[part 2 of 2: packages /SVC_DEF_Hierarchy/SVC_eBstActrSecDef/AppDataType to /Topologies/SDV/ImplementationTypes]
AUTOSAR XML (schema 00049)
package /SVC_DEF_Hierarchy/SVC_eBstActrSecDef/AppDataType
  application array data type VaBACR_y_UpIntegrationOutputS_VaBACR_y_UpIntegrationOutputS: category=ARRAY
    element hSVC_eBstActrSecVaBACR_y_UpIntegrationOutputS_D0S150: category=VALUE, type=BYTE, max-number-of-elements=150
  21 x app type, all with category=VALUE:
    hSVC_eBstActrSec_evt_VeBACR_e_PrimDiagStStsS_TeBACR_e_DiagStSts_SvcAppEnum
    hSVC_eBstActrSec_evt_VeBACR_e_SbmPrimDiagStStsS_TeBACR_e_SbmDiagStSts_SvcAppEnum
    hSVC_eBstActrSec_evt_VeBACR_e_eBstEPB_AchModeLtS_TeBACR_e_EPB_AchMode_SvcAppEnum
    hSVC_eBstActrSec_evt_VeBACR_e_eBstEPB_AchModeRtS_TeBACR_e_EPB_AchMode_SvcAppEnum
    hSVC_eBstActrSec_evt_VeBACR_e_eBstEPB_StateLtS_TeBACR_e_EPB_State_SvcAppEnum
    hSVC_eBstActrSec_evt_VeBACR_e_eBstEPB_StateRtS_TeBACR_e_EPB_State_SvcAppEnum
    hSVC_eBstActrSec_evt_VeBACR_e_eBstFluidLvlRawS_TeBACR_e_BrkFluidLvl_SvcAppEnum
    hSVC_eBstActrSec_evt_VeBACR_e_eBstHydFuncStS_TeBACR_e_eBstHydState_SvcAppEnum
    hSVC_eBstActrSec_evt_VeBACR_e_eBstIntrSelfTstStsS_TeBACR_e_IntrSelfTstSts_SvcAppEnum
    hSVC_eBstActrSec_evt_VeBACR_e_eBstMC_StsS_TeBACR_e_VldTrvlSnsrs_SvcAppEnum
    hSVC_eBstActrSec_evt_VeBACR_e_eBstPCanCommStsS_TeBACR_e_PCanCommSts_SvcAppEnum
    hSVC_eBstActrSec_evt_VeBACR_e_eBstPlngrPosnStsS_TeBPRR_e_ActPosnSts_SvcAppEnum
    hSVC_eBstActrSec_evt_VeBACR_e_eBstRplnshStsS_TeBACR_e_RplnshSts_SvcAppEnum
    hSVC_eBstActrSec_evt_VeBACR_e_eBstVDA_PbcHPO_ReqS_TeBACR_e_VDA_PbcHPO_Req_SvcAppEnum
    hSVC_eBstActrSec_evt_VeBACR_e_eBstWhlCntrlStsLfS_TeBACR_e_WhlCntrlSts_SvcAppEnum
    hSVC_eBstActrSec_evt_VeBACR_e_eBstWhlCntrlStsLrS_TeBACR_e_WhlCntrlSts_SvcAppEnum
    hSVC_eBstActrSec_evt_VeBACR_e_eBstWhlCntrlStsRfS_TeBACR_e_WhlCntrlSts_SvcAppEnum
    hSVC_eBstActrSec_evt_VeBACR_e_eBstWhlCntrlStsRrS_TeBACR_e_WhlCntrlSts_SvcAppEnum
    hSVC_eBstActrSec_evt_YeBACR_e_eBstEBOS_EBCMStateS_TeBACR_e_EBOS_EBCM_State_SvcAppEnum
    hSVC_eBstActrSec_evt_YeBACR_e_eBstEPB_StatusLtS_TeBACR_e_EPB_Status_SvcAppEnum
    hSVC_eBstActrSec_evt_YeBACR_e_eBstEPB_StatusRtS_TeBACR_e_EPB_Status_SvcAppEnum
  application record data type hSVC_eBstActrSec_evt_EventAppType: category=STRUCTURE
    116 x application record element:
      VeBACR_b_eBstWS_InvLrS: category=VALUE, type=TbBOOLEAN
      VeBACR_Cnt_eBstWS_TmD3_RrS: category=VALUE, type=T_COUNT_WORD
      VeBACR_b_eBstWS_InvLfS: category=VALUE, type=TbBOOLEAN
      VeBACR_Cnt_eBstWS_PulsRfS: category=VALUE, type=T_COUNT_WORD
      VeBACR_Cnt_eBstWS_VdaBitsLrS: category=VALUE, type=T_COUNT_BYTE
      VeBACR_Cnt_eBstWS_TmRfS: category=VALUE, type=T_COUNT_LONG
      VeBACR_Cnt_eBstWS_VdaBitsRfS: category=VALUE, type=T_COUNT_BYTE
      VeBACR_e_eBstEPB_StateLtS: category=VALUE, type=hSVC_eBstActrSec_evt_VeBACR_e_eBstEPB_StateLtS_TeBACR_e_EPB_State_SvcAppEnum
      VeBACR_b_eBstWS_InvRfS: category=VALUE, type=TbBOOLEAN
      VeBACR_e_eBstEPB_AchModeLtS: category=VALUE, type=hSVC_eBstActrSec_evt_VeBACR_e_eBstEPB_AchModeLtS_TeBACR_e_EPB_AchMode_SvcAppEnum
      VeBACR_Cnt_eBstWS_TmD1_LrS: category=VALUE, type=T_COUNT_WORD
      VeBACR_d_eBstWS_VdaBitsRfS: category=VALUE, type=WORD
      VeBACR_l_eBstPlngrPosnS: category=VALUE, type=T_l_Millimeters
      VeBACR_d_eBstWS_VdaBitsLrS: category=VALUE, type=WORD
      VeBACR_Cnt_eBstWS_TmRrS: category=VALUE, type=T_COUNT_LONG
      VeBACR_e_eBstEPB_StateRtS: category=VALUE, type=hSVC_eBstActrSec_evt_VeBACR_e_eBstEPB_StateRtS_TeBACR_e_EPB_State_SvcAppEnum
      VeBACR_p_eBstBkPrsEstRrS: category=VALUE, type=T_p_bar
      VeBACR_Cnt_eBstWS_PulsLrS: category=VALUE, type=T_COUNT_WORD
      VeBACR_e_eBstMC_StsS: category=VALUE, type=hSVC_eBstActrSec_evt_VeBACR_e_eBstMC_StsS_TeBACR_e_VldTrvlSnsrs_SvcAppEnum
      VeBACR_F_eBstEPB_AchvdRtS: category=VALUE, type=T_F_Newtons
      YeBACR_e_eBstEBOS_EBCMStateS: category=VALUE, type=hSVC_eBstActrSec_evt_YeBACR_e_eBstEBOS_EBCMStateS_TeBACR_e_EBOS_EBCM_State_SvcAppEnum
      VeBACR_b_eBstWS_StndStllLrS: category=VALUE, type=TbBOOLEAN
      VeBACR_Cnt_eBstWS_TmD2_RrS: category=VALUE, type=T_COUNT_WORD
      VeBACR_e_eBstIntrSelfTstStsS: category=VALUE, type=hSVC_eBstActrSec_evt_VeBACR_e_eBstIntrSelfTstStsS_TeBACR_e_IntrSelfTstSts_SvcAppEnum
      VeBACR_Cnt_eBstWS_TmLfS: category=VALUE, type=T_COUNT_LONG
      VeBACR_Cnt_eBstWS_PulsLfS: category=VALUE, type=T_COUNT_WORD
      VeBACR_e_eBstFluidLvlRawS: category=VALUE, type=hSVC_eBstActrSec_evt_VeBACR_e_eBstFluidLvlRawS_TeBACR_e_BrkFluidLvl_SvcAppEnum
      VeBACR_d_eBstWS_VdaBitsLfS: category=VALUE, type=WORD
      VeBACR_e_eBstPlngrPosnStsS: category=VALUE, type=hSVC_eBstActrSec_evt_VeBACR_e_eBstPlngrPosnStsS_TeBPRR_e_ActPosnSts_SvcAppEnum
      VeBACR_Cnt_eBstWS_TmD3_LrS: category=VALUE, type=T_COUNT_WORD
      VeBACR_l_eBstMCS: category=VALUE, type=T_l_Millimeters
      VeBACR_p_eBstMC_AchvdS: category=VALUE, type=T_p_bar
      VeBACR_b_eBst_BstWthWarningS: category=VALUE, type=TbBOOLEAN
      VeBACR_b_eBstPwrMgmtActS: category=VALUE, type=TbBOOLEAN
      VeBACR_Cnt_eBstWS_TmD2_LrS: category=VALUE, type=T_COUNT_WORD
      VeBACR_b_eBstWS_InvRrS: category=VALUE, type=TbBOOLEAN
      VeBACR_Cnt_eBstWS_PulsRrS: category=VALUE, type=T_COUNT_WORD
      VeBACR_p_eBstBkPrsEstLrS: category=VALUE, type=T_p_bar
      VeBACR_p_eBstBkPrsEstLfS: category=VALUE, type=T_p_bar
      VeBACR_Cnt_eBstWS_TmD1_RfS: category=VALUE, type=T_COUNT_WORD
      VeBACR_F_eBstEPB_AchvdLtS: category=VALUE, type=T_F_Newtons
      VeBACR_b_eBstWS_StndStllRfS: category=VALUE, type=TbBOOLEAN
      VeBACR_Cnt_eBstWS_TmD1_LfS: category=VALUE, type=T_COUNT_WORD
      VeBACR_b_eBstBC_AchvdInvS: category=VALUE, type=TbBOOLEAN
      VeBACR_b_eBstDgrdDBRReqstdS: category=VALUE, type=TbBOOLEAN
      VeBACR_Cnt_eBstWS_TmD2_LfS: category=VALUE, type=T_COUNT_WORD
      VeBACR_b_eBstWS_StndStllRrS: category=VALUE, type=TbBOOLEAN
      VeBACR_b_eBstWS_StndStllLfS: category=VALUE, type=TbBOOLEAN
      VeBACR_Cnt_eBstWS_TmD2_RfS: category=VALUE, type=T_COUNT_WORD
      VeBACR_p_eBstBkPrsEstRfS: category=VALUE, type=T_p_bar
      VeBACR_d_eBstWS_VdaBitsRrS: category=VALUE, type=WORD
      VeBACR_e_eBstEPB_AchModeRtS: category=VALUE, type=hSVC_eBstActrSec_evt_VeBACR_e_eBstEPB_AchModeRtS_TeBACR_e_EPB_AchMode_SvcAppEnum
      VeBACR_Cnt_eBstWS_TmD3_RfS: category=VALUE, type=T_COUNT_WORD
      VeBACR_Cnt_eBstWS_TmLrS: category=VALUE, type=T_COUNT_LONG
      VeBACR_d_eBstPwrMgmtRsnS: category=VALUE, type=WORD
      VeBACR_Cnt_eBstWS_TmD3_LfS: category=VALUE, type=T_COUNT_WORD
      VeBACR_b_eBstMC_AchvdInvS: category=VALUE, type=TbBOOLEAN
      YeBACR_Pct_eBstThermalCapS: category=VALUE, type=T_Pct_Percent
      VeBACR_Cnt_eBstWS_TmD1_RrS: category=VALUE, type=T_COUNT_WORD
      VeBACR_Cnt_eBstWS_VdaBitsRrS: category=VALUE, type=T_COUNT_BYTE
      VeBACR_Cnt_eBstWS_VdaBitsLfS: category=VALUE, type=T_COUNT_BYTE
      VeBACR_p_eBstBC_AchvdS: category=VALUE, type=T_p_bar
      VeBACR_Cnt_eBstWS_TmD8_RfS: category=VALUE, type=T_COUNT_WORD
      VeBACR_Cnt_eBstWS_TmD7_RrS: category=VALUE, type=T_COUNT_WORD
      VeBACR_b_eBstBrkActCurr2FA_S: category=VALUE, type=TbBOOLEAN
      VeBACR_U_eBstBrkActVolt2_S: category=VALUE, type=T_U_Volts
      VeBACR_Cnt_eBstWS_TmD8_LrS: category=VALUE, type=T_COUNT_WORD
      VeBACR_Cnt_eBstWS_TmD7_LfS: category=VALUE, type=T_COUNT_WORD
      VeBACR_Cnt_eBstWS_TmD4_LrS: category=VALUE, type=T_COUNT_WORD
      VeBACR_Cnt_eBstWS_TmD6_RfS: category=VALUE, type=T_COUNT_WORD
      VeBACR_Cnt_eBstWS_TmD5_RrS: category=VALUE, type=T_COUNT_WORD
      VeBACR_Cnt_eBstWS_TmD4_RfS: category=VALUE, type=T_COUNT_WORD
      VeBACR_Cnt_eBstWS_TmD6_LrS: category=VALUE, type=T_COUNT_WORD
      VeBACR_Cnt_eBstWS_TmD5_LfS: category=VALUE, type=T_COUNT_WORD
      VeBACR_b_eBstBrkActVolt2FA_S: category=VALUE, type=TbBOOLEAN
      VeBACR_U_eBstBrkActVolt1_S: category=VALUE, type=T_U_Volts
      VeBACR_Cnt_eBstWS_TmD7_LrS: category=VALUE, type=T_COUNT_WORD
      VeBACR_Cnt_eBstWS_TmD8_LfS: category=VALUE, type=T_COUNT_WORD
      VeBACR_Cnt_eBstWS_TmD7_RfS: category=VALUE, type=T_COUNT_WORD
      VeBACR_Cnt_eBstWS_TmD8_RrS: category=VALUE, type=T_COUNT_WORD
      VeBACR_b_eBstBrkActCurr1FA_S: category=VALUE, type=TbBOOLEAN
      VeBACR_I_eBstBrkActCurr2_S: category=VALUE, type=T_I_Amps
      VeBACR_Cnt_eBstWS_TmD4_RrS: category=VALUE, type=T_COUNT_WORD
      VeBACR_Cnt_eBstWS_TmD5_LrS: category=VALUE, type=T_COUNT_WORD
      VeBACR_Cnt_eBstWS_TmD6_LfS: category=VALUE, type=T_COUNT_WORD
      VeBACR_Cnt_eBstWS_TmD4_LfS: category=VALUE, type=T_COUNT_WORD
      VeBACR_Cnt_eBstWS_TmD6_RrS: category=VALUE, type=T_COUNT_WORD
      VeBACR_Cnt_eBstWS_TmD5_RfS: category=VALUE, type=T_COUNT_WORD
      VeBACR_b_eBstBrkActVolt1FA_S: category=VALUE, type=TbBOOLEAN
      VeBACR_b_eBstLeakModeActvS: category=VALUE, type=TbBOOLEAN
      VeBACR_b_eBstRecoveryActvS: category=VALUE, type=TbBOOLEAN
      VeBACR_I_eBstBrkActCurr1_S: category=VALUE, type=T_I_Amps
      VeBACR_V_eBstPotPlngrVolS: category=VALUE, type=T_V_Millimeters3
      VeBACR_e_eBstRplnshStsS: category=VALUE, type=hSVC_eBstActrSec_evt_VeBACR_e_eBstRplnshStsS_TeBACR_e_RplnshSts_SvcAppEnum
      VeBACR_V_eBstRemPlngrVolS: category=VALUE, type=T_V_Millimeters3
      VeBACR_p_eBstVDA_PbcHPO_S: category=VALUE, type=T_p_bar
      VeBACR_e_eBstVDA_PbcHPO_ReqS: category=VALUE, type=hSVC_eBstActrSec_evt_VeBACR_e_eBstVDA_PbcHPO_ReqS_TeBACR_e_VDA_PbcHPO_Req_SvcAppEnum
      VeBACR_e_eBstHydFuncStS: category=VALUE, type=hSVC_eBstActrSec_evt_VeBACR_e_eBstHydFuncStS_TeBACR_e_eBstHydState_SvcAppEnum
      YeBACR_b_eBst_BstUnavlblS: category=VALUE, type=TbBOOLEAN
      VeBACR_d_eBstEBCM_SwVerAlphS: category=VALUE, type=WORD
      VeBACR_g_eBstEBCM_SwVerPN_S: category=VALUE, type=LONGWORD
      VeBACR_b_eBstPCanCommStsS: category=VALUE, type=TbBOOLEAN
      VeBACR_V_eBstHydCmpOffstVolS: category=VALUE, type=T_V_Millimeters3
      VaBACR_y_UpIntegrationOutputS: category=ARRAY, type=VaBACR_y_UpIntegrationOutputS_VaBACR_y_UpIntegrationOutputS
      VeBACR_e_SbmPrimDiagStStsS: category=VALUE, type=hSVC_eBstActrSec_evt_VeBACR_e_SbmPrimDiagStStsS_TeBACR_e_SbmDiagStSts_SvcAppEnum
      VeBACR_e_eBstWhlCntrlStsLfS: category=VALUE, type=hSVC_eBstActrSec_evt_VeBACR_e_eBstWhlCntrlStsLfS_TeBACR_e_WhlCntrlSts_SvcAppEnum
      YeBACR_e_eBstEPB_StatusRtS: category=VALUE, type=hSVC_eBstActrSec_evt_YeBACR_e_eBstEPB_StatusRtS_TeBACR_e_EPB_Status_SvcAppEnum
      VeBACR_e_eBstWhlCntrlStsRrS: category=VALUE, type=hSVC_eBstActrSec_evt_VeBACR_e_eBstWhlCntrlStsRrS_TeBACR_e_WhlCntrlSts_SvcAppEnum
      VeBACR_e_eBstWhlCntrlStsLrS: category=VALUE, type=hSVC_eBstActrSec_evt_VeBACR_e_eBstWhlCntrlStsLrS_TeBACR_e_WhlCntrlSts_SvcAppEnum
      VeBACR_b_MIL_ReqFromEBCM_S: category=VALUE, type=TbBOOLEAN
      VeBACR_e_eBstWhlCntrlStsRfS: category=VALUE, type=hSVC_eBstActrSec_evt_VeBACR_e_eBstWhlCntrlStsRfS_TeBACR_e_WhlCntrlSts_SvcAppEnum
      YeBACR_e_eBstEPB_StatusLtS: category=VALUE, type=hSVC_eBstActrSec_evt_YeBACR_e_eBstEPB_StatusLtS_TeBACR_e_EPB_Status_SvcAppEnum
      VeBACR_e_PrimDiagStStsS: category=VALUE, type=hSVC_eBstActrSec_evt_VeBACR_e_PrimDiagStStsS_TeBACR_e_DiagStSts_SvcAppEnum
      VeBACR_e_eBstPCanCommStsS: category=VALUE, type=hSVC_eBstActrSec_evt_VeBACR_e_eBstPCanCommStsS_TeBACR_e_PCanCommSts_SvcAppEnum
      VeBACR_b_eBstPanicBrkAppActS: category=VALUE, type=TbBOOLEAN
      VeBACR_b_ThermalCapInvS: category=VALUE, type=TbBOOLEAN
package /SVC_DEF_Hierarchy/SVC_eBstActrSecDef/ImpDataType
  22 x impl type:
    hSVC_eBstActrSec_evt_EventImpType: category=STRUCTURE
      116 x element:
        VeBACR_b_eBstWS_InvLrS: implementation-data-type=TbBOOLEAN
        VeBACR_Cnt_eBstWS_TmD3_RrS: implementation-data-type=T_COUNT_WORD
        VeBACR_b_eBstWS_InvLfS: implementation-data-type=TbBOOLEAN
        VeBACR_Cnt_eBstWS_PulsRfS: implementation-data-type=T_COUNT_WORD
        VeBACR_Cnt_eBstWS_VdaBitsLrS: implementation-data-type=T_COUNT_BYTE
        VeBACR_Cnt_eBstWS_TmRfS: implementation-data-type=T_COUNT_LONG
        VeBACR_Cnt_eBstWS_VdaBitsRfS: implementation-data-type=T_COUNT_BYTE
        VeBACR_e_eBstEPB_StateLtS: implementation-data-type=hSVC_eBstActrSec_evt_VeBACR_e_eBstEPB_StateLtS_TeBACR_e_EPB_State_SvcEnum
        VeBACR_b_eBstWS_InvRfS: implementation-data-type=TbBOOLEAN
        VeBACR_e_eBstEPB_AchModeLtS: implementation-data-type=hSVC_eBstActrSec_evt_VeBACR_e_eBstEPB_AchModeLtS_TeBACR_e_EPB_AchMode_SvcEnum
        VeBACR_Cnt_eBstWS_TmD1_LrS: implementation-data-type=T_COUNT_WORD
        VeBACR_d_eBstWS_VdaBitsRfS: implementation-data-type=WORD
        VeBACR_l_eBstPlngrPosnS: implementation-data-type=T_l_Millimeters
        VeBACR_d_eBstWS_VdaBitsLrS: implementation-data-type=WORD
        VeBACR_Cnt_eBstWS_TmRrS: implementation-data-type=T_COUNT_LONG
        VeBACR_e_eBstEPB_StateRtS: implementation-data-type=hSVC_eBstActrSec_evt_VeBACR_e_eBstEPB_StateRtS_TeBACR_e_EPB_State_SvcEnum
        VeBACR_p_eBstBkPrsEstRrS: implementation-data-type=T_p_bar
        VeBACR_Cnt_eBstWS_PulsLrS: implementation-data-type=T_COUNT_WORD
        VeBACR_e_eBstMC_StsS: implementation-data-type=hSVC_eBstActrSec_evt_VeBACR_e_eBstMC_StsS_TeBACR_e_VldTrvlSnsrs_SvcEnum
        VeBACR_F_eBstEPB_AchvdRtS: implementation-data-type=T_F_Newtons
        YeBACR_e_eBstEBOS_EBCMStateS: implementation-data-type=hSVC_eBstActrSec_evt_YeBACR_e_eBstEBOS_EBCMStateS_TeBACR_e_EBOS_EBCM_State_SvcEnum
        VeBACR_b_eBstWS_StndStllLrS: implementation-data-type=TbBOOLEAN
        VeBACR_Cnt_eBstWS_TmD2_RrS: implementation-data-type=T_COUNT_WORD
        VeBACR_e_eBstIntrSelfTstStsS: implementation-data-type=hSVC_eBstActrSec_evt_VeBACR_e_eBstIntrSelfTstStsS_TeBACR_e_IntrSelfTstSts_SvcEnum
        VeBACR_Cnt_eBstWS_TmLfS: implementation-data-type=T_COUNT_LONG
        VeBACR_Cnt_eBstWS_PulsLfS: implementation-data-type=T_COUNT_WORD
        VeBACR_e_eBstFluidLvlRawS: implementation-data-type=hSVC_eBstActrSec_evt_VeBACR_e_eBstFluidLvlRawS_TeBACR_e_BrkFluidLvl_SvcEnum
        VeBACR_d_eBstWS_VdaBitsLfS: implementation-data-type=WORD
        VeBACR_e_eBstPlngrPosnStsS: implementation-data-type=hSVC_eBstActrSec_evt_VeBACR_e_eBstPlngrPosnStsS_TeBPRR_e_ActPosnSts_SvcEnum
        VeBACR_Cnt_eBstWS_TmD3_LrS: implementation-data-type=T_COUNT_WORD
        VeBACR_l_eBstMCS: implementation-data-type=T_l_Millimeters
        VeBACR_p_eBstMC_AchvdS: implementation-data-type=T_p_bar
        VeBACR_b_eBst_BstWthWarningS: implementation-data-type=TbBOOLEAN
        VeBACR_b_eBstPwrMgmtActS: implementation-data-type=TbBOOLEAN
        VeBACR_Cnt_eBstWS_TmD2_LrS: implementation-data-type=T_COUNT_WORD
        VeBACR_b_eBstWS_InvRrS: implementation-data-type=TbBOOLEAN
        VeBACR_Cnt_eBstWS_PulsRrS: implementation-data-type=T_COUNT_WORD
        VeBACR_p_eBstBkPrsEstLrS: implementation-data-type=T_p_bar
        VeBACR_p_eBstBkPrsEstLfS: implementation-data-type=T_p_bar
        VeBACR_Cnt_eBstWS_TmD1_RfS: implementation-data-type=T_COUNT_WORD
        VeBACR_F_eBstEPB_AchvdLtS: implementation-data-type=T_F_Newtons
        VeBACR_b_eBstWS_StndStllRfS: implementation-data-type=TbBOOLEAN
        VeBACR_Cnt_eBstWS_TmD1_LfS: implementation-data-type=T_COUNT_WORD
        VeBACR_b_eBstBC_AchvdInvS: implementation-data-type=TbBOOLEAN
        VeBACR_b_eBstDgrdDBRReqstdS: implementation-data-type=TbBOOLEAN
        VeBACR_Cnt_eBstWS_TmD2_LfS: implementation-data-type=T_COUNT_WORD
        VeBACR_b_eBstWS_StndStllRrS: implementation-data-type=TbBOOLEAN
        VeBACR_b_eBstWS_StndStllLfS: implementation-data-type=TbBOOLEAN
        VeBACR_Cnt_eBstWS_TmD2_RfS: implementation-data-type=T_COUNT_WORD
        VeBACR_p_eBstBkPrsEstRfS: implementation-data-type=T_p_bar
        VeBACR_d_eBstWS_VdaBitsRrS: implementation-data-type=WORD
        VeBACR_e_eBstEPB_AchModeRtS: implementation-data-type=hSVC_eBstActrSec_evt_VeBACR_e_eBstEPB_AchModeRtS_TeBACR_e_EPB_AchMode_SvcEnum
        VeBACR_Cnt_eBstWS_TmD3_RfS: implementation-data-type=T_COUNT_WORD
        VeBACR_Cnt_eBstWS_TmLrS: implementation-data-type=T_COUNT_LONG
        VeBACR_d_eBstPwrMgmtRsnS: implementation-data-type=WORD
        VeBACR_Cnt_eBstWS_TmD3_LfS: implementation-data-type=T_COUNT_WORD
        VeBACR_b_eBstMC_AchvdInvS: implementation-data-type=TbBOOLEAN
        YeBACR_Pct_eBstThermalCapS: implementation-data-type=T_Pct_Percent
        VeBACR_Cnt_eBstWS_TmD1_RrS: implementation-data-type=T_COUNT_WORD
        VeBACR_Cnt_eBstWS_VdaBitsRrS: implementation-data-type=T_COUNT_BYTE
        VeBACR_Cnt_eBstWS_VdaBitsLfS: implementation-data-type=T_COUNT_BYTE
        VeBACR_p_eBstBC_AchvdS: implementation-data-type=T_p_bar
        VeBACR_Cnt_eBstWS_TmD8_RfS: implementation-data-type=T_COUNT_WORD
        VeBACR_Cnt_eBstWS_TmD7_RrS: implementation-data-type=T_COUNT_WORD
        VeBACR_b_eBstBrkActCurr2FA_S: implementation-data-type=TbBOOLEAN
        VeBACR_U_eBstBrkActVolt2_S: implementation-data-type=T_U_Volts
        VeBACR_Cnt_eBstWS_TmD8_LrS: implementation-data-type=T_COUNT_WORD
        VeBACR_Cnt_eBstWS_TmD7_LfS: implementation-data-type=T_COUNT_WORD
        VeBACR_Cnt_eBstWS_TmD4_LrS: implementation-data-type=T_COUNT_WORD
        VeBACR_Cnt_eBstWS_TmD6_RfS: implementation-data-type=T_COUNT_WORD
        VeBACR_Cnt_eBstWS_TmD5_RrS: implementation-data-type=T_COUNT_WORD
        VeBACR_Cnt_eBstWS_TmD4_RfS: implementation-data-type=T_COUNT_WORD
        VeBACR_Cnt_eBstWS_TmD6_LrS: implementation-data-type=T_COUNT_WORD
        VeBACR_Cnt_eBstWS_TmD5_LfS: implementation-data-type=T_COUNT_WORD
        VeBACR_b_eBstBrkActVolt2FA_S: implementation-data-type=TbBOOLEAN
        VeBACR_U_eBstBrkActVolt1_S: implementation-data-type=T_U_Volts
        VeBACR_Cnt_eBstWS_TmD7_LrS: implementation-data-type=T_COUNT_WORD
        VeBACR_Cnt_eBstWS_TmD8_LfS: implementation-data-type=T_COUNT_WORD
        VeBACR_Cnt_eBstWS_TmD7_RfS: implementation-data-type=T_COUNT_WORD
        VeBACR_Cnt_eBstWS_TmD8_RrS: implementation-data-type=T_COUNT_WORD
        VeBACR_b_eBstBrkActCurr1FA_S: implementation-data-type=TbBOOLEAN
        VeBACR_I_eBstBrkActCurr2_S: implementation-data-type=T_I_Amps
        VeBACR_Cnt_eBstWS_TmD4_RrS: implementation-data-type=T_COUNT_WORD
        VeBACR_Cnt_eBstWS_TmD5_LrS: implementation-data-type=T_COUNT_WORD
        VeBACR_Cnt_eBstWS_TmD6_LfS: implementation-data-type=T_COUNT_WORD
        VeBACR_Cnt_eBstWS_TmD4_LfS: implementation-data-type=T_COUNT_WORD
        VeBACR_Cnt_eBstWS_TmD6_RrS: implementation-data-type=T_COUNT_WORD
        VeBACR_Cnt_eBstWS_TmD5_RfS: implementation-data-type=T_COUNT_WORD
        VeBACR_b_eBstBrkActVolt1FA_S: implementation-data-type=TbBOOLEAN
        VeBACR_b_eBstLeakModeActvS: implementation-data-type=TbBOOLEAN
        VeBACR_b_eBstRecoveryActvS: implementation-data-type=TbBOOLEAN
        VeBACR_I_eBstBrkActCurr1_S: implementation-data-type=T_I_Amps
        VeBACR_V_eBstPotPlngrVolS: implementation-data-type=T_V_Millimeters3
        VeBACR_e_eBstRplnshStsS: implementation-data-type=hSVC_eBstActrSec_evt_VeBACR_e_eBstRplnshStsS_TeBACR_e_RplnshSts_SvcEnum
        VeBACR_V_eBstRemPlngrVolS: implementation-data-type=T_V_Millimeters3
        VeBACR_p_eBstVDA_PbcHPO_S: implementation-data-type=T_p_bar
        VeBACR_e_eBstVDA_PbcHPO_ReqS: implementation-data-type=hSVC_eBstActrSec_evt_VeBACR_e_eBstVDA_PbcHPO_ReqS_TeBACR_e_VDA_PbcHPO_Req_SvcEnum
        VeBACR_e_eBstHydFuncStS: implementation-data-type=hSVC_eBstActrSec_evt_VeBACR_e_eBstHydFuncStS_TeBACR_e_eBstHydState_SvcEnum
        YeBACR_b_eBst_BstUnavlblS: implementation-data-type=TbBOOLEAN
        VeBACR_d_eBstEBCM_SwVerAlphS: implementation-data-type=WORD
        VeBACR_g_eBstEBCM_SwVerPN_S: implementation-data-type=LONGWORD
        VeBACR_b_eBstPCanCommStsS: implementation-data-type=TbBOOLEAN
        VeBACR_V_eBstHydCmpOffstVolS: implementation-data-type=T_V_Millimeters3
        VaBACR_y_UpIntegrationOutputS: category=ARRAY
          element hSVC_eBstActrSecVaBACR_y_UpIntegrationOutputS_D0S150: array-size=150, implementation-data-type=BYTE
        VeBACR_e_SbmPrimDiagStStsS: implementation-data-type=hSVC_eBstActrSec_evt_VeBACR_e_SbmPrimDiagStStsS_TeBACR_e_SbmDiagStSts_SvcEnum
        VeBACR_e_eBstWhlCntrlStsLfS: implementation-data-type=hSVC_eBstActrSec_evt_VeBACR_e_eBstWhlCntrlStsLfS_TeBACR_e_WhlCntrlSts_SvcEnum
        YeBACR_e_eBstEPB_StatusRtS: implementation-data-type=hSVC_eBstActrSec_evt_YeBACR_e_eBstEPB_StatusRtS_TeBACR_e_EPB_Status_SvcEnum
        VeBACR_e_eBstWhlCntrlStsRrS: implementation-data-type=hSVC_eBstActrSec_evt_VeBACR_e_eBstWhlCntrlStsRrS_TeBACR_e_WhlCntrlSts_SvcEnum
        VeBACR_e_eBstWhlCntrlStsLrS: implementation-data-type=hSVC_eBstActrSec_evt_VeBACR_e_eBstWhlCntrlStsLrS_TeBACR_e_WhlCntrlSts_SvcEnum
        VeBACR_b_MIL_ReqFromEBCM_S: implementation-data-type=TbBOOLEAN
        VeBACR_e_eBstWhlCntrlStsRfS: implementation-data-type=hSVC_eBstActrSec_evt_VeBACR_e_eBstWhlCntrlStsRfS_TeBACR_e_WhlCntrlSts_SvcEnum
        YeBACR_e_eBstEPB_StatusLtS: implementation-data-type=hSVC_eBstActrSec_evt_YeBACR_e_eBstEPB_StatusLtS_TeBACR_e_EPB_Status_SvcEnum
        VeBACR_e_PrimDiagStStsS: implementation-data-type=hSVC_eBstActrSec_evt_VeBACR_e_PrimDiagStStsS_TeBACR_e_DiagStSts_SvcEnum
        VeBACR_e_eBstPCanCommStsS: implementation-data-type=hSVC_eBstActrSec_evt_VeBACR_e_eBstPCanCommStsS_TeBACR_e_PCanCommSts_SvcEnum
        VeBACR_b_eBstPanicBrkAppActS: implementation-data-type=TbBOOLEAN
        VeBACR_b_ThermalCapInvS: implementation-data-type=TbBOOLEAN
    hSVC_eBstActrSec_evt_VeBACR_e_PrimDiagStStsS_TeBACR_e_DiagStSts_SvcEnum:
      category=VALUE
      base-type=sint16
      compu {1=Ce_hSVC_eBstActrSec_evt_VeBACR_e_PrimDiagStStsS_BACR_e_DiagSts_TestActv, 0=Ce_hSVC_eBstActrSec_evt_VeBACR_e_PrimDiagStStsS_BACR_e_DiagSts_NotActv, 2=Ce_hSVC_eBstActrSec_evt_VeBACR_e_PrimDiagStStsS_BACR_e_DiagSts_TestCmplt, 4=Ce_hSVC_eBstActrSec_evt_VeBACR_e_PrimDiagStStsS_BACR_e_DiagSts_TstCndNtMet, 3=Ce_hSVC_eBstActrSec_evt_VeBACR_e_PrimDiagStStsS_BACR_e_DiagSts_TestFail}
    hSVC_eBstActrSec_evt_VeBACR_e_SbmPrimDiagStStsS_TeBACR_e_SbmDiagStSts_SvcEnum: category=VALUE, base-type=sint16, compu {1=Ce_hSVC_eBstActrSec_evt_VeBACR_e_SbmPrimDiagStStsS_BACR_e_DiagState1, 2=Ce_hSVC_eBstActrSec_evt_VeBACR_e_SbmPrimDiagStStsS_BACR_e_DiagState2, 0=Ce_hSVC_eBstActrSec_evt_VeBACR_e_SbmPrimDiagStStsS_BACR_e_NoDiagReq, 3=Ce_hSVC_eBstActrSec_evt_VeBACR_e_SbmPrimDiagStStsS_BACR_e_DiagState3, 4=Ce_hSVC_eBstActrSec_evt_VeBACR_e_SbmPrimDiagStStsS_BACR_e_CondNotMet}
    hSVC_eBstActrSec_evt_VeBACR_e_eBstEPB_AchModeLtS_TeBACR_e_EPB_AchMode_SvcEnum:
      category=VALUE
      base-type=sint16
      compu {0=Ce_hSVC_eBstActrSec_evt_VeBACR_e_eBstEPB_AchModeLtS_BACR_e_EPB_InNone, 4=Ce_hSVC_eBstActrSec_evt_VeBACR_e_eBstEPB_AchModeLtS_BACR_e_EPB_InRollerBenchApply, 22=Ce_hSVC_eBstActrSec_evt_VeBACR_e_eBstEPB_AchModeLtS_BACR_e_EPB_InServiceRelease, 25=Ce_hSVC_eBstActrSec_evt_VeBACR_e_eBstEPB_AchModeLtS_BACR_e_EPB_InPadAdjustment, 23=Ce_hSVC_eBstActrSec_evt_VeBACR_e_eBstEPB_AchModeLtS_BACR_e_EPB_InNoBoostEPBAst, 24=Ce_hSVC_eBstActrSec_evt_VeBACR_e_eBstEPB_AchModeLtS_BACR_e_EPB_InDynamicApply, 21=Ce_hSVC_eBstActrSec_evt_VeBACR_e_eBstEPB_AchModeLtS_BACR_e_EPB_InAssemblyCheck}
    hSVC_eBstActrSec_evt_VeBACR_e_eBstEPB_AchModeRtS_TeBACR_e_EPB_AchMode_SvcEnum:
      category=VALUE
      base-type=sint16
      compu {0=Ce_hSVC_eBstActrSec_evt_VeBACR_e_eBstEPB_AchModeRtS_BACR_e_EPB_InNone, 25=Ce_hSVC_eBstActrSec_evt_VeBACR_e_eBstEPB_AchModeRtS_BACR_e_EPB_InPadAdjustment, 21=Ce_hSVC_eBstActrSec_evt_VeBACR_e_eBstEPB_AchModeRtS_BACR_e_EPB_InAssemblyCheck, 24=Ce_hSVC_eBstActrSec_evt_VeBACR_e_eBstEPB_AchModeRtS_BACR_e_EPB_InDynamicApply, 4=Ce_hSVC_eBstActrSec_evt_VeBACR_e_eBstEPB_AchModeRtS_BACR_e_EPB_InRollerBenchApply, 23=Ce_hSVC_eBstActrSec_evt_VeBACR_e_eBstEPB_AchModeRtS_BACR_e_EPB_InNoBoostEPBAst, 22=Ce_hSVC_eBstActrSec_evt_VeBACR_e_eBstEPB_AchModeRtS_BACR_e_EPB_InServiceRelease}
    hSVC_eBstActrSec_evt_VeBACR_e_eBstEPB_StateLtS_TeBACR_e_EPB_State_SvcEnum:
      category=VALUE
      base-type=sint16
      compu {17=Ce_hSVC_eBstActrSec_evt_VeBACR_e_eBstEPB_StateLtS_BACR_e_EPB_Releasing, 0=Ce_hSVC_eBstActrSec_evt_VeBACR_e_eBstEPB_StateLtS_BACR_e_EPB_Unknown, 1=Ce_hSVC_eBstActrSec_evt_VeBACR_e_eBstEPB_StateLtS_BACR_e_EPB_Applying, 2=Ce_hSVC_eBstActrSec_evt_VeBACR_e_eBstEPB_StateLtS_BACR_e_EPB_Applied, 18=Ce_hSVC_eBstActrSec_evt_VeBACR_e_eBstEPB_StateLtS_BACR_e_EPB_Released}
    hSVC_eBstActrSec_evt_VeBACR_e_eBstEPB_StateRtS_TeBACR_e_EPB_State_SvcEnum:
      category=VALUE
      base-type=sint16
      compu {2=Ce_hSVC_eBstActrSec_evt_VeBACR_e_eBstEPB_StateRtS_BACR_e_EPB_Applied, 1=Ce_hSVC_eBstActrSec_evt_VeBACR_e_eBstEPB_StateRtS_BACR_e_EPB_Applying, 0=Ce_hSVC_eBstActrSec_evt_VeBACR_e_eBstEPB_StateRtS_BACR_e_EPB_Unknown, 18=Ce_hSVC_eBstActrSec_evt_VeBACR_e_eBstEPB_StateRtS_BACR_e_EPB_Released, 17=Ce_hSVC_eBstActrSec_evt_VeBACR_e_eBstEPB_StateRtS_BACR_e_EPB_Releasing}
    hSVC_eBstActrSec_evt_VeBACR_e_eBstFluidLvlRawS_TeBACR_e_BrkFluidLvl_SvcEnum: category=VALUE, base-type=sint16, compu {3=Ce_hSVC_eBstActrSec_evt_VeBACR_e_eBstFluidLvlRawS_BACR_e_BrkFluidLvlFailed, 0=Ce_hSVC_eBstActrSec_evt_VeBACR_e_eBstFluidLvlRawS_BACR_e_BrkFluidLvlNormal, 1=Ce_hSVC_eBstActrSec_evt_VeBACR_e_eBstFluidLvlRawS_BACR_e_BrkFluidLvlLow, 2=Ce_hSVC_eBstActrSec_evt_VeBACR_e_eBstFluidLvlRawS_BACR_e_BrkFluidLvlCritLow}
    hSVC_eBstActrSec_evt_VeBACR_e_eBstHydFuncStS_TeBACR_e_eBstHydState_SvcEnum:
      category=VALUE
      base-type=sint16
      compu {3=Ce_hSVC_eBstActrSec_evt_VeBACR_e_eBstHydFuncStS_BACR_e_eBstNoBoost, 0=Ce_hSVC_eBstActrSec_evt_VeBACR_e_eBstHydFuncStS_BACR_e_eBstHydNormal, 4=Ce_hSVC_eBstActrSec_evt_VeBACR_e_eBstHydFuncStS_BACR_e_eBstNoBoostWithIso, 6=Ce_hSVC_eBstActrSec_evt_VeBACR_e_eBstHydFuncStS_BACR_e_eBstBoostReqWthDfrrd, 1=Ce_hSVC_eBstActrSec_evt_VeBACR_e_eBstHydFuncStS_BACR_e_eBstHydHalfSystem1, 5=Ce_hSVC_eBstActrSec_evt_VeBACR_e_eBstHydFuncStS_BACR_e_eBstHydLeakDetection, 2=Ce_hSVC_eBstActrSec_evt_VeBACR_e_eBstHydFuncStS_BACR_e_eBstHydHalfSystem2}
    hSVC_eBstActrSec_evt_VeBACR_e_eBstIntrSelfTstStsS_TeBACR_e_IntrSelfTstSts_SvcEnum:
      category=VALUE
      base-type=sint16
      compu {1=Ce_hSVC_eBstActrSec_evt_VeBACR_e_eBstIntrSelfTstStsS_BACR_e_SelfTstActive, 3=Ce_hSVC_eBstActrSec_evt_VeBACR_e_eBstIntrSelfTstStsS_BACR_e_SelfTstRetry, 4=Ce_hSVC_eBstActrSec_evt_VeBACR_e_eBstIntrSelfTstStsS_BACR_e_SelfTstComplete, 2=Ce_hSVC_eBstActrSec_evt_VeBACR_e_eBstIntrSelfTstStsS_BACR_e_SelfTstAborted, 0=Ce_hSVC_eBstActrSec_evt_VeBACR_e_eBstIntrSelfTstStsS_BACR_e_SelfTstNotActive}
    hSVC_eBstActrSec_evt_VeBACR_e_eBstMC_StsS_TeBACR_e_VldTrvlSnsrs_SvcEnum: category=VALUE, base-type=sint16, compu {2=Ce_hSVC_eBstActrSec_evt_VeBACR_e_eBstMC_StsS_BACR_e_Two_VldSnrs, 1=Ce_hSVC_eBstActrSec_evt_VeBACR_e_eBstMC_StsS_BACR_e_One_VldSnr, 0=Ce_hSVC_eBstActrSec_evt_VeBACR_e_eBstMC_StsS_BACR_e_Zero_VldSnrs}
    hSVC_eBstActrSec_evt_VeBACR_e_eBstPCanCommStsS_TeBACR_e_PCanCommSts_SvcEnum: category=VALUE, base-type=sint16, compu {0=Ce_hSVC_eBstActrSec_evt_VeBACR_e_eBstPCanCommStsS_BACR_e_PCanStsUnknown, 2=Ce_hSVC_eBstActrSec_evt_VeBACR_e_eBstPCanCommStsS_BACR_e_PCanStsFailed, 1=Ce_hSVC_eBstActrSec_evt_VeBACR_e_eBstPCanCommStsS_BACR_e_PCanStsNormal}
    hSVC_eBstActrSec_evt_VeBACR_e_eBstPlngrPosnStsS_TeBPRR_e_ActPosnSts_SvcEnum: category=VALUE, base-type=sint16, compu {1=Ce_hSVC_eBstActrSec_evt_VeBACR_e_eBstPlngrPosnStsS_BPRR_e_PosnUnknown, 3=Ce_hSVC_eBstActrSec_evt_VeBACR_e_eBstPlngrPosnStsS_BPRR_e_PosnFailed, 0=Ce_hSVC_eBstActrSec_evt_VeBACR_e_eBstPlngrPosnStsS_BPRR_e_PosnInit, 2=Ce_hSVC_eBstActrSec_evt_VeBACR_e_eBstPlngrPosnStsS_BPRR_e_PosnLearned}
    hSVC_eBstActrSec_evt_VeBACR_e_eBstRplnshStsS_TeBACR_e_RplnshSts_SvcEnum:
      category=VALUE
      base-type=sint16
      compu {0=Ce_hSVC_eBstActrSec_evt_VeBACR_e_eBstRplnshStsS_BACR_e_RplnshUnavailable, 3=Ce_hSVC_eBstActrSec_evt_VeBACR_e_eBstRplnshStsS_BACR_e_AvailLastEvntAbortd, 7=Ce_hSVC_eBstActrSec_evt_VeBACR_e_eBstRplnshStsS_BACR_e_RplnshFailed, 4=Ce_hSVC_eBstActrSec_evt_VeBACR_e_eBstRplnshStsS_BACR_e_ActvPrep, 2=Ce_hSVC_eBstActrSec_evt_VeBACR_e_eBstRplnshStsS_BACR_e_AvailLastEvntIntrptd, 6=Ce_hSVC_eBstActrSec_evt_VeBACR_e_eBstRplnshStsS_BACR_e_ActvTransn, 5=Ce_hSVC_eBstActrSec_evt_VeBACR_e_eBstRplnshStsS_BACR_e_ActvRplnsh, 1=Ce_hSVC_eBstActrSec_evt_VeBACR_e_eBstRplnshStsS_BACR_e_AvailLastEvntSuccsess}
    hSVC_eBstActrSec_evt_VeBACR_e_eBstVDA_PbcHPO_ReqS_TeBACR_e_VDA_PbcHPO_Req_SvcEnum: category=VALUE, base-type=sint16, compu {2=Ce_hSVC_eBstActrSec_evt_VeBACR_e_eBstVDA_PbcHPO_ReqS_BACR_e_VdA_PbcHPO_ReqMax, 1=Ce_hSVC_eBstActrSec_evt_VeBACR_e_eBstVDA_PbcHPO_ReqS_BACR_e_VDA_PbcHPO_ReqNormal, 0=Ce_hSVC_eBstActrSec_evt_VeBACR_e_eBstVDA_PbcHPO_ReqS_BACR_e_VDA_PbcHPO_ReqNone}
    hSVC_eBstActrSec_evt_VeBACR_e_eBstWhlCntrlStsLfS_TeBACR_e_WhlCntrlSts_SvcEnum: category=VALUE, base-type=sint16, compu {0=Ce_hSVC_eBstActrSec_evt_VeBACR_e_eBstWhlCntrlStsLfS_BACR_e_Normal, 3=Ce_hSVC_eBstActrSec_evt_VeBACR_e_eBstWhlCntrlStsLfS_BACR_e_UnblMdfyPress, 2=Ce_hSVC_eBstActrSec_evt_VeBACR_e_eBstWhlCntrlStsLfS_BACR_e_UnblDecrPress, 1=Ce_hSVC_eBstActrSec_evt_VeBACR_e_eBstWhlCntrlStsLfS_BACR_e_UnblBuildPress}
    hSVC_eBstActrSec_evt_VeBACR_e_eBstWhlCntrlStsLrS_TeBACR_e_WhlCntrlSts_SvcEnum: category=VALUE, base-type=sint16, compu {1=Ce_hSVC_eBstActrSec_evt_VeBACR_e_eBstWhlCntrlStsLrS_BACR_e_UnblBuildPress, 0=Ce_hSVC_eBstActrSec_evt_VeBACR_e_eBstWhlCntrlStsLrS_BACR_e_Normal, 3=Ce_hSVC_eBstActrSec_evt_VeBACR_e_eBstWhlCntrlStsLrS_BACR_e_UnblMdfyPress, 2=Ce_hSVC_eBstActrSec_evt_VeBACR_e_eBstWhlCntrlStsLrS_BACR_e_UnblDecrPress}
    hSVC_eBstActrSec_evt_VeBACR_e_eBstWhlCntrlStsRfS_TeBACR_e_WhlCntrlSts_SvcEnum: category=VALUE, base-type=sint16, compu {3=Ce_hSVC_eBstActrSec_evt_VeBACR_e_eBstWhlCntrlStsRfS_BACR_e_UnblMdfyPress, 1=Ce_hSVC_eBstActrSec_evt_VeBACR_e_eBstWhlCntrlStsRfS_BACR_e_UnblBuildPress, 0=Ce_hSVC_eBstActrSec_evt_VeBACR_e_eBstWhlCntrlStsRfS_BACR_e_Normal, 2=Ce_hSVC_eBstActrSec_evt_VeBACR_e_eBstWhlCntrlStsRfS_BACR_e_UnblDecrPress}
    hSVC_eBstActrSec_evt_VeBACR_e_eBstWhlCntrlStsRrS_TeBACR_e_WhlCntrlSts_SvcEnum: category=VALUE, base-type=sint16, compu {3=Ce_hSVC_eBstActrSec_evt_VeBACR_e_eBstWhlCntrlStsRrS_BACR_e_UnblMdfyPress, 0=Ce_hSVC_eBstActrSec_evt_VeBACR_e_eBstWhlCntrlStsRrS_BACR_e_Normal, 1=Ce_hSVC_eBstActrSec_evt_VeBACR_e_eBstWhlCntrlStsRrS_BACR_e_UnblBuildPress, 2=Ce_hSVC_eBstActrSec_evt_VeBACR_e_eBstWhlCntrlStsRrS_BACR_e_UnblDecrPress}
    hSVC_eBstActrSec_evt_YeBACR_e_eBstEBOS_EBCMStateS_TeBACR_e_EBOS_EBCM_State_SvcEnum:
      category=VALUE
      base-type=sint16
      compu {1=Ce_hSVC_eBstActrSec_evt_YeBACR_e_eBstEBOS_EBCMStateS_BACR_e_EBOS_EBCM_Init, 2=Ce_hSVC_eBstActrSec_evt_YeBACR_e_eBstEBOS_EBCMStateS_BACR_e_EBOS_EBCM_PreOprtn, 5=Ce_hSVC_eBstActrSec_evt_YeBACR_e_eBstEBOS_EBCMStateS_BACR_e_EBOS_EBCM_HouseKeep, 0=Ce_hSVC_eBstActrSec_evt_YeBACR_e_eBstEBOS_EBCMStateS_BACR_e_EBOS_EBCM_Off, 4=Ce_hSVC_eBstActrSec_evt_YeBACR_e_eBstEBOS_EBCMStateS_BACR_e_EBOS_EBCM_FuncOprtn, 3=Ce_hSVC_eBstActrSec_evt_YeBACR_e_eBstEBOS_EBCMStateS_BACR_e_EBOS_EBCM_RdntOprtn}
    hSVC_eBstActrSec_evt_YeBACR_e_eBstEPB_StatusLtS_TeBACR_e_EPB_Status_SvcEnum: category=VALUE, base-type=sint16, compu {1=Ce_hSVC_eBstActrSec_evt_YeBACR_e_eBstEPB_StatusLtS_BACR_e_EPB_Normal, 0=Ce_hSVC_eBstActrSec_evt_YeBACR_e_eBstEPB_StatusLtS_BACR_e_EPB_Initializing, 2=Ce_hSVC_eBstActrSec_evt_YeBACR_e_eBstEPB_StatusLtS_BACR_e_EPB_Failed, 3=Ce_hSVC_eBstActrSec_evt_YeBACR_e_eBstEPB_StatusLtS_BACR_e_EPB_AsmblyChckIncmplt}
    hSVC_eBstActrSec_evt_YeBACR_e_eBstEPB_StatusRtS_TeBACR_e_EPB_Status_SvcEnum: category=VALUE, base-type=sint16, compu {1=Ce_hSVC_eBstActrSec_evt_YeBACR_e_eBstEPB_StatusRtS_BACR_e_EPB_Normal, 0=Ce_hSVC_eBstActrSec_evt_YeBACR_e_eBstEPB_StatusRtS_BACR_e_EPB_Initializing, 2=Ce_hSVC_eBstActrSec_evt_YeBACR_e_eBstEPB_StatusRtS_BACR_e_EPB_Failed, 3=Ce_hSVC_eBstActrSec_evt_YeBACR_e_eBstEPB_StatusRtS_BACR_e_EPB_AsmblyChckIncmplt}
package /Security
  secure communication props set Security_Configuration_Package
    secure communication authentication props AuthenticationConfiguration_GMSecOCProfile1: category=GMSecOCProfile1, auth-info-tx-length=128
    secure communication freshness props FreshnessConfiguration_GMSecOCProfile1: category=GMSecOCProfile1, freshness-counter-sync-attempts=2, freshness-value-length=64, freshness-value-tx-length=64
package /Security/SecocConfiguration
  crypto service key CryptoServiceKey_GMCustom_Profile1: algorithm-family=CRYPTO_ALGOFAM_AES, length=128
  crypto service primitive Authentication_GMCustom_Profile1: algorithm-family=CRYPTO_ALGOFAM_AES, algorithm-mode=CRYPTO_ALGOMODE_CMAC
package /System
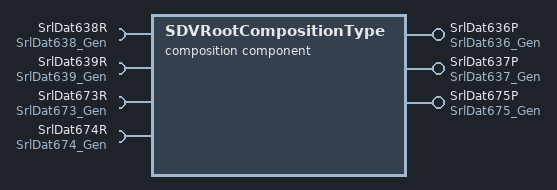
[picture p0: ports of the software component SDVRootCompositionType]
  composition sw component type SDVRootCompositionType
    provide port SrlDat636P: provided-interface=SrlDat636_Gen
    provide port SrlDat637P: provided-interface=SrlDat637_Gen
    provide port SrlDat675P: provided-interface=SrlDat675_Gen
    4 x require port:
      SrlDat638R: required-interface=SrlDat638_Gen
      SrlDat639R: required-interface=SrlDat639_Gen
      SrlDat673R: required-interface=SrlDat673_Gen
      SrlDat674R: required-interface=SrlDat674_Gen
    component EBCM_ETH_CompositionPrototype: type=EBCM_ETH_CompositionType
    delegate EBCM_ETH_CompositionPrototype.SrlDat636P <-> outer port SDVRootCompositionType/SrlDat636P
    delegate EBCM_ETH_CompositionPrototype.SrlDat637P <-> outer port SDVRootCompositionType/SrlDat637P
    delegate EBCM_ETH_CompositionPrototype.SrlDat638R <-> outer port SDVRootCompositionType/SrlDat638R
    delegate EBCM_ETH_CompositionPrototype.SrlDat639R <-> outer port SDVRootCompositionType/SrlDat639R
    delegate EBCM_ETH_CompositionPrototype.SrlDat673R <-> outer port SDVRootCompositionType/SrlDat673R
    delegate EBCM_ETH_CompositionPrototype.SrlDat674R <-> outer port SDVRootCompositionType/SrlDat674R
    delegate EBCM_ETH_CompositionPrototype.SrlDat675P <-> outer port SDVRootCompositionType/SrlDat675P
  system System: category=SYSTEM_EXTRACT, pnc-vector-length=6, pnc-vector-offset=2
    system mapping SystemMapping
      sec oc crypto service mapping GMCustom_Profile1: authentication=Authentication_GMCustom_Profile1, crypto-service-key=CryptoServiceKey_GMCustom_Profile1
      data-mappings:
        sender-receiver-to-signal-group-mapping={data-element=SDVRootSwCompositionPrototype.SrlDat636P.SrlDat636, signal-group=SrlDat636_SdvSystemSignalGroup, type-mapping=sender-rec-record-type-mapping=record-element-mappings=[{application-record-element=BrkSysPriBrkModToSecBrkModRtnRq, system-signal=BrkSysPriBrkModToSecBrkModRtnRq}, {application-record-element=HydrlcBrkFncStatAchvd, system-signal=HydrlcBrkFncStatAchvd}, {application-record-element=LtElecPrkBrkActrAppStat, system-signal=LtElecPrkBrkActrAppStat}, {application-record-element=MnAutoCtlrBrkOprtlModeReq, system-signal=MnAutoCtlrBrkOprtlModeReq}, {application-record-element=MstrCylPistnTrvlCalcd, system-signal=MstrCylPistnTrvlCalcd}, {application-record-element=MstrCylPistnTrvlCalcdSts, system-signal=MstrCylPistnTrvlCalcdSts}, {application-record-element=PriBrkModFncTstTypActv, system-signal=PriBrkModFncTstTypActv}, {application-record-element=RtElecPrkBrkActrAppStat, system-signal=RtElecPrkBrkActrAppStat}, {application-record-element=SrlDat636_ARC, system-signal=SrlDat636_ARC}, {application-record-element=SrlDat636_CRC, system-signal=SrlDat636_CRC}]}
        sender-receiver-to-signal-group-mapping={data-element=SDVRootSwCompositionPrototype.SrlDat637P.SrlDat637, signal-group=SrlDat637_SdvSystemSignalGroup, type-mapping=sender-rec-record-type-mapping=record-element-mappings=[{application-record-element=BrkSysPriBrkModRtnCrdntn, system-signal=BrkSysPriBrkModRtnCrdntn}, {application-record-element=SrlDat637_ARC, system-signal=SrlDat637_ARC}, {application-record-element=SrlDat637_CRC, system-signal=SrlDat637_CRC}]}
        sender-receiver-to-signal-group-mapping={data-element=SDVRootSwCompositionPrototype.SrlDat638R.SrlDat638, signal-group=SrlDat638_SdvSystemSignalGroup, type-mapping=sender-rec-record-type-mapping=record-element-mappings=[{application-record-element=BrkSysSecBrkModRtnAvalFlg1, system-signal=BrkSysSecBrkModRtnAvalFlg1}, {application-record-element=BrkSysSecBrkModRtnAvalFlg2, system-signal=BrkSysSecBrkModRtnAvalFlg2}, {application-record-element=BrkSysSecBrkModRtnAvalFlg3, system-signal=BrkSysSecBrkModRtnAvalFlg3}, {application-record-element=BrkSysSecBrkModRtnAvalFlg4, system-signal=BrkSysSecBrkModRtnAvalFlg4}, {application-record-element=BrkSysSecBrkModRtnAvalFlg5, system-signal=BrkSysSecBrkModRtnAvalFlg5}, {application-record-element=BrkSysSecBrkModRtnAvalFlg6, system-signal=BrkSysSecBrkModRtnAvalFlg6}, {application-record-element=BrkSysSecBrkModRtnAvalFlg7, system-signal=BrkSysSecBrkModRtnAvalFlg7}, {application-record-element=SecElecPrkBrkCmd, system-signal=SecElecPrkBrkCmd}, {application-record-element=SrlDat638_ARC, system-signal=SrlDat638_ARC}, {application-record-element=SrlDat638_CRC, system-signal=SrlDat638_CRC}]}
        sender-receiver-to-signal-group-mapping={data-element=SDVRootSwCompositionPrototype.SrlDat639R.SrlDat639, signal-group=SrlDat639_SdvSystemSignalGroup, type-mapping=sender-rec-record-type-mapping=record-element-mappings=[{application-record-element=BrkSysSecBrkModRtnCrdntn, system-signal=BrkSysSecBrkModRtnCrdntn}, {application-record-element=SrlDat639_ARC, system-signal=SrlDat639_ARC}, {application-record-element=SrlDat639_CRC, system-signal=SrlDat639_CRC}]}
        sender-receiver-to-signal-group-mapping={data-element=SDVRootSwCompositionPrototype.SrlDat673R.SrlDat673, signal-group=SrlDat673_SdvSystemSignalGroup, type-mapping=sender-rec-record-type-mapping=record-element-mappings=[{application-record-element=HSV1DiagActFltd, system-signal=HSV1DiagActFltd}, {application-record-element=HSV2DiagActFltd, system-signal=HSV2DiagActFltd}, {application-record-element=PmpMtrDiagActFltd, system-signal=PmpMtrDiagActFltd}, {application-record-element=RedntElecPrkBrkCmd, system-signal=RedntElecPrkBrkCmd}, {application-record-element=RedntWhlAnglrVelLF, system-signal=RedntWhlAnglrVelLF}, {application-record-element=RedntWhlAnglrVelRF, system-signal=RedntWhlAnglrVelRF}, {application-record-element=RedntWhlSpdSnsr_InvLF, system-signal=RedntWhlSpdSnsr_InvLF}, {application-record-element=RedntWhlSpdSnsr_InvRF, system-signal=RedntWhlSpdSnsr_InvRF}, {application-record-element=RmtActModeActv, system-signal=RmtActModeActv}, {application-record-element=SBMRmtActFltd, system-signal=SBMRmtActFltd}, {application-record-element=SBMSlfTstInfo, system-signal=SBMSlfTstInfo}, {application-record-element=SrlDat673_ARC, system-signal=SrlDat673_ARC}, {application-record-element=SrlDat673_CRC, system-signal=SrlDat673_CRC}, {application-record-element=USV1DiagActFltd, system-signal=USV1DiagActFltd}, {application-record-element=USV2DiagActFltd, system-signal=USV2DiagActFltd}]}
        sender-receiver-to-signal-group-mapping={data-element=SDVRootSwCompositionPrototype.SrlDat674R.SrlDat674, signal-group=SrlDat674_SdvSystemSignalGroup, type-mapping=sender-rec-record-type-mapping=record-element-mappings=[{application-record-element=RedntWhlAnglrVelLR, system-signal=RedntWhlAnglrVelLR}, {application-record-element=RedntWhlAnglrVelRR, system-signal=RedntWhlAnglrVelRR}, {application-record-element=RedntWhlSpdSnsr_InvLR, system-signal=RedntWhlSpdSnsr_InvLR}, {application-record-element=RedntWhlSpdSnsr_InvRR, system-signal=RedntWhlSpdSnsr_InvRR}, {application-record-element=SrlDat674_ARC, system-signal=SrlDat674_ARC}, {application-record-element=SrlDat674_CRC, system-signal=SrlDat674_CRC}]}
        sender-receiver-to-signal-group-mapping={data-element=SDVRootSwCompositionPrototype.SrlDat675P.SrlDat675, signal-group=SrlDat675_SdvSystemSignalGroup, type-mapping=sender-rec-record-type-mapping=record-element-mappings=[{application-record-element=EBCMSlfTstInfo, system-signal=EBCMSlfTstInfo}, {application-record-element=HSV1DiagActPctg, system-signal=HSV1DiagActPctg}, {application-record-element=HSV2DiagActPctg, system-signal=HSV2DiagActPctg}, {application-record-element=PmpMtrDiagActSpdCmd, system-signal=PmpMtrDiagActSpdCmd}, {application-record-element=SrlDat675_ARC, system-signal=SrlDat675_ARC}, {application-record-element=SrlDat675_CRC, system-signal=SrlDat675_CRC}, {application-record-element=USV1DiagActPctg, system-signal=USV1DiagActPctg}, {application-record-element=USV2DiagActPctg, system-signal=USV2DiagActPctg}]}
        sender-receiver-to-signal-mapping={data-element=SDVRootSwCompositionPrototype.hcSVC_CnsldtnEBST_evtR.hcSVC_CnsldtnEBST_evt, system-signal=hcSVC_CnsldtnEBST_evt_SystemSignal}
        sender-receiver-to-signal-mapping={data-element=SDVRootSwCompositionPrototype.hcSVC_CnsldtnSecEBST_evtR.hcSVC_CnsldtnSecEBST_evt, system-signal=hcSVC_CnsldtnSecEBST_evt_SystemSignal}
        sender-receiver-to-signal-mapping={data-element=SDVRootSwCompositionPrototype.ARPLearning_EvtR.ARPLearning_Evt, system-signal=ARPLearning_Evt_SystemSignal}
        sender-receiver-to-signal-mapping={data-element=SDVRootSwCompositionPrototype.MechatronicsT1S_Eth2_PwrMgrHeartbeatTx_EvtP.MechatronicsT1S_Eth2_PwrMgrHeartbeatTx_Evt, system-signal=MechatronicsT1S_Eth2_PwrMgrHeartbeatTx_Evt_SystemSignal}
        sender-receiver-to-signal-mapping={data-element=SDVRootSwCompositionPrototype.MechatronicsT1S_Eth2_PwrMgrWakeupTx_EvtP.MechatronicsT1S_Eth2_PwrMgrWakeupTx_Evt, system-signal=MechatronicsT1S_Eth2_PwrMgrWakeupTx_Evt_SystemSignal}
        sender-receiver-to-signal-mapping={data-element=SDVRootSwCompositionPrototype.MechatronicsT1S_Eth2_SwMgrInfoRx_EvtR.MechatronicsT1S_Eth2_SwMgrInfoRx_Evt, system-signal=MechatronicsT1S_Eth2_SwMgrInfoRx_Evt_SystemSignal}
        sender-receiver-to-signal-mapping={data-element=SDVRootSwCompositionPrototype.MechatronicsT1S_Eth2_SwMgrInfoTx_EvtP.MechatronicsT1S_Eth2_SwMgrInfoTx_Evt, system-signal=MechatronicsT1S_Eth2_SwMgrInfoTx_Evt_SystemSignal}
        sender-receiver-to-signal-mapping={data-element=SDVRootSwCompositionPrototype.MechatronicsT1S_PwrMgrHeartbeatTx_EvtP.MechatronicsT1S_PwrMgrHeartbeatTx_Evt, system-signal=MechatronicsT1S_PwrMgrHeartbeatTx_Evt_SystemSignal}
        sender-receiver-to-signal-mapping={data-element=SDVRootSwCompositionPrototype.MechatronicsT1S_PwrMgrWakeupTx_EvtP.MechatronicsT1S_PwrMgrWakeupTx_Evt, system-signal=MechatronicsT1S_PwrMgrWakeupTx_Evt_SystemSignal}
        sender-receiver-to-signal-mapping={data-element=SDVRootSwCompositionPrototype.MechatronicsT1S_SwMgrInfoTx_EvtP.MechatronicsT1S_SwMgrInfoTx_Evt, system-signal=MechatronicsT1S_SwMgrInfoTx_Evt_SystemSignal}
        sender-receiver-to-signal-mapping={data-element=SDVRootSwCompositionPrototype.MechatronicsT1S_SwMgrInfoRx_EvtR.MechatronicsT1S_SwMgrInfoRx_Evt, system-signal=MechatronicsT1S_SwMgrInfoRx_Evt_SystemSignal}
        sender-receiver-to-signal-mapping={data-element=SDVRootSwCompositionPrototype.Mechatronics_Eth2_SwMgrInfoRx_EvtR.Mechatronics_Eth2_SwMgrInfoRx_Evt, system-signal=Mechatronics_Eth2_SwMgrInfoRx_Evt_SystemSignal}
        sender-receiver-to-signal-mapping={data-element=SDVRootSwCompositionPrototype.Mechatronics_Eth2_SwMgrInfoTx_EvtP.Mechatronics_Eth2_SwMgrInfoTx_Evt, system-signal=Mechatronics_Eth2_SwMgrInfoTx_Evt_SystemSignal}
        sender-receiver-to-signal-mapping={data-element=SDVRootSwCompositionPrototype.PwrMgrMulti_PwrMgrHeartbeatRx_EvtR.PwrMgrMulti_PwrMgrHeartbeatRx_Evt, system-signal=PwrMgrMulti_PwrMgrHeartbeatRx_Evt_SystemSignal}
        sender-receiver-to-signal-mapping={data-element=SDVRootSwCompositionPrototype.PwrMgrMulti_PwrMgrWakeupRx_EvtR.PwrMgrMulti_PwrMgrWakeupRx_Evt, system-signal=PwrMgrMulti_PwrMgrWakeupRx_Evt_SystemSignal}
        sender-receiver-to-signal-mapping={data-element=SDVRootSwCompositionPrototype.hSVC_eBstActrPri_evtP.hSVC_eBstActrPri_evt, system-signal=hSVC_eBstActrPri_evt_SystemSignal}
        sender-receiver-to-signal-mapping={data-element=SDVRootSwCompositionPrototype.hSVC_eBstActrSec_evtP.hSVC_eBstActrSec_evt, system-signal=hSVC_eBstActrSec_evt_SystemSignal}
      sw-mappings:
        swc to ecu mapping EBCM_ETH_CompositionMapping: component=SDVRootSwCompositionPrototype.EBCM_ETH_CompositionPrototype, ecu-instance=EBCM_ETH
    root-software-compositions:
      root sw composition prototype SDVRootSwCompositionPrototype: software-composition=SDVRootCompositionType
package /System/DataTypes
  7 x application record data type, all with category=STRUCTURE:
    SrlDat636
      10 x application record element, all with category=VALUE:
        BrkSysPriBrkModToSecBrkModRtnRq: type=AppEnum
        HydrlcBrkFncStatAchvd: type=AppEnum
        LtElecPrkBrkActrAppStat: type=AppEnum
        MnAutoCtlrBrkOprtlModeReq: type=AppEnum
        MstrCylPistnTrvlCalcd: type=AppSint16
        MstrCylPistnTrvlCalcdSts: type=AppEnum
        PriBrkModFncTstTypActv: type=AppEnum
        RtElecPrkBrkActrAppStat: type=AppEnum
        SrlDat636_ARC: type=ApplicationTypes/AppUint8
        SrlDat636_CRC: type=ApplicationTypes/AppUint8
    SrlDat637
      application record element BrkSysPriBrkModRtnCrdntn: category=VALUE, type=AppUint64
      application record element SrlDat637_ARC: category=VALUE, type=ApplicationTypes/AppUint8
      application record element SrlDat637_CRC: category=VALUE, type=ApplicationTypes/AppUint8
    SrlDat638
      10 x application record element:
        BrkSysSecBrkModRtnAvalFlg{1..7}: category=BOOLEAN, type=AppBoolean
        SecElecPrkBrkCmd: category=VALUE, type=AppEnum
        SrlDat638_ARC: category=VALUE, type=ApplicationTypes/AppUint8
        SrlDat638_CRC: category=VALUE, type=ApplicationTypes/AppUint8
    SrlDat639
      application record element BrkSysSecBrkModRtnCrdntn: category=VALUE, type=AppUint64
      application record element SrlDat639_ARC: category=VALUE, type=ApplicationTypes/AppUint8
      application record element SrlDat639_CRC: category=VALUE, type=ApplicationTypes/AppUint8
    SrlDat673
      15 x application record element:
        HSV1DiagActFltd: category=BOOLEAN, type=AppBoolean
        HSV2DiagActFltd: category=BOOLEAN, type=AppBoolean
        PmpMtrDiagActFltd: category=BOOLEAN, type=AppBoolean
        RedntElecPrkBrkCmd: category=VALUE, type=AppEnum
        RedntWhlAnglrVelLF: category=VALUE, type=ApplicationTypes/AppUint16
        RedntWhlAnglrVelRF: category=VALUE, type=ApplicationTypes/AppUint16
        RedntWhlSpdSnsr_InvLF: category=BOOLEAN, type=AppBoolean
        RedntWhlSpdSnsr_InvRF: category=BOOLEAN, type=AppBoolean
        RmtActModeActv: category=BOOLEAN, type=AppBoolean
        SBMRmtActFltd: category=BOOLEAN, type=AppBoolean
        SBMSlfTstInfo: category=VALUE, type=AppEnum
        SrlDat673_ARC: category=VALUE, type=ApplicationTypes/AppUint8
        SrlDat673_CRC: category=VALUE, type=ApplicationTypes/AppUint8
        USV1DiagActFltd: category=BOOLEAN, type=AppBoolean
        USV2DiagActFltd: category=BOOLEAN, type=AppBoolean
    SrlDat674
      6 x application record element:
        RedntWhlAnglrVelLR: category=VALUE, type=ApplicationTypes/AppUint16
        RedntWhlAnglrVelRR: category=VALUE, type=ApplicationTypes/AppUint16
        RedntWhlSpdSnsr_InvLR: category=BOOLEAN, type=AppBoolean
        RedntWhlSpdSnsr_InvRR: category=BOOLEAN, type=AppBoolean
        SrlDat674_ARC: category=VALUE, type=ApplicationTypes/AppUint8
        SrlDat674_CRC: category=VALUE, type=ApplicationTypes/AppUint8
    SrlDat675
      8 x application record element, all with category=VALUE:
        EBCMSlfTstInfo: type=AppEnum
        HSV1DiagActPctg: type=ApplicationTypes/AppUint8
        HSV2DiagActPctg: type=ApplicationTypes/AppUint8
        PmpMtrDiagActSpdCmd: type=ApplicationTypes/AppUint16
        SrlDat675_ARC: type=ApplicationTypes/AppUint8
        SrlDat675_CRC: type=ApplicationTypes/AppUint8
        USV1DiagActPctg: type=ApplicationTypes/AppUint8
        USV2DiagActPctg: type=ApplicationTypes/AppUint8
package /System/DataTypes/ImpTypes
  4 x impl type, all with category=VALUE:
    ImpFloat32: base-type=float32
    ImpUint16: base-type=uint16
    ImpUint32: base-type=uint32
    ImpUint8: base-type=uint8
package /TYPES_Library
  26 x impl type:
    BYTE: implementation-data-type=ImpTypes/ImpUint8
    ImpUint16: category=VALUE, base-type=uint16
    ImpUint32: category=VALUE, base-type=uint32
    ImpUint8: category=VALUE, base-type=uint8
    LONGWORD: category=VALUE, base-type=uint32
    T_COUNT_BYTE: implementation-data-type=ImpTypes/ImpUint8
    T_COUNT_LONG: implementation-data-type=ImpTypes/ImpUint32
    T_COUNT_WORD: implementation-data-type=ImpTypes/ImpUint16
    T_F_Newtons: implementation-data-type=ImpFloat32
    T_I_Amps: implementation-data-type=ImpFloat32
    T_KPH_UW_07: implementation-data-type=ImpTypes/ImpUint16
    T_M_NewtonMeters: implementation-data-type=ImpFloat32
    T_Pct_Percent: implementation-data-type=ImpFloat32
    T_T_Celsius: implementation-data-type=ImpFloat32
    T_U_Volts: implementation-data-type=ImpFloat32
    T_V_Millimeters3: implementation-data-type=ImpFloat32
    T_a_MetersPerSec2: implementation-data-type=ImpFloat32
    T_l_Kilometers: implementation-data-type=ImpFloat32
    T_l_Meters: implementation-data-type=ImpFloat32
    T_l_Millimeters: implementation-data-type=ImpFloat32
    T_m_Kilograms: implementation-data-type=ImpFloat32
    T_p_bar: implementation-data-type=ImpFloat32
    T_phi_Rad: implementation-data-type=ImpFloat32
    T_v_MetersPerSec: implementation-data-type=ImpFloat32
    TbBOOLEAN: category=VALUE, base-type=uint8, compu {0=CbFALSE, 1=CbTRUE}, range raw 0..1
    WORD: category=VALUE, base-type=uint16
  19 x unit:
    T_COUNT_BYTE_Units: display-name=Counts  # Counts
    T_COUNT_LONG_Units: display-name=Counts  # Counts
    T_COUNT_WORD_Units: display-name=Counts  # Counts
    T_F_Newtons_Units: display-name=N (newtons)  # N (newtons)
    T_I_Amps_Units: display-name=A (Amperes)  # A (Amperes)
    T_KPH_UW_07_Units: display-name=kph (kilometers / hour)  # kph (kilometers / hour)
    T_M_NewtonMeters_Units: display-name=Nm (newton-meters)  # Nm (newton-meters)
    T_Pct_Percent_Units: display-name=% (percent)  # % (percent)
    T_T_Celsius_Units: display-name=\°C (degrees Celsius)  # \°C (degrees Celsius)
    T_U_Volts_Units: display-name=V (volts)  # V (volts)
    T_V_Millimeters3_Units: display-name=mm\³ (mm^3)  # mm\³ (mm^3)
    T_a_MetersPerSec2_Units: display-name=m/s\² (meters / square second)  # m/s\² (meters / square second)
    T_l_Kilometers_Units: display-name=km (kilometers)  # km (kilometers)
    T_l_Meters_Units: display-name=m (meters)  # m (meters)
    T_l_Millimeters_Units: display-name=mm (millimeters)  # mm (millimeters)
    T_m_Kilograms_Units: display-name=kg (kilograms)  # kg (kilograms)
    T_p_bar_Units: display-name=bar  # bar
    T_phi_Rad_Units: display-name=rad (radians)  # rad (radians)
    T_v_MetersPerSec_Units: display-name=m/s (meters / second)  # m/s (meters / second)
package /TYPES_Library/ApplicationDataTypes
  26 x app type, all with category=VALUE:
    AppUint16
    AppUint32
    AppUint8
    BYTE
    LONGWORD
    T_COUNT_BYTE: compu {phys=raw; unit Counts}
    T_COUNT_LONG: compu {phys=raw; unit Counts}
    T_COUNT_WORD: compu {phys=raw; unit Counts}
    T_F_Newtons: compu {phys=raw; unit N (newtons)}
    T_I_Amps: compu {phys=raw; unit A (Amperes)}
    T_KPH_UW_07: compu {phys=raw/128; unit kph (kilometers / hour)}
    T_M_NewtonMeters: compu {phys=raw; unit Nm (newton-meters)}
    T_Pct_Percent: compu {phys=raw; unit % (percent)}
    T_T_Celsius: compu {phys=raw; unit \°C (degrees Celsius)}
    T_U_Volts: compu {phys=raw; unit V (volts)}
    T_V_Millimeters3: compu {phys=raw; unit mm\³ (mm^3)}
    T_a_MetersPerSec2: compu {phys=raw; unit m/s\² (meters / square second)}
    T_l_Kilometers: compu {phys=raw; unit km (kilometers)}
    T_l_Meters: compu {phys=raw; unit m (meters)}
    T_l_Millimeters: compu {phys=raw; unit mm (millimeters)}
    T_m_Kilograms: compu {phys=raw; unit kg (kilograms)}
    T_p_bar: compu {phys=raw; unit bar}
    T_phi_Rad: compu {phys=raw; unit rad (radians)}
    T_v_MetersPerSec: compu {phys=raw; unit m/s (meters / second)}
    TbBOOLEAN
    WORD
package /Topologies/SDV
  can cluster BCAN_Cluster: baudrate=500000
    can physical channel BCAN_PhysicalChannel: comm-connectors=EBCM_ETH_BCAN_connector
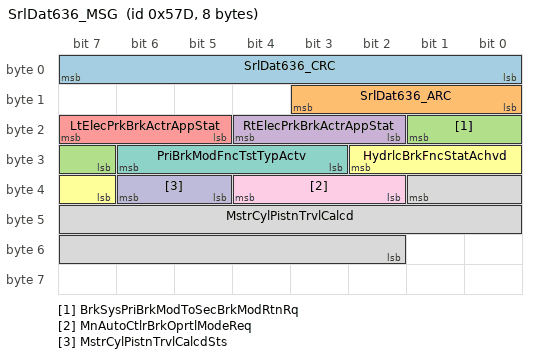
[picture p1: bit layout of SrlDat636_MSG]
      frame SrlDat636_MSG: id 0x57D, from EBCM_ETH, frame-length=8, can-addressing-mode=STANDARD, can-frame-rx-behavior=CAN-20, can-frame-tx-behavior=CAN-20
        carries pdu SrlDat636_PDU: packing-byte-order=big-endian, start-position=7
        pdu SrlDat636_PDU: length=8, transmission-mode-true-timing=cyclic-timing=time-period=0.1, unused-bit-pattern=0
          transmission-mode-conditions:
            data-filter=data-filter-type=ALWAYS, i-signal-in-i-pdu=BrkSysPriBrkModToSecBrkModRtnRq
            data-filter=data-filter-type=ALWAYS, i-signal-in-i-pdu=HydrlcBrkFncStatAchvd
            data-filter=data-filter-type=ALWAYS, i-signal-in-i-pdu=LtElecPrkBrkActrAppStat
            data-filter=data-filter-type=ALWAYS, i-signal-in-i-pdu=MnAutoCtlrBrkOprtlModeReq
            data-filter=data-filter-type=ALWAYS, i-signal-in-i-pdu=MstrCylPistnTrvlCalcd
            data-filter=data-filter-type=ALWAYS, i-signal-in-i-pdu=MstrCylPistnTrvlCalcdSts
            data-filter=data-filter-type=ALWAYS, i-signal-in-i-pdu=PriBrkModFncTstTypActv
            data-filter=data-filter-type=ALWAYS, i-signal-in-i-pdu=RtElecPrkBrkActrAppStat
            data-filter=data-filter-type=ALWAYS, i-signal-in-i-pdu=SrlDat636
            data-filter=data-filter-type=ALWAYS, i-signal-in-i-pdu=SrlDat636_ARC
            data-filter=data-filter-type=ALWAYS, i-signal-in-i-pdu=SrlDat636_CRC
          signal SrlDat636_CRC: start 0, 8 bit, little-endian, init-value=0, base-type=uint8, compu {phys=raw for raw 0..255}  # Cyclic Redundancy Check
          signal SrlDat636_ARC: start 8, 4 bit, little-endian, init-value=0, base-type=uint8, compu {phys=raw for raw 0..15}  # Alive Rolling Count
          signal BrkSysPriBrkModToSecBrkModRtnRq: start 17, 3 bit, big-endian, init-value=0, base-type=uint8, compu-method=BrkSysPriBrkModToSecBrkModRtnRq_CompuMethod  # Serial Data 636 : Brake System Primary Brake Module To Secondary Brake Module Routine Request
          signal RtElecPrkBrkActrAppStat: start 20, 3 bit, big-endian, init-value=0, base-type=uint8, compu {0=Unknown, 1=Applying, 2=Applied, 3=Releasing, 4=Released}  # Serial Data 636 : Right Electric Park Brake Actuator Applied State
          signal LtElecPrkBrkActrAppStat: start 23, 3 bit, big-endian, init-value=0, base-type=uint8, compu {0=Unknown, 1=Applying, 2=Applied, 3=Releasing, 4=Released}  # Serial Data 636 : Left Electric Park Brake Actuator Applied State
          signal HydrlcBrkFncStatAchvd: start 26, 4 bit, big-endian, init-value=0, base-type=uint8, compu-method=HydrlcBrkFncStatAchvd_CompuMethod  # Serial Data 636 : Hydraulic Brake Functional State Achieved
          signal PriBrkModFncTstTypActv: start 30, 4 bit, big-endian, init-value=0, base-type=uint8, compu-method=PriBrkModFncTstTypActv_CompuMethod  # Serial Data 636 : Primary Brake Module Functional Test Type Active
          signal MstrCylPistnTrvlCalcd: start 33, 16 bit, big-endian, init-value=0, base-type=sint16, compu {phys=raw*0.01 for raw -32768..32767; unit mm}  # Serial Data 636 : Master Cylinder Piston Travel Calculated
          signal MnAutoCtlrBrkOprtlModeReq: start 36, 3 bit, big-endian, init-value=0, base-type=uint8, compu-method=MnAutoCtlrBrkOprtlModeReq_CompuMethod  # Serial Data 636 : Main Autonomous Controller Brake Operational Mode Request
          signal MstrCylPistnTrvlCalcdSts: start 38, 2 bit, big-endian, init-value=0, base-type=uint8, compu {0=Zero_VldSnrs, 1=One_VldSnr, 2=Two_VldSnrs}  # Serial Data 636 : Master Cylinder Piston Travel Calculated Status
          mapping SrlDat636: i-signal-group=SrlDat636
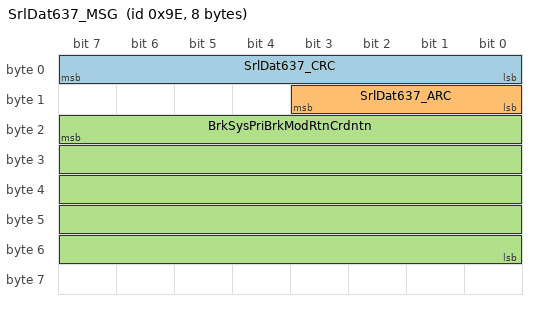
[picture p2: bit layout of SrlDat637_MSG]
      frame SrlDat637_MSG: id 0x9E, from EBCM_ETH, frame-length=8, can-addressing-mode=STANDARD, can-frame-rx-behavior=CAN-20, can-frame-tx-behavior=CAN-20
        carries pdu SrlDat637_PDU: packing-byte-order=big-endian, start-position=7
        pdu SrlDat637_PDU: length=8, transmission-mode-true-timing=cyclic-timing=time-period=0.01, unused-bit-pattern=0
          transmission-mode-conditions:
            data-filter=data-filter-type=ALWAYS, i-signal-in-i-pdu=BrkSysPriBrkModRtnCrdntn
            data-filter=data-filter-type=ALWAYS, i-signal-in-i-pdu=SrlDat637
            data-filter=data-filter-type=ALWAYS, i-signal-in-i-pdu=SrlDat637_ARC
            data-filter=data-filter-type=ALWAYS, i-signal-in-i-pdu=SrlDat637_CRC
          signal SrlDat637_CRC: start 0, 8 bit, little-endian, init-value=0, base-type=uint8, compu {phys=raw for raw 0..255}  # Cyclic Redundancy Check
          signal SrlDat637_ARC: start 8, 4 bit, little-endian, init-value=0, base-type=uint8, compu {phys=raw for raw 0..15}  # Alive Rolling Count
          signal BrkSysPriBrkModRtnCrdntn: start 23, 40 bit, big-endian, init-value=0, base-type=uint64, compu {phys=raw for raw 0..1099511627775}  # Serial Data 637 : Brake System Primary Brake Module Routine Coordination
          mapping SrlDat637: i-signal-group=SrlDat637
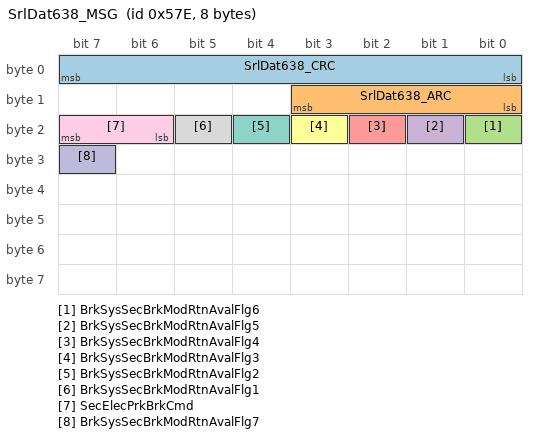
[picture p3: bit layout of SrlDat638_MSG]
      frame SrlDat638_MSG: id 0x57E, to EBCM_ETH, frame-length=8, can-addressing-mode=STANDARD, can-frame-rx-behavior=CAN-20, can-frame-tx-behavior=CAN-20
        carries pdu SrlDat638_PDU: packing-byte-order=big-endian, start-position=7
        pdu SrlDat638_PDU: length=8, transmission-mode-true-timing=cyclic-timing=time-period=0.1, unused-bit-pattern=0
          transmission-mode-conditions:
            data-filter=data-filter-type=ALWAYS, i-signal-in-i-pdu=BrkSysSecBrkModRtnAvalFlg{1..7}
            data-filter=data-filter-type=ALWAYS, i-signal-in-i-pdu=SecElecPrkBrkCmd
            data-filter=data-filter-type=ALWAYS, i-signal-in-i-pdu=SrlDat638
            data-filter=data-filter-type=ALWAYS, i-signal-in-i-pdu=SrlDat638_ARC
            data-filter=data-filter-type=ALWAYS, i-signal-in-i-pdu=SrlDat638_CRC
          signal SrlDat638_CRC: start 0, 8 bit, little-endian, init-value=0, base-type=uint8, compu {phys=raw for raw 0..255}, to EBCM_ETH(timeout 0.25 s)  # Cyclic Redundancy Check
          signal SrlDat638_ARC: start 8, 4 bit, little-endian, init-value=0, base-type=uint8, compu {phys=raw for raw 0..15}, to EBCM_ETH(timeout 0.25 s)  # Alive Rolling Count
          signal BrkSysSecBrkModRtnAvalFlg6: start 16, 1 bit, big-endian, init-value=0, base-type=uint8, compu {0=FALSE, 1=TRUE}, to EBCM_ETH(timeout 0.25 s)  # Serial Data 638 : Brake System Secondary Brake Module Routine Available Flag 6
          signal BrkSysSecBrkModRtnAvalFlg5: start 17, 1 bit, big-endian, init-value=0, base-type=uint8, compu {0=FALSE, 1=TRUE}, to EBCM_ETH(timeout 0.25 s)  # Serial Data 638 : Brake System Secondary Brake Module Routine Available Flag 5
          signal BrkSysSecBrkModRtnAvalFlg4: start 18, 1 bit, big-endian, init-value=0, base-type=uint8, compu {0=FALSE, 1=TRUE}, to EBCM_ETH(timeout 0.25 s)  # Serial Data 638 : Brake System Secondary Brake Module Routine Available Flag 4
          signal BrkSysSecBrkModRtnAvalFlg3: start 19, 1 bit, big-endian, init-value=0, base-type=uint8, compu {0=FALSE, 1=TRUE}, to EBCM_ETH(timeout 0.25 s)  # Serial Data 638 : Brake System Secondary Brake Module Routine Available Flag 3
          signal BrkSysSecBrkModRtnAvalFlg2: start 20, 1 bit, big-endian, init-value=0, base-type=uint8, compu {0=FALSE, 1=TRUE}, to EBCM_ETH(timeout 0.25 s)  # Serial Data 638 : Brake System Secondary Brake Module Routine Available Flag 2
          signal BrkSysSecBrkModRtnAvalFlg1: start 21, 1 bit, big-endian, init-value=0, base-type=uint8, compu {0=FALSE, 1=TRUE}, to EBCM_ETH(timeout 0.25 s)  # Serial Data 638 : Brake System Secondary Brake Module Routine Available Flag 1
          signal SecElecPrkBrkCmd: start 23, 2 bit, big-endian, init-value=0, base-type=uint8, compu {0=No Request (No_Request), 1=Apply, 2=Release}, to EBCM_ETH(timeout 0.25 s)  # Serial Data 638 : Secondary Electric Park Brake Command
          signal BrkSysSecBrkModRtnAvalFlg7: start 31, 1 bit, big-endian, init-value=0, base-type=uint8, compu {0=FALSE, 1=TRUE}, to EBCM_ETH(timeout 0.25 s)  # Serial Data 638 : Brake System Secondary Brake Module Routine Available Flag 7
          mapping SrlDat638: i-signal-group=SrlDat638
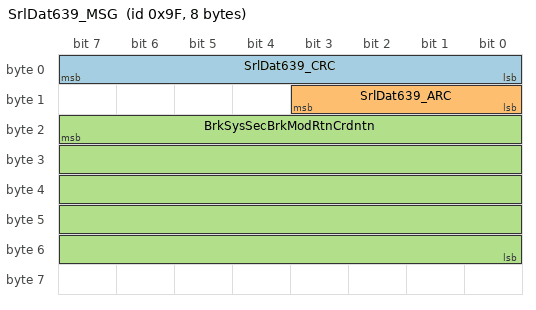
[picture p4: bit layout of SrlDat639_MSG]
      frame SrlDat639_MSG: id 0x9F, to EBCM_ETH, frame-length=8, can-addressing-mode=STANDARD, can-frame-rx-behavior=CAN-20, can-frame-tx-behavior=CAN-20
        carries pdu SrlDat639_PDU: packing-byte-order=big-endian, start-position=7
        pdu SrlDat639_PDU: length=8, transmission-mode-true-timing=cyclic-timing=time-period=0.01, unused-bit-pattern=0
          transmission-mode-conditions:
            data-filter=data-filter-type=ALWAYS, i-signal-in-i-pdu=BrkSysSecBrkModRtnCrdntn
            data-filter=data-filter-type=ALWAYS, i-signal-in-i-pdu=SrlDat639
            data-filter=data-filter-type=ALWAYS, i-signal-in-i-pdu=SrlDat639_ARC
            data-filter=data-filter-type=ALWAYS, i-signal-in-i-pdu=SrlDat639_CRC
          signal SrlDat639_CRC: start 0, 8 bit, little-endian, init-value=0, base-type=uint8, compu {phys=raw for raw 0..255}, to EBCM_ETH(timeout 0.03 s)  # Cyclic Redundancy Check
          signal SrlDat639_ARC: start 8, 4 bit, little-endian, init-value=0, base-type=uint8, compu {phys=raw for raw 0..15}, to EBCM_ETH(timeout 0.03 s)  # Alive Rolling Count
          signal BrkSysSecBrkModRtnCrdntn: start 23, 40 bit, big-endian, init-value=0, base-type=uint64, compu {phys=raw for raw 0..1099511627775}, to EBCM_ETH(timeout 0.03 s)  # Serial Data 639 : Brake System Secondary Brake Module Routine Coordination
          mapping SrlDat639: i-signal-group=SrlDat639
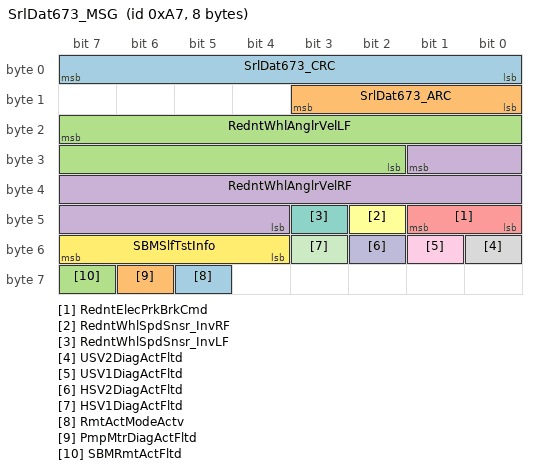
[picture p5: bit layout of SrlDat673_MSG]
      frame SrlDat673_MSG: id 0xA7, to EBCM_ETH, frame-length=8, can-addressing-mode=STANDARD, can-frame-rx-behavior=CAN-20, can-frame-tx-behavior=CAN-20
        carries pdu SrlDat673_PDU: packing-byte-order=big-endian, start-position=7
        pdu SrlDat673_PDU: length=8, transmission-mode-true-timing=cyclic-timing=time-period=0.005, unused-bit-pattern=0
          transmission-mode-conditions:
            data-filter=data-filter-type=ALWAYS, i-signal-in-i-pdu=HSV1DiagActFltd
            data-filter=data-filter-type=ALWAYS, i-signal-in-i-pdu=HSV2DiagActFltd
            data-filter=data-filter-type=ALWAYS, i-signal-in-i-pdu=PmpMtrDiagActFltd
            data-filter=data-filter-type=ALWAYS, i-signal-in-i-pdu=RedntElecPrkBrkCmd
            data-filter=data-filter-type=ALWAYS, i-signal-in-i-pdu=RedntWhlAnglrVelLF
            data-filter=data-filter-type=ALWAYS, i-signal-in-i-pdu=RedntWhlAnglrVelRF
            data-filter=data-filter-type=ALWAYS, i-signal-in-i-pdu=RedntWhlSpdSnsr_InvLF
            data-filter=data-filter-type=ALWAYS, i-signal-in-i-pdu=RedntWhlSpdSnsr_InvRF
            data-filter=data-filter-type=ALWAYS, i-signal-in-i-pdu=RmtActModeActv
            data-filter=data-filter-type=ALWAYS, i-signal-in-i-pdu=SBMRmtActFltd
            data-filter=data-filter-type=ALWAYS, i-signal-in-i-pdu=SBMSlfTstInfo
            data-filter=data-filter-type=ALWAYS, i-signal-in-i-pdu=SrlDat673
            data-filter=data-filter-type=ALWAYS, i-signal-in-i-pdu=SrlDat673_ARC
            data-filter=data-filter-type=ALWAYS, i-signal-in-i-pdu=SrlDat673_CRC
            data-filter=data-filter-type=ALWAYS, i-signal-in-i-pdu=USV1DiagActFltd
            data-filter=data-filter-type=ALWAYS, i-signal-in-i-pdu=USV2DiagActFltd
          signal SrlDat673_CRC: start 0, 8 bit, little-endian, init-value=0, base-type=uint8, compu {phys=raw for raw 0..255}, to EBCM_ETH(timeout 0.015 s)  # Cyclic Redundancy Check
          signal SrlDat673_ARC: start 8, 4 bit, little-endian, init-value=0, base-type=uint8, compu {phys=raw for raw 0..15}, to EBCM_ETH(timeout 0.015 s)  # Alive Rolling Count
          signal RedntWhlAnglrVelLF: start 23, 14 bit, big-endian, init-value=0, base-type=uint16, compu {phys=raw*0.004 for raw 0..16383; unit rps}, to EBCM_ETH(timeout 0.015 s)  # Serial Data 673 : Redundant Wheel Angular Velocity LF
          signal RedntWhlAnglrVelRF: start 25, 14 bit, big-endian, init-value=0, base-type=uint16, compu {phys=raw*0.004 for raw 0..16383; unit rps}, to EBCM_ETH(timeout 0.015 s)  # Serial Data 673 : Redundant Wheel Angular Velocity RF
          signal RedntElecPrkBrkCmd: start 41, 2 bit, big-endian, init-value=0, base-type=uint8, compu {0=No Request (No_Request), 1=Apply, 2=Release}, to EBCM_ETH(timeout 0.015 s)  # Serial Data 673 : Redundant Electric Park Brake Command
          signal RedntWhlSpdSnsr_InvRF: start 42, 1 bit, big-endian, init-value=0, base-type=uint8, compu {0=FALSE, 1=TRUE}, to EBCM_ETH(timeout 0.015 s)  # Serial Data 673 : Redundant Wheel Speed Sensor Invalid RF
          signal RedntWhlSpdSnsr_InvLF: start 43, 1 bit, big-endian, init-value=0, base-type=uint8, compu {0=FALSE, 1=TRUE}, to EBCM_ETH(timeout 0.015 s)  # Serial Data 673 : Redundant Wheel Speed Sensor Invalid LF
          signal USV2DiagActFltd: start 48, 1 bit, big-endian, init-value=0, base-type=uint8, compu {0=FALSE, 1=TRUE}, to EBCM_ETH(timeout 0.015 s)  # Serial Data 673 : USV2 Diagnostic Actuation Faulted
          signal USV1DiagActFltd: start 49, 1 bit, big-endian, init-value=0, base-type=uint8, compu {0=FALSE, 1=TRUE}, to EBCM_ETH(timeout 0.015 s)  # Serial Data 673 : USV1 Diagnostic Actuation Faulted
          signal HSV2DiagActFltd: start 50, 1 bit, big-endian, init-value=0, base-type=uint8, compu {0=FALSE, 1=TRUE}, to EBCM_ETH(timeout 0.015 s)  # Serial Data 673 : HSV2 Diagnostic Actuation Faulted
          signal HSV1DiagActFltd: start 51, 1 bit, big-endian, init-value=0, base-type=uint8, compu {0=FALSE, 1=TRUE}, to EBCM_ETH(timeout 0.015 s)  # Serial Data 673 : HSV1 Diagnostic Actuation Faulted
          signal SBMSlfTstInfo: start 55, 4 bit, big-endian, init-value=0, base-type=uint8, compu-method=SBMSlfTstInfo_CompuMethod, to EBCM_ETH(timeout 0.015 s)  # Serial Data 673 : SBM Self Test Information
          signal RmtActModeActv: start 61, 1 bit, big-endian, init-value=0, base-type=uint8, compu {0=FALSE, 1=TRUE}, to EBCM_ETH(timeout 0.015 s)  # Serial Data 673 : Remote Actuation Mode Active
          signal PmpMtrDiagActFltd: start 62, 1 bit, big-endian, init-value=0, base-type=uint8, compu {0=FALSE, 1=TRUE}, to EBCM_ETH(timeout 0.015 s)  # Serial Data 673 : Pump Motor Diagnostic Actuation Faulted
          signal SBMRmtActFltd: start 63, 1 bit, big-endian, init-value=0, base-type=uint8, compu {0=FALSE, 1=TRUE}, to EBCM_ETH(timeout 0.015 s)  # Serial Data 673 : SBM Remote Actuation Faulted
          mapping SrlDat673: i-signal-group=SrlDat673
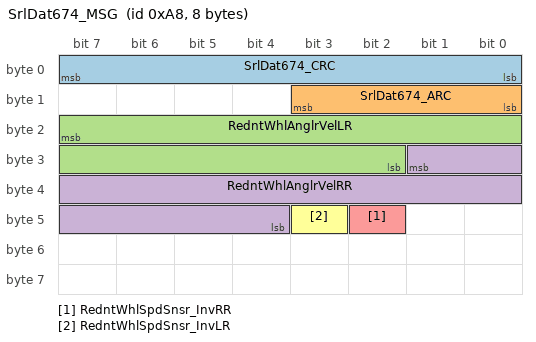
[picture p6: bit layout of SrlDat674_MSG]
      frame SrlDat674_MSG: id 0xA8, to EBCM_ETH, frame-length=8, can-addressing-mode=STANDARD, can-frame-rx-behavior=CAN-20, can-frame-tx-behavior=CAN-20
        carries pdu SrlDat674_PDU: packing-byte-order=big-endian, start-position=7
        pdu SrlDat674_PDU: length=8, transmission-mode-true-timing=cyclic-timing=time-period=0.005, unused-bit-pattern=0
          transmission-mode-conditions:
            data-filter=data-filter-type=ALWAYS, i-signal-in-i-pdu=RedntWhlAnglrVelLR
            data-filter=data-filter-type=ALWAYS, i-signal-in-i-pdu=RedntWhlAnglrVelRR
            data-filter=data-filter-type=ALWAYS, i-signal-in-i-pdu=RedntWhlSpdSnsr_InvLR
            data-filter=data-filter-type=ALWAYS, i-signal-in-i-pdu=RedntWhlSpdSnsr_InvRR
            data-filter=data-filter-type=ALWAYS, i-signal-in-i-pdu=SrlDat674
            data-filter=data-filter-type=ALWAYS, i-signal-in-i-pdu=SrlDat674_ARC
            data-filter=data-filter-type=ALWAYS, i-signal-in-i-pdu=SrlDat674_CRC
          signal SrlDat674_CRC: start 0, 8 bit, little-endian, init-value=0, base-type=uint8, compu {phys=raw for raw 0..255}, to EBCM_ETH(timeout 0.015 s)  # Cyclic Redundancy Check
          signal SrlDat674_ARC: start 8, 4 bit, little-endian, init-value=0, base-type=uint8, compu {phys=raw for raw 0..15}, to EBCM_ETH(timeout 0.015 s)  # Alive Rolling Count
          signal RedntWhlAnglrVelLR: start 23, 14 bit, big-endian, init-value=0, base-type=uint16, compu {phys=raw*0.004 for raw 0..16383; unit rps}, to EBCM_ETH(timeout 0.015 s)  # Serial Data 674 : Redundant Wheel Angular Velocity LR
          signal RedntWhlAnglrVelRR: start 25, 14 bit, big-endian, init-value=0, base-type=uint16, compu {phys=raw*0.004 for raw 0..16383; unit rps}, to EBCM_ETH(timeout 0.015 s)  # Serial Data 674 : Redundant Wheel Angular Velocity RR
          signal RedntWhlSpdSnsr_InvRR: start 42, 1 bit, big-endian, init-value=0, base-type=uint8, compu {0=FALSE, 1=TRUE}, to EBCM_ETH(timeout 0.015 s)  # Serial Data 674 : Redundant Wheel Speed Sensor Invalid RR
          signal RedntWhlSpdSnsr_InvLR: start 43, 1 bit, big-endian, init-value=0, base-type=uint8, compu {0=FALSE, 1=TRUE}, to EBCM_ETH(timeout 0.015 s)  # Serial Data 674 : Redundant Wheel Speed Sensor Invalid LR
          mapping SrlDat674: i-signal-group=SrlDat674
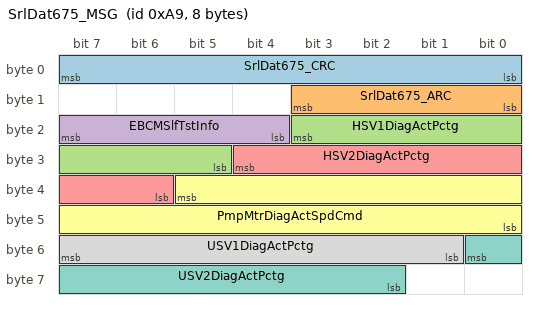
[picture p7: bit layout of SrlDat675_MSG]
      frame SrlDat675_MSG: id 0xA9, from EBCM_ETH, frame-length=8, can-addressing-mode=STANDARD, can-frame-rx-behavior=CAN-20, can-frame-tx-behavior=CAN-20
        carries pdu SrlDat675_PDU: packing-byte-order=big-endian, start-position=7
        pdu SrlDat675_PDU: length=8, transmission-mode-true-timing=cyclic-timing=time-period=0.005, unused-bit-pattern=0
          transmission-mode-conditions:
            data-filter=data-filter-type=ALWAYS, i-signal-in-i-pdu=EBCMSlfTstInfo
            data-filter=data-filter-type=ALWAYS, i-signal-in-i-pdu=HSV1DiagActPctg
            data-filter=data-filter-type=ALWAYS, i-signal-in-i-pdu=HSV2DiagActPctg
            data-filter=data-filter-type=ALWAYS, i-signal-in-i-pdu=PmpMtrDiagActSpdCmd
            data-filter=data-filter-type=ALWAYS, i-signal-in-i-pdu=SrlDat675
            data-filter=data-filter-type=ALWAYS, i-signal-in-i-pdu=SrlDat675_ARC
            data-filter=data-filter-type=ALWAYS, i-signal-in-i-pdu=SrlDat675_CRC
            data-filter=data-filter-type=ALWAYS, i-signal-in-i-pdu=USV1DiagActPctg
            data-filter=data-filter-type=ALWAYS, i-signal-in-i-pdu=USV2DiagActPctg
          signal SrlDat675_CRC: start 0, 8 bit, little-endian, init-value=0, base-type=uint8, compu {phys=raw for raw 0..255}  # Cyclic Redundancy Check
          signal SrlDat675_ARC: start 8, 4 bit, little-endian, init-value=0, base-type=uint8, compu {phys=raw for raw 0..15}  # Alive Rolling Count
          signal HSV1DiagActPctg: start 19, 7 bit, big-endian, init-value=0, base-type=uint8, compu {phys=raw for raw 0..127; unit %}  # Serial Data 675 : HSV1 Diagnostic Actuation Percentage
          signal EBCMSlfTstInfo: start 23, 4 bit, big-endian, init-value=0, base-type=uint8, compu-method=EBCMSlfTstInfo_CompuMethod  # Serial Data 675 : EBCM Self Test Information
          signal HSV2DiagActPctg: start 28, 7 bit, big-endian, init-value=0, base-type=uint8, compu {phys=raw for raw 0..127; unit %}  # Serial Data 675 : HSV2 Diagnostic Actuation Percentage
          signal PmpMtrDiagActSpdCmd: start 37, 14 bit, big-endian, init-value=0, base-type=uint16, compu {phys=raw for raw 0..16383; unit rpm}  # Serial Data 675 : Pump Motor Diagnostic Actuation Speed Command
          signal USV2DiagActPctg: start 48, 7 bit, big-endian, init-value=0, base-type=uint8, compu {phys=raw for raw 0..127; unit %}  # Serial Data 675 : USV2 Diagnostic Actuation Percentage
          signal USV1DiagActPctg: start 55, 7 bit, big-endian, init-value=0, base-type=uint8, compu {phys=raw for raw 0..127; unit %}  # Serial Data 675 : USV1 Diagnostic Actuation Percentage
          mapping SrlDat675: i-signal-group=SrlDat675
      frame USDT_Req_From_TT2_To_AllNodes_AllNetworks_On_BCAN_Cluster: id 0x10DBFEF2, to EBCM_ETH, frame-length=8, can-addressing-mode=EXTENDED, can-frame-rx-behavior=CAN-20, can-frame-tx-behavior=CAN-20
        carries pdu USDT_Req_From_TT2_To_AllNodes_AllNetworks_On_BCAN_Cluster_Tp: packing-byte-order=big-endian, start-position=7
        n pdu USDT_Req_From_TT2_To_AllNodes_AllNetworks_On_BCAN_Cluster_Tp: length=8
      frame USDT_Req_From_TT2_To_EBCM_ETH_BCAN_On_BCAN_Cluster: id 0x14DA2CF2, to EBCM_ETH, frame-length=8, can-addressing-mode=EXTENDED, can-frame-rx-behavior=CAN-20, can-frame-tx-behavior=CAN-20
        carries pdu USDT_Req_From_TT2_To_EBCM_ETH_BCAN_On_BCAN_Cluster_Tp: packing-byte-order=big-endian, start-position=7
        n pdu USDT_Req_From_TT2_To_EBCM_ETH_BCAN_On_BCAN_Cluster_Tp: length=8
      frame USDT_Rsp_From_EBCM_ETH_BCAN_To_TT2_On_BCAN_Cluster: id 0x14DAF22C, from EBCM_ETH, frame-length=8, can-addressing-mode=EXTENDED, can-frame-rx-behavior=CAN-20, can-frame-tx-behavior=CAN-20
        carries pdu USDT_Rsp_From_EBCM_ETH_BCAN_To_TT2_On_BCAN_Cluster_Tp: packing-byte-order=big-endian, start-position=7
        n pdu USDT_Rsp_From_EBCM_ETH_BCAN_To_TT2_On_BCAN_Cluster_Tp: length=8
      frame UUDT_Rsp_From_EBCM_ETH_BCAN_To_TT2_On_BCAN_Cluster: id 0x14DCF22C, from EBCM_ETH, frame-length=8, can-addressing-mode=EXTENDED, can-frame-rx-behavior=CAN-20, can-frame-tx-behavior=CAN-20
        carries pdu UUDT_Rsp_From_EBCM_ETH_BCAN_To_TT2_On_BCAN_Cluster: packing-byte-order=big-endian, start-position=7
        dcm i pdu UUDT_Rsp_From_EBCM_ETH_BCAN_To_TT2_On_BCAN_Cluster: length=8, diag-pdu-type=DIAG-RESPONSE
      pdu triggering USDT_Req_From_TT2_To_AllNodes_AllNetworks_On_BCAN_Cluster_PDU_Triggering: pdu=USDT_Req_From_TT2_To_AllNodes_AllNetworks_On_BCAN_Cluster, to EBCM_ETH
      pdu triggering USDT_Req_From_TT2_To_EBCM_ETH_BCAN_On_BCAN_Cluster_PDU_Triggering: pdu=USDT_Req_From_TT2_To_EBCM_ETH_BCAN_On_BCAN_Cluster, to EBCM_ETH
      pdu triggering USDT_Rsp_From_EBCM_ETH_BCAN_To_TT2_On_BCAN_Cluster_PDU_Triggering: pdu=USDT_Rsp_From_EBCM_ETH_BCAN_To_TT2_On_BCAN_Cluster, from EBCM_ETH
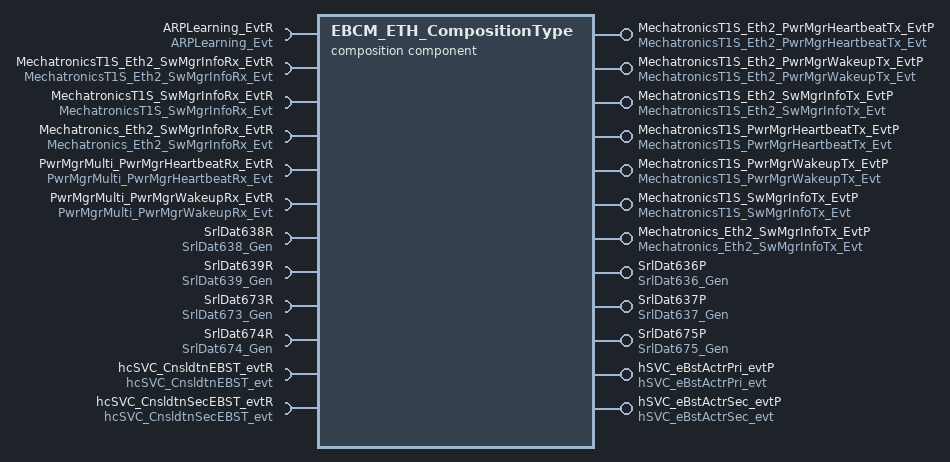
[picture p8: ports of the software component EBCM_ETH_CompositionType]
  composition sw component type EBCM_ETH_CompositionType: data-type-mapping=EBCM_ETH_DataTypeMappingSet
    12 x provide port:
      MechatronicsT1S_Eth2_PwrMgrHeartbeatTx_EvtP: provided-interface=MechatronicsT1S_Eth2_PwrMgrHeartbeatTx_Evt
      MechatronicsT1S_Eth2_PwrMgrWakeupTx_EvtP: provided-interface=MechatronicsT1S_Eth2_PwrMgrWakeupTx_Evt
      MechatronicsT1S_Eth2_SwMgrInfoTx_EvtP: provided-interface=MechatronicsT1S_Eth2_SwMgrInfoTx_Evt
      MechatronicsT1S_PwrMgrHeartbeatTx_EvtP: provided-interface=MechatronicsT1S_PwrMgrHeartbeatTx_Evt
      MechatronicsT1S_PwrMgrWakeupTx_EvtP: provided-interface=MechatronicsT1S_PwrMgrWakeupTx_Evt
      MechatronicsT1S_SwMgrInfoTx_EvtP: provided-interface=MechatronicsT1S_SwMgrInfoTx_Evt
      Mechatronics_Eth2_SwMgrInfoTx_EvtP: provided-interface=Mechatronics_Eth2_SwMgrInfoTx_Evt
      SrlDat636P: provided-interface=SrlDat636_Gen
      SrlDat637P: provided-interface=SrlDat637_Gen
      SrlDat675P: provided-interface=SrlDat675_Gen
      hSVC_eBstActrPri_evtP: provided-interface=hSVC_eBstActrPri_evt
      hSVC_eBstActrSec_evtP: provided-interface=hSVC_eBstActrSec_evt
    12 x require port:
      ARPLearning_EvtR: queued-receiver-com-spec{data-element=ARPLearning_Evt, queue-length=1}, required-interface=ARPLearning_Evt
      MechatronicsT1S_Eth2_SwMgrInfoRx_EvtR: queued-receiver-com-spec{data-element=MechatronicsT1S_Eth2_SwMgrInfoRx_Evt, queue-length=2}, required-interface=MechatronicsT1S_Eth2_SwMgrInfoRx_Evt
      MechatronicsT1S_SwMgrInfoRx_EvtR: queued-receiver-com-spec{data-element=MechatronicsT1S_SwMgrInfoRx_Evt, queue-length=2}, required-interface=MechatronicsT1S_SwMgrInfoRx_Evt
      Mechatronics_Eth2_SwMgrInfoRx_EvtR: queued-receiver-com-spec{data-element=Mechatronics_Eth2_SwMgrInfoRx_Evt, queue-length=2}, required-interface=Mechatronics_Eth2_SwMgrInfoRx_Evt
      PwrMgrMulti_PwrMgrHeartbeatRx_EvtR: queued-receiver-com-spec{data-element=PwrMgrMulti_PwrMgrHeartbeatRx_Evt, queue-length=2}, required-interface=PwrMgrMulti_PwrMgrHeartbeatRx_Evt
      PwrMgrMulti_PwrMgrWakeupRx_EvtR: queued-receiver-com-spec{data-element=PwrMgrMulti_PwrMgrWakeupRx_Evt, queue-length=2}, required-interface=PwrMgrMulti_PwrMgrWakeupRx_Evt
      SrlDat638R: required-interface=SrlDat638_Gen
      SrlDat639R: required-interface=SrlDat639_Gen
      SrlDat673R: required-interface=SrlDat673_Gen
      SrlDat674R: required-interface=SrlDat674_Gen
      hcSVC_CnsldtnEBST_evtR: required-interface=hcSVC_CnsldtnEBST_evt
      hcSVC_CnsldtnSecEBST_evtR: required-interface=hcSVC_CnsldtnSecEBST_evt
  ecu instance EBCM_ETH:
    associated-com-i-pdu-group=[BCAN_Package_EBCM_ETH_BCAN_IN, BCAN_Package_EBCM_ETH_BCAN_OUT, MechatronicsT1S_Eth2_SwMgrInfoRx_FFFD_EBCM_ETH_IN, hcSVC_CnsldtnSecEBST_0D8B_EBCM_ETH_IN, MechatronicsT1S_Eth2_PwrMgrHeartbeatTx_FFFE_EBCM_ETH_OUT, MechatronicsT1S_Eth2_PwrMgrWakeupTx_FFFE_EBCM_ETH_OUT, MechatronicsT1S_Eth2_SwMgrInfoTx_FFFD_EBCM_ETH_OUT, hSVC_eBstActrSec_0C5C_EBCM_ETH_OUT, PwrMgrMulti_PwrMgrHeartbeatRx_FFFE_EBCM_ETH_IN, PwrMgrMulti_PwrMgrWakeupRx_FFFE_EBCM_ETH_IN, MechatronicsT1S_SwMgrInfoRx_FFFD_EBCM_ETH_IN, hcSVC_CnsldtnEBST_0CD6_EBCM_ETH_IN, MechatronicsT1S_PwrMgrWakeupTx_FFFE_EBCM_ETH_OUT, MechatronicsT1S_SwMgrInfoTx_FFFD_EBCM_ETH_OUT, MechatronicsT1S_PwrMgrHeartbeatTx_FFFE_EBCM_ETH_OUT, hSVC_eBstActrPri_0C5B_EBCM_ETH_OUT, ARPLearning_FFFC_EBCM_ETH_IN, Mechatronics_Eth2_SwMgrInfoRx_FFFD_EBCM_ETH_IN, Mechatronics_Eth2_SwMgrInfoTx_FFFD_EBCM_ETH_OUT]
    associated-pdur-i-pdu-group=[Ethernet_1_itsEBCM_ETH_Ethernet_1_connector2_v23_PdurIPduGroup_SD, Ethernet_1_itsEBCM_ETH_Ethernet_1_connector1_v22_PdurIPduGroup_SD]
    diagnostic-address=44
    sleep-mode-supported=false
    tcp-ip-props=EthTcpIpProps_0
    wake-up-over-bus-supported=true
    can communication controller EBCM_ETH_BCAN_controller
    ethernet communication controller EBCM_ETH_Ethernet_1_1_controller: category=WIRED, mac-layer-type=X-MII, mac-unicast-address=02:00:00:06:21:00
      coupling port EBCM_ETH_Ethernet_1_1_CouplingPort: connection-negotiation-behavior=AUTO, mac-layer-type=X-MII, physical-layer-type=10BASE-T1S, plca-props={plca-local-node-id=1, plca-max-burst-count=0, plca-max-burst-timer=0}, vlan-memberships=[Eth_v52, Eth_v22, Eth_TimeSyncUntagged, Eth_v111, Eth_v21]
    ethernet communication controller EBCM_ETH_Ethernet_1_2_controller: category=WIRED, mac-layer-type=X-MII, mac-unicast-address=02:00:00:06:21:01
      coupling port EBCM_ETH_Ethernet_1_2_CouplingPort: connection-negotiation-behavior=AUTO, mac-layer-type=X-MII, physical-layer-type=10BASE-T1S, plca-props={plca-local-node-id=1, plca-max-burst-count=0, plca-max-burst-timer=0}, vlan-memberships=[Eth_v23, Eth_v111, Eth_v52]
    can communication connector EBCM_ETH_BCAN_connector: comm-controller=EBCM_ETH_BCAN_controller, pnc-wakeup-can-id=256, pnc-wakeup-can-id-extended=false, pnc-wakeup-can-id-mask=255, pnc-wakeup-dlc=8
    ethernet communication connector EBCM_ETH_Eth_v52_2: comm-controller=EBCM_ETH_Ethernet_1_2_controller, create-ecu-wakeup-source=true, maximum-transmission-unit=234, network-endpoint=EBCM_ETH_Eth2_Eth_v52_NEP
    ethernet communication connector EBCM_ETH_Eth_TimeSyncUntagged_1: comm-controller=EBCM_ETH_Ethernet_1_1_controller, create-ecu-wakeup-source=true, dynamic-pnc-to-channel-mapping-enabled=false
    ethernet communication connector EBCM_ETH_Eth_v111_1: comm-controller=EBCM_ETH_Ethernet_1_1_controller, create-ecu-wakeup-source=true, maximum-transmission-unit=1500, network-endpoint=EBCM_ETH_Eth1_Eth_v111_SPM_Multicast_NEP
    ethernet communication connector EBCM_ETH_Eth_v111_2: comm-controller=EBCM_ETH_Ethernet_1_2_controller, create-ecu-wakeup-source=true, maximum-transmission-unit=1500, network-endpoint=EBCM_ETH_Eth2_Eth_v111_SPM_Multicast_NEP
    ethernet communication connector EBCM_ETH_Eth_v21_1: comm-controller=EBCM_ETH_Ethernet_1_1_controller, create-ecu-wakeup-source=true, maximum-transmission-unit=1500, network-endpoint=EBCM_ETH_Eth1_Eth_v21_NEP
    ethernet communication connector EBCM_ETH_Eth_v22_1: comm-controller=EBCM_ETH_Ethernet_1_1_controller, create-ecu-wakeup-source=true, dynamic-pnc-to-channel-mapping-enabled=false, maximum-transmission-unit=1500, network-endpoint=[EBCM_ETH_Eth1_Eth_v22_NEP, EBCM_ETH_Eth1_Eth_v22_SPM_Multicast_NEP, EBCM_ETH_Eth1_Eth_v22_SDMulticast_NEP]
    ethernet communication connector EBCM_ETH_Eth_v23_2: comm-controller=EBCM_ETH_Ethernet_1_2_controller, create-ecu-wakeup-source=true, dynamic-pnc-to-channel-mapping-enabled=false, eth-ip-props=EthIpProps_0, maximum-transmission-unit=1500, network-endpoint=[EBCM_ETH_Eth2_Eth_v23_NEP, EBCM_ETH_Eth2_Eth_v23_SPM_Multicast_NEP, EBCM_ETH_Eth2_Eth_v23_SDMulticast_NEP]
    ethernet communication connector EBCM_ETH_Eth_v52_1: comm-controller=EBCM_ETH_Ethernet_1_1_controller, create-ecu-wakeup-source=true, maximum-transmission-unit=234, network-endpoint=[EBCM_ETH_Eth1_Eth_v52_NEP, EBCM_ETH_Eth1_Eth_v52_ARPMulticast_NEP]
  eth ip props EthIpProps_0: ipv-4-props=fragmentation-props={tcp-ip-ip-fragmentation-rx-enabled=false, tcp-ip-ip-num-fragments=255, tcp-ip-ip-num-reass-dgrams=1, tcp-ip-ip-reass-timeout=5.0}
  eth tcp ip props EthTcpIpProps_0: tcp-props={tcp-congestion-avoidance-enabled=false, tcp-delayed-ack-timeout=0.04, tcp-fast-recovery-enabled=false, tcp-fast-retransmit-enabled=true, tcp-fin-wait-2-timeout=0.5, tcp-keep-alive-enabled=true, tcp-keep-alive-interval=1.0, tcp-keep-alive-probes-max=3, tcp-keep-alive-time=5.0, tcp-max-rtx=3, tcp-msl=0.25, tcp-nagle-enabled=false, tcp-receive-window-max=65535, tcp-retransmission-timeout=0.05, tcp-slow-start-enabled=false, tcp-syn-max-rtx=4, tcp-syn-received-timeout=0.1, tcp-ttl=64}, udp-props=udp-ttl=64
  ethernet cluster Eth1Cluster
    11 x ethernet physical channel:
      Eth_TimeSyncUntagged: comm-connectors=EBCM_ETH_Eth_TimeSyncUntagged_1
        vlan TimeSyncUntagged
      Eth_v111: comm-connectors=[EBCM_ETH_Eth_v111_1, EBCM_ETH_Eth_v111_2]
        pdu triggering PDU_SYS_PMMulticastRxPwrMgrMulti_Heartbeat: pdu=PDU_SYS_PMMulticastRxPwrMgrMulti_Heartbeat, to EBCM_ETH
        pdu triggering PDU_SYS_PMMulticastRxPwrMgrMulti_Wakeup: pdu=PDU_SYS_PMMulticastRxPwrMgrMulti_Wakeup, to EBCM_ETH
        pdu triggering SPDU_SYS_PMMulticastRxPwrMgrMulti_Heartbeat: pdu=SPDU_SYS_PMMulticastRxPwrMgrMulti_Heartbeat, to EBCM_ETH
        4 x network endpoint:
          EBCM_ETH_Eth2_Eth_v111_SPM_Multicast_NEP
            network-endpoint-addresses:
              ipv-4-configuration={ip-address-keep-behavior=FORGET, ipv-4-address=239.195.255.254, ipv-4-address-source=FIXED, network-mask=255.255.255.0, ttl=12}
              mac-multicast-configuration=EBCM_ETH_Eth2_Eth_v111_SPM_MacMulticastGroup
          EBCM_ETH_Eth2_Eth_v111_ANY_NEP: network-endpoint-addresses=ipv-4-configuration={ip-address-keep-behavior=FORGET, ipv-4-address=ANY, ipv-4-address-source=FIXED, network-mask=0.0.0.0, ttl=12}
          EBCM_ETH_Eth1_Eth_v111_SPM_Multicast_NEP
            network-endpoint-addresses:
              ipv-4-configuration={ip-address-keep-behavior=FORGET, ipv-4-address=239.195.255.254, ipv-4-address-source=FIXED, network-mask=255.255.255.0, ttl=12}
              mac-multicast-configuration=EBCM_ETH_Eth1_Eth_v111_SPM_MacMulticastGroup
          EBCM_ETH_Eth1_Eth_v111_ANY_NEP: network-endpoint-addresses=ipv-4-configuration={ip-address-keep-behavior=FORGET, ipv-4-address=ANY, ipv-4-address-source=FIXED, network-mask=0.0.0.0, ttl=12}
        so-ad-config:
          4 x socket address, all with allowed-tcp-options=TcpOptionFilterList, udp-checksum-handling=UDP-CHECKSUM-ENABLED:
            EBCM_ETH_Eth2_Eth_v111_SPM_RxMulticast_SA: multicast-connector=EBCM_ETH_Eth_v111_2
              application endpoint EBCM_ETH_Eth2_Eth_v111_SPM_RxMulticast_AEP: max-number-of-connections=255, network-endpoint=EBCM_ETH_Eth2_Eth_v111_SPM_Multicast_NEP, priority=1, tp-configuration=udp-tp=udp-tp-port=port-number=30480
              static socket connection EBCM_ETH_Eth2_Eth_v111_SPM_RxMulticast_SocketConn: remote-addresss=EBCM_ETH_Eth2_Eth_v111_SPM_Dynamic_SA
                i-pdu-identifiers:
                  EBCM_ETH_Eth2_Eth_v111_PDU_SYS_PMMulticastRxPwrMgrMulti_Heartbeat_Identifier
                  EBCM_ETH_Eth2_Eth_v111_PDU_SYS_PMMulticastRxPwrMgrMulti_Wakeup_Identifier
            EBCM_ETH_Eth2_Eth_v111_SPM_Dynamic_SA
              application endpoint EBCM_ETH_Eth2_Eth_v111_SPM_Dynamic_AEP: max-number-of-connections=255, network-endpoint=EBCM_ETH_Eth2_Eth_v111_ANY_NEP, priority=1, tp-configuration=udp-tp=udp-tp-port={dynamically-assigned=false, port-number=30480}
            EBCM_ETH_Eth1_Eth_v111_SPM_RxMulticast_SA: multicast-connector=EBCM_ETH_Eth_v111_1
              application endpoint EBCM_ETH_Eth1_Eth_v111_SPM_RxMulticast_AEP: max-number-of-connections=255, network-endpoint=EBCM_ETH_Eth1_Eth_v111_SPM_Multicast_NEP, priority=1, tp-configuration=udp-tp=udp-tp-port=port-number=30480
              static socket connection EBCM_ETH_Eth1_Eth_v111_SPM_RxMulticast_SocketConn: remote-addresss=EBCM_ETH_Eth1_Eth_v111_SPM_Dynamic_SA
                i-pdu-identifiers:
                  EBCM_ETH_Eth1_Eth_v111_PDU_SYS_PMMulticastRxPwrMgrMulti_Heartbeat_Identifier
                  EBCM_ETH_Eth1_Eth_v111_PDU_SYS_PMMulticastRxPwrMgrMulti_Wakeup_Identifier
            EBCM_ETH_Eth1_Eth_v111_SPM_Dynamic_SA
              application endpoint EBCM_ETH_Eth1_Eth_v111_SPM_Dynamic_AEP: max-number-of-connections=255, network-endpoint=EBCM_ETH_Eth1_Eth_v111_ANY_NEP, priority=1, tp-configuration=udp-tp=udp-tp-port={dynamically-assigned=false, port-number=30480}
        vlan v111: vlan-identifier=111  # PwrMgrMulti
      Eth_v20
        vlan v20: vlan-identifier=20  # Mechatronics
      Eth_v21: comm-connectors=EBCM_ETH_Eth_v21_1
        pdu triggering PDU_SYS_SMUnicastRxMechatronics_Eth2_Info: pdu=PDU_SYS_SMUnicastRxMechatronics_Eth2_Info, to EBCM_ETH
        pdu triggering PDU_SYS_SMUnicastTxMechatronics_Eth2_Info: pdu=PDU_SYS_SMUnicastTxMechatronics_Eth2_Info, from EBCM_ETH
        pdu triggering SPDU_SYS_SMUnicastRxMechatronics_Eth2_Info: pdu=SPDU_SYS_SMUnicastRxMechatronics_Eth2_Info, to EBCM_ETH
        pdu triggering SPDU_SYS_SMUnicastTxMechatronics_Eth2_Info: pdu=SPDU_SYS_SMUnicastTxMechatronics_Eth2_Info, from EBCM_ETH
        network endpoint EBCM_ETH_Eth1_Eth_v21_NEP: network-endpoint-addresses=ipv-4-configuration={ip-address-keep-behavior=STORE-PERSISTENTLY, ipv-4-address=10.21.6.33, ipv-4-address-source=FIXED, network-mask=255.255.0.0, ttl=30}
        network endpoint EBCM_ETH_Eth1_Eth_v21_ANY_NEP: network-endpoint-addresses=ipv-4-configuration={ip-address-keep-behavior=FORGET, ipv-4-address=ANY, ipv-4-address-source=FIXED, network-mask=0.0.0.0, ttl=12}
        so-ad-config:
          socket address EBCM_ETH_Eth1_Eth_v21_PDU_SYS_SMUnicastMechatronics_Eth2_Info_SA: allowed-tcp-options=TcpOptionFilterList, connector=EBCM_ETH_Eth_v21_1, udp-checksum-handling=UDP-CHECKSUM-ENABLED
            application endpoint EBCM_ETH_Eth1_Eth_v21_PDU_SYS_SMUnicastMechatronics_Eth2_Info_AEP: max-number-of-connections=6, network-endpoint=EBCM_ETH_Eth1_Eth_v21_NEP, priority=0, tp-configuration=udp-tp=udp-tp-port=port-number=30480
            static socket connection PDU_SYS_SMUnicastMechatronics_Eth2_Info_Mechatronics_Eth2_EBCM_ETH_SocketConn: remote-addresss=EBCM_ETH_Eth1_Eth_v21_SPM_Dynamic_SA
              i-pdu-identifiers:
                EBCM_ETH_Eth1_Eth_v21_PDU_SYS_SMUnicastRxMechatronics_Eth2_Info_Identifier
                EBCM_ETH_Eth1_Eth_v21_PDU_SYS_SMUnicastTxMechatronics_Eth2_Info_Identifier
          socket address EBCM_ETH_Eth1_Eth_v21_SPM_Dynamic_SA: allowed-tcp-options=TcpOptionFilterList, udp-checksum-handling=UDP-CHECKSUM-ENABLED
            application endpoint EBCM_ETH_Eth1_Eth_v21_SPM_Dynamic_AEP: max-number-of-connections=6, network-endpoint=EBCM_ETH_Eth1_Eth_v21_ANY_NEP, priority=1, tp-configuration=udp-tp=udp-tp-port={dynamically-assigned=false, port-number=30480}
        vlan v21: vlan-identifier=21  # Mechatronics_Eth2
      Eth_v22: comm-connectors=EBCM_ETH_Eth_v22_1
        pdu triggering DummyTriggering_DO_NOT_ENABLE_Port_50000: pdu=DummyPDU_DO_NOT_ENABLE_Eth_v22_50000, to EBCM_ETH
        pdu triggering EBCM_ETH_Eth1_Eth_v22_SDMulticastRx: pdu=GPDU_EBCM_ETH_Eth1_Eth_v22_SDMulticastRx, to EBCM_ETH
        pdu triggering EBCM_ETH_Eth1_Eth_v22_SDUnicastRx: pdu=GPDU_EBCM_ETH_Eth1_Eth_v22_SDUnicastRx, to EBCM_ETH
        pdu triggering EBCM_ETH_Eth1_Eth_v22_SDUnicastTx: pdu=GPDU_EBCM_ETH_Eth1_Eth_v22_SDUnicastTx, from EBCM_ETH
        pdu triggering PDU_HC_0CD68001_Rx: pdu=PDU_HC_0CD68001, to EBCM_ETH
        pdu triggering PDU_H_0C5B8001_Tx: pdu=PDU_H_0C5B8001, from EBCM_ETH
        pdu triggering PDU_SYS_PMMulticastTxMechatronicsT1S_Heartbeat: pdu=PDU_SYS_PMMulticastTxMechatronicsT1S_Heartbeat, from EBCM_ETH
        pdu triggering PDU_SYS_PMUnicastTxMechatronicsT1S_Wakeup: pdu=PDU_SYS_PMUnicastTxMechatronicsT1S_Wakeup, from EBCM_ETH
        pdu triggering PDU_SYS_SMUnicastRxMechatronicsT1S_Info: pdu=PDU_SYS_SMUnicastRxMechatronicsT1S_Info, to EBCM_ETH
        pdu triggering PDU_SYS_SMUnicastTxMechatronicsT1S_Info: pdu=PDU_SYS_SMUnicastTxMechatronicsT1S_Info, from EBCM_ETH
        pdu triggering SPDU_HC_0CD68001_Rx: pdu=SPDU_HC_0CD68001, to EBCM_ETH
        pdu triggering SPDU_H_0C5B8001_Tx: pdu=SPDU_H_0C5B8001, from EBCM_ETH
        pdu triggering SPDU_SYS_PMMulticastTxMechatronicsT1S_Heartbeat: pdu=SPDU_SYS_PMMulticastTxMechatronicsT1S_Heartbeat, from EBCM_ETH
        pdu triggering SPDU_SYS_SMUnicastRxMechatronicsT1S_Info: pdu=SPDU_SYS_SMUnicastRxMechatronicsT1S_Info, to EBCM_ETH
        pdu triggering SPDU_SYS_SMUnicastTxMechatronicsT1S_Info: pdu=SPDU_SYS_SMUnicastTxMechatronicsT1S_Info, from EBCM_ETH
        pdu triggering Secured_EBCM_ETH_Eth1_Eth_v22_SDMulticastRx: pdu=SPDU_EBCM_ETH_Eth1_Eth_v22_SDMulticastRx, to EBCM_ETH
        pdu triggering Secured_EBCM_ETH_Eth1_Eth_v22_SDUnicastRx: pdu=SPDU_EBCM_ETH_Eth1_Eth_v22_SDUnicastRx, to EBCM_ETH
        pdu triggering Secured_EBCM_ETH_Eth1_Eth_v22_SDUnicastTx: pdu=SPDU_EBCM_ETH_Eth1_Eth_v22_SDUnicastTx, from EBCM_ETH
        5 x network endpoint:
          EBCM_ETH_Eth1_Eth_v22_ANY_NEP: network-endpoint-addresses=ipv-4-configuration={ip-address-keep-behavior=FORGET, ipv-4-address=ANY, ipv-4-address-source=FIXED, network-mask=0.0.0.0, ttl=12}
          EBCM_ETH_Eth1_Eth_v22_NEP: network-endpoint-addresses=ipv-4-configuration={ip-address-keep-behavior=STORE-PERSISTENTLY, ipv-4-address=10.22.6.33, ipv-4-address-source=FIXED, network-mask=255.255.0.0, ttl=30}
          VMCIC_Eth_v22_NEP: network-endpoint-addresses=ipv-4-configuration={ip-address-keep-behavior=STORE-PERSISTENTLY, ipv-4-address=10.22.1.129, ipv-4-address-source=FIXED, network-mask=255.255.0.0, ttl=30}
          EBCM_ETH_Eth1_Eth_v22_SPM_Multicast_NEP
            network-endpoint-addresses:
              ipv-4-configuration={ip-address-keep-behavior=FORGET, ipv-4-address=239.195.255.254, ipv-4-address-source=FIXED, network-mask=255.255.255.0, ttl=12}
              mac-multicast-configuration=EBCM_ETH_Eth1_Eth_v22_SPM_MacMulticastGroup
          EBCM_ETH_Eth1_Eth_v22_SDMulticast_NEP
            network-endpoint-addresses:
              ipv-4-configuration={ip-address-keep-behavior=FORGET, ipv-4-address=239.195.255.255, ipv-4-address-source=FIXED, ttl=12}
              mac-multicast-configuration=EBCM_ETH_Eth1_Eth_v22_SD_MacMulticastGroup
        so-ad-config:
          10 x socket address, all with allowed-tcp-options=TcpOptionFilterList, udp-checksum-handling=UDP-CHECKSUM-ENABLED:
            EBCM_ETH_Eth1_Eth_v22_Dynamic_SA
              application endpoint EBCM_ETH_Eth1_Eth_v22_Dynamic_AEP: max-number-of-connections=14, network-endpoint=EBCM_ETH_Eth1_Eth_v22_ANY_NEP, priority=1, tp-configuration=udp-tp=udp-tp-port={dynamically-assigned=true, port-number=0}
            EBCM_ETH_Eth1_Eth_v22_SDUnicast_SA: connector=EBCM_ETH_Eth_v22_1
              application endpoint EBCM_ETH_Eth1_Eth_v22_SDUnicast_AEP: max-number-of-connections=1, network-endpoint=EBCM_ETH_Eth1_Eth_v22_NEP, priority=1, tp-configuration=udp-tp=udp-tp-port=port-number=30490
              static socket connection EBCM_ETH_Eth1_Eth_v22_SDUnicast_SocketConn: i-pdu-identifiers=[EBCM_ETH_Eth1_Eth_v22_SDUnicastRx_Identifier, EBCM_ETH_Eth1_Eth_v22_SDUnicastTx_Identifier], remote-addresss=EBCM_ETH_Eth1_Eth_v22_Dynamic_SA
            EBCM_ETH_Eth1_Eth_v22_PDU_SYS_SMUnicastMechatronicsT1S_Info_SA: connector=EBCM_ETH_Eth_v22_1
              application endpoint EBCM_ETH_Eth1_Eth_v22_PDU_SYS_SMUnicastMechatronicsT1S_Info_AEP: max-number-of-connections=6, network-endpoint=EBCM_ETH_Eth1_Eth_v22_NEP, priority=0, tp-configuration=udp-tp=udp-tp-port=port-number=30480
              static socket connection PDU_SYS_SMUnicastMechatronicsT1S_Info_MechatronicsT1S_EBCM_ETH_SocketConn: remote-addresss=EBCM_ETH_Eth1_Eth_v22_SPM_Dynamic_SA
                i-pdu-identifiers:
                  EBCM_ETH_Eth1_Eth_v22_PDU_SYS_SMUnicastRxMechatronicsT1S_Info_Identifier
                  EBCM_ETH_Eth1_Eth_v22_PDU_SYS_SMUnicastTxMechatronicsT1S_Info_Identifier
            EBCM_ETH_Eth1_Eth_v22_SPM_Dynamic_SA
              application endpoint EBCM_ETH_Eth1_Eth_v22_SPM_Dynamic_AEP: max-number-of-connections=6, network-endpoint=EBCM_ETH_Eth1_Eth_v22_ANY_NEP, priority=1, tp-configuration=udp-tp=udp-tp-port={dynamically-assigned=false, port-number=30480}
            EBCM_ETH_Eth1_Eth_v22_50003_SA: connector=EBCM_ETH_Eth_v22_1
              application endpoint EBCM_ETH_Eth1_Eth_v22_50003_AEP: max-number-of-connections=14, network-endpoint=EBCM_ETH_Eth1_Eth_v22_NEP, priority=3, tp-configuration=udp-tp=udp-tp-port=port-number=50003
            EBCM_ETH_Eth1_Eth_v22_PDU_SYS_PMUnicastMechatronicsT1S_Wakeup_SA: connector=EBCM_ETH_Eth_v22_1
              application endpoint EBCM_ETH_Eth1_Eth_v22_PDU_SYS_PMUnicastMechatronicsT1S_Wakeup_AEP: max-number-of-connections=6, network-endpoint=EBCM_ETH_Eth1_Eth_v22_NEP, priority=0, tp-configuration=udp-tp=udp-tp-port=port-number=30480
              static socket connection PDU_SYS_PMUnicastMechatronicsT1S_Wakeup_MechatronicsT1S_EBCM_ETH_SocketConn: i-pdu-identifiers=EBCM_ETH_Eth1_Eth_v22_PDU_SYS_PMUnicastTxMechatronicsT1S_Wakeup_Identifier, remote-addresss=EBCM_ETH_Eth1_Eth_v22_SPM_Dynamic_SA
            EBCM_ETH_Eth1_Eth_v22_SPM_TxMulticast_SA: connector=EBCM_ETH_Eth_v22_1
              application endpoint EBCM_ETH_Eth1_Eth_v22_SPM_TxMulticast_AEP: max-number-of-connections=6, network-endpoint=EBCM_ETH_Eth1_Eth_v22_NEP, priority=0, tp-configuration=udp-tp=udp-tp-port=port-number=30480
              static socket connection EBCM_ETH_Eth1_Eth_v22_SPM_TxMulticast_SocketConn: i-pdu-identifiers=EBCM_ETH_Eth1_Eth_v22_PDU_SYS_PMMulticastTxMechatronicsT1S_Heartbeat_Identifier, remote-addresss=EBCM_ETH_Eth1_Eth_v22_SPM_Multicast_SA
            EBCM_ETH_Eth1_Eth_v22_SPM_Multicast_SA
              application endpoint EBCM_ETH_Eth1_Eth_v22_SPM_Multicast_AEP: max-number-of-connections=6, network-endpoint=EBCM_ETH_Eth1_Eth_v22_SPM_Multicast_NEP, priority=1, tp-configuration=udp-tp=udp-tp-port=port-number=30480
            EBCM_ETH_Eth1_Eth_v22_SDMulticast_SA: multicast-connector=EBCM_ETH_Eth_v22_1
              application endpoint EBCM_ETH_Eth1_Eth_v22_SDMulticast_AEP: max-number-of-connections=1, network-endpoint=EBCM_ETH_Eth1_Eth_v22_SDMulticast_NEP, priority=1, tp-configuration=udp-tp=udp-tp-port=port-number=30490
              static socket connection EBCM_ETH_Eth1_Eth_v22_SDMulticast_SocketConn: i-pdu-identifiers=EBCM_ETH_Eth1_Eth_v22_SDMulticastRx_Identifier, remote-addresss=EBCM_ETH_Eth1_Eth_v22_Dynamic_SA
            EBCM_ETH_Eth1_Eth_v22_50000_SA: connector=EBCM_ETH_Eth_v22_1
              application endpoint EBCM_ETH_Eth1_Eth_v22_50000_AEP: network-endpoint=EBCM_ETH_Eth1_Eth_v22_NEP, priority=0, tp-configuration=udp-tp=udp-tp-port=port-number=50000
        vlan v22: vlan-identifier=22  # MechatronicsT1S
      Eth_v23: comm-connectors=EBCM_ETH_Eth_v23_2
        pdu triggering DummyTriggering_DO_NOT_ENABLE_Port_50000: pdu=DummyPDU_DO_NOT_ENABLE_Eth_v23_50000, to EBCM_ETH
        pdu triggering EBCM_ETH_Eth2_Eth_v23_SDMulticastRx: pdu=GPDU_EBCM_ETH_Eth2_Eth_v23_SDMulticastRx, to EBCM_ETH
        pdu triggering EBCM_ETH_Eth2_Eth_v23_SDUnicastRx: pdu=GPDU_EBCM_ETH_Eth2_Eth_v23_SDUnicastRx, to EBCM_ETH
        pdu triggering EBCM_ETH_Eth2_Eth_v23_SDUnicastTx: pdu=GPDU_EBCM_ETH_Eth2_Eth_v23_SDUnicastTx, from EBCM_ETH
        pdu triggering PDU_HC_0D8B8001_Rx: pdu=PDU_HC_0D8B8001, to EBCM_ETH
        pdu triggering PDU_H_0C5C8001_Tx: pdu=PDU_H_0C5C8001, from EBCM_ETH
        pdu triggering PDU_SYS_PMMulticastTxMechatronicsT1S_Eth2_Heartbeat: pdu=PDU_SYS_PMMulticastTxMechatronicsT1S_Eth2_Heartbeat, from EBCM_ETH
        pdu triggering PDU_SYS_PMUnicastTxMechatronicsT1S_Eth2_Wakeup: pdu=PDU_SYS_PMUnicastTxMechatronicsT1S_Eth2_Wakeup, from EBCM_ETH
        pdu triggering PDU_SYS_SMUnicastRxMechatronicsT1S_Eth2_Info: pdu=PDU_SYS_SMUnicastRxMechatronicsT1S_Eth2_Info, to EBCM_ETH
        pdu triggering PDU_SYS_SMUnicastTxMechatronicsT1S_Eth2_Info: pdu=PDU_SYS_SMUnicastTxMechatronicsT1S_Eth2_Info, from EBCM_ETH
        pdu triggering SPDU_HC_0D8B8001_Rx: pdu=SPDU_HC_0D8B8001, to EBCM_ETH
        pdu triggering SPDU_H_0C5C8001_Tx: pdu=SPDU_H_0C5C8001, from EBCM_ETH
        pdu triggering SPDU_SYS_PMMulticastTxMechatronicsT1S_Eth2_Heartbeat: pdu=SPDU_SYS_PMMulticastTxMechatronicsT1S_Eth2_Heartbeat, from EBCM_ETH
        pdu triggering SPDU_SYS_SMUnicastRxMechatronicsT1S_Eth2_Info: pdu=SPDU_SYS_SMUnicastRxMechatronicsT1S_Eth2_Info, to EBCM_ETH
        pdu triggering SPDU_SYS_SMUnicastTxMechatronicsT1S_Eth2_Info: pdu=SPDU_SYS_SMUnicastTxMechatronicsT1S_Eth2_Info, from EBCM_ETH
        pdu triggering Secured_EBCM_ETH_Eth2_Eth_v23_SDMulticastRx: pdu=SPDU_EBCM_ETH_Eth2_Eth_v23_SDMulticastRx, to EBCM_ETH
        pdu triggering Secured_EBCM_ETH_Eth2_Eth_v23_SDUnicastRx: pdu=SPDU_EBCM_ETH_Eth2_Eth_v23_SDUnicastRx, to EBCM_ETH
        pdu triggering Secured_EBCM_ETH_Eth2_Eth_v23_SDUnicastTx: pdu=SPDU_EBCM_ETH_Eth2_Eth_v23_SDUnicastTx, from EBCM_ETH
        5 x network endpoint:
          EBCM_ETH_Eth2_Eth_v23_ANY_NEP: network-endpoint-addresses=ipv-4-configuration={ip-address-keep-behavior=FORGET, ipv-4-address=ANY, ipv-4-address-source=FIXED, network-mask=0.0.0.0, ttl=12}
          EBCM_ETH_Eth2_Eth_v23_NEP: network-endpoint-addresses=ipv-4-configuration={ip-address-keep-behavior=STORE-PERSISTENTLY, ipv-4-address=10.23.6.33, ipv-4-address-source=FIXED, network-mask=255.255.0.0, ttl=30}
          VMCIC_Eth_v23_NEP: network-endpoint-addresses=ipv-4-configuration={ip-address-keep-behavior=STORE-PERSISTENTLY, ipv-4-address=10.23.1.129, ipv-4-address-source=FIXED, network-mask=255.255.0.0, ttl=30}
          EBCM_ETH_Eth2_Eth_v23_SPM_Multicast_NEP
            network-endpoint-addresses:
              ipv-4-configuration={ip-address-keep-behavior=FORGET, ipv-4-address=239.195.255.254, ipv-4-address-source=FIXED, network-mask=255.255.255.0, ttl=12}
              mac-multicast-configuration=EBCM_ETH_Eth2_Eth_v23_SPM_MacMulticastGroup
          EBCM_ETH_Eth2_Eth_v23_SDMulticast_NEP
            network-endpoint-addresses:
              ipv-4-configuration={ip-address-keep-behavior=FORGET, ipv-4-address=239.195.255.255, ipv-4-address-source=FIXED, ttl=12}
              mac-multicast-configuration=EBCM_ETH_Eth2_Eth_v23_SD_MacMulticastGroup
        so-ad-config:
          10 x socket address, all with allowed-tcp-options=TcpOptionFilterList, udp-checksum-handling=UDP-CHECKSUM-ENABLED:
            EBCM_ETH_Eth2_Eth_v23_Dynamic_SA
              application endpoint EBCM_ETH_Eth2_Eth_v23_Dynamic_AEP: max-number-of-connections=14, network-endpoint=EBCM_ETH_Eth2_Eth_v23_ANY_NEP, priority=1, tp-configuration=udp-tp=udp-tp-port={dynamically-assigned=true, port-number=0}
            EBCM_ETH_Eth2_Eth_v23_SDUnicast_SA: connector=EBCM_ETH_Eth_v23_2
              application endpoint EBCM_ETH_Eth2_Eth_v23_SDUnicast_AEP: max-number-of-connections=1, network-endpoint=EBCM_ETH_Eth2_Eth_v23_NEP, priority=1, tp-configuration=udp-tp=udp-tp-port=port-number=30490
              static socket connection EBCM_ETH_Eth2_Eth_v23_SDUnicast_SocketConn: i-pdu-identifiers=[EBCM_ETH_Eth2_Eth_v23_SDUnicastRx_Identifier, EBCM_ETH_Eth2_Eth_v23_SDUnicastTx_Identifier], remote-addresss=EBCM_ETH_Eth2_Eth_v23_Dynamic_SA
            EBCM_ETH_Eth2_Eth_v23_PDU_SYS_SMUnicastMechatronicsT1S_Eth2_Info_SA: connector=EBCM_ETH_Eth_v23_2
              application endpoint EBCM_ETH_Eth2_Eth_v23_PDU_SYS_SMUnicastMechatronicsT1S_Eth2_Info_AEP: max-number-of-connections=6, network-endpoint=EBCM_ETH_Eth2_Eth_v23_NEP, priority=0, tp-configuration=udp-tp=udp-tp-port=port-number=30480
              static socket connection PDU_SYS_SMUnicastMechatronicsT1S_Eth2_Info_MechatronicsT1S_Eth2_EBCM_ETH_SocketConn: remote-addresss=EBCM_ETH_Eth2_Eth_v23_SPM_Dynamic_SA
                i-pdu-identifiers:
                  EBCM_ETH_Eth2_Eth_v23_PDU_SYS_SMUnicastRxMechatronicsT1S_Eth2_Info_Identifier
                  EBCM_ETH_Eth2_Eth_v23_PDU_SYS_SMUnicastTxMechatronicsT1S_Eth2_Info_Identifier
            EBCM_ETH_Eth2_Eth_v23_SPM_Dynamic_SA
              application endpoint EBCM_ETH_Eth2_Eth_v23_SPM_Dynamic_AEP: max-number-of-connections=6, network-endpoint=EBCM_ETH_Eth2_Eth_v23_ANY_NEP, priority=1, tp-configuration=udp-tp=udp-tp-port={dynamically-assigned=false, port-number=30480}
            EBCM_ETH_Eth2_Eth_v23_50003_SA: connector=EBCM_ETH_Eth_v23_2
              application endpoint EBCM_ETH_Eth2_Eth_v23_50003_AEP: max-number-of-connections=14, network-endpoint=EBCM_ETH_Eth2_Eth_v23_NEP, priority=3, tp-configuration=udp-tp=udp-tp-port=port-number=50003
            EBCM_ETH_Eth2_Eth_v23_SPM_TxMulticast_SA: connector=EBCM_ETH_Eth_v23_2
              application endpoint EBCM_ETH_Eth2_Eth_v23_SPM_TxMulticast_AEP: max-number-of-connections=6, network-endpoint=EBCM_ETH_Eth2_Eth_v23_NEP, priority=0, tp-configuration=udp-tp=udp-tp-port=port-number=30480
              static socket connection EBCM_ETH_Eth2_Eth_v23_SPM_TxMulticast_SocketConn: i-pdu-identifiers=EBCM_ETH_Eth2_Eth_v23_PDU_SYS_PMMulticastTxMechatronicsT1S_Eth2_Heartbeat_Identifier, remote-addresss=EBCM_ETH_Eth2_Eth_v23_SPM_Multicast_SA
            EBCM_ETH_Eth2_Eth_v23_SPM_Multicast_SA
              application endpoint EBCM_ETH_Eth2_Eth_v23_SPM_Multicast_AEP: max-number-of-connections=6, network-endpoint=EBCM_ETH_Eth2_Eth_v23_SPM_Multicast_NEP, priority=1, tp-configuration=udp-tp=udp-tp-port=port-number=30480
            EBCM_ETH_Eth2_Eth_v23_PDU_SYS_PMUnicastMechatronicsT1S_Eth2_Wakeup_SA: connector=EBCM_ETH_Eth_v23_2
              application endpoint EBCM_ETH_Eth2_Eth_v23_PDU_SYS_PMUnicastMechatronicsT1S_Eth2_Wakeup_AEP: max-number-of-connections=6, network-endpoint=EBCM_ETH_Eth2_Eth_v23_NEP, priority=0, tp-configuration=udp-tp=udp-tp-port=port-number=30480
              static socket connection PDU_SYS_PMUnicastMechatronicsT1S_Eth2_Wakeup_MechatronicsT1S_Eth2_EBCM_ETH_SocketConn: i-pdu-identifiers=EBCM_ETH_Eth2_Eth_v23_PDU_SYS_PMUnicastTxMechatronicsT1S_Eth2_Wakeup_Identifier, remote-addresss=EBCM_ETH_Eth2_Eth_v23_SPM_Dynamic_SA
            EBCM_ETH_Eth2_Eth_v23_SDMulticast_SA: multicast-connector=EBCM_ETH_Eth_v23_2
              application endpoint EBCM_ETH_Eth2_Eth_v23_SDMulticast_AEP: max-number-of-connections=1, network-endpoint=EBCM_ETH_Eth2_Eth_v23_SDMulticast_NEP, priority=1, tp-configuration=udp-tp=udp-tp-port=port-number=30490
              static socket connection EBCM_ETH_Eth2_Eth_v23_SDMulticast_SocketConn: i-pdu-identifiers=EBCM_ETH_Eth2_Eth_v23_SDMulticastRx_Identifier, remote-addresss=EBCM_ETH_Eth2_Eth_v23_Dynamic_SA
            EBCM_ETH_Eth2_Eth_v23_50000_SA: connector=EBCM_ETH_Eth_v23_2
              application endpoint EBCM_ETH_Eth2_Eth_v23_50000_AEP: network-endpoint=EBCM_ETH_Eth2_Eth_v23_NEP, priority=0, tp-configuration=udp-tp=udp-tp-port=port-number=50000
        vlan v23: vlan-identifier=23  # MechatronicsT1S_Eth2
      Eth_v40
        vlan v40: vlan-identifier=40  # Ultifi
      Eth_v49
        vlan v49: vlan-identifier=49  # Radar
      Eth_v50
        vlan v50: vlan-identifier=50  # InVehicle
      Eth_v51
        vlan v51: vlan-identifier=51  # OnBoardTT
      Eth_v52: comm-connectors=[EBCM_ETH_Eth_v52_1, EBCM_ETH_Eth_v52_2]
        pdu triggering EBCM_ETH_Eth1_Eth_v52_XCP_Request_From_TT3_To_EBCM_ETH_InVehicle: pdu=GPDU_EBCM_ETH_Eth1_Eth_v52_XCP_Request_From_TT3_To_EBCM_ETH_InVehicle, to EBCM_ETH
        pdu triggering EBCM_ETH_Eth1_Eth_v52_XCP_Request_From_TT8_To_EBCM_ETH_InVehicle: pdu=GPDU_EBCM_ETH_Eth1_Eth_v52_XCP_Request_From_TT8_To_EBCM_ETH_InVehicle, to EBCM_ETH
        pdu triggering EBCM_ETH_Eth1_Eth_v52_XCP_Response_From_EBCM_ETH_To_TT3_InVehicle: pdu=GPDU_EBCM_ETH_Eth1_Eth_v52_XCP_Response_From_EBCM_ETH_To_TT3_InVehicle, from EBCM_ETH
        pdu triggering EBCM_ETH_Eth1_Eth_v52_XCP_Response_From_EBCM_ETH_To_TT8_InVehicle: pdu=GPDU_EBCM_ETH_Eth1_Eth_v52_XCP_Response_From_EBCM_ETH_To_TT8_InVehicle, from EBCM_ETH
        pdu triggering OBD_Req_From_TT8_ZEV_To_AllOBDNodes_AllNetworks_On_InVehicleIP_connector_PDU_Triggering: pdu=OBD_Req_From_TT8_ZEV_To_AllOBDNodes_AllNetworks_On_InVehicleIP_connector, to EBCM_ETH
        pdu triggering OBD_Req_From_TT8_ZEV_To_EBCM_ETH_Eth2_On_InVehicleIP_connector_PDU_Triggering: pdu=OBD_Req_From_TT8_ZEV_To_EBCM_ETH_Eth2_On_InVehicleIP_connector, to EBCM_ETH
        pdu triggering OBD_Rsp_From_EBCM_ETH_Eth2_InVehicleIP_To_TT8_ZEV_On_InVehicleIP_connector_PDU_Triggering: pdu=OBD_Rsp_From_EBCM_ETH_Eth2_InVehicleIP_To_TT8_ZEV_On_InVehicleIP_connector, from EBCM_ETH
        pdu triggering PDU_SYS_ARPLearning: pdu=PDU_SYS_ARPLearning, to EBCM_ETH
        pdu triggering SPDU_SYS_ARPLearning: pdu=SPDU_SYS_ARPLearning, to EBCM_ETH
        pdu triggering USDT_Req_From_TT1_To_AllNodes_AllNetworks_On_InVehicleIP_connector_PDU_Triggering: pdu=USDT_Req_From_TT1_To_AllNodes_AllNetworks_On_InVehicleIP_connector, to EBCM_ETH
        pdu triggering USDT_Req_From_TT1_To_EBCM_ETH_Eth2_On_InVehicleIP_connector_PDU_Triggering: pdu=USDT_Req_From_TT1_To_EBCM_ETH_Eth2_On_InVehicleIP_connector, to EBCM_ETH
        pdu triggering USDT_Req_From_TT3_To_AllNodes_AllNetworks_On_InVehicleIP_connector_PDU_Triggering: pdu=USDT_Req_From_TT3_To_AllNodes_AllNetworks_On_InVehicleIP_connector, to EBCM_ETH
        pdu triggering USDT_Req_From_TT3_To_EBCM_ETH_Eth2_On_InVehicleIP_connector_PDU_Triggering: pdu=USDT_Req_From_TT3_To_EBCM_ETH_Eth2_On_InVehicleIP_connector, to EBCM_ETH
        pdu triggering USDT_Req_From_TT4_To_AllNodes_AllNetworks_On_InVehicleIP_connector_PDU_Triggering: pdu=USDT_Req_From_TT4_To_AllNodes_AllNetworks_On_InVehicleIP_connector, to EBCM_ETH
        pdu triggering USDT_Req_From_TT4_To_EBCM_ETH_Eth2_On_InVehicleIP_connector_PDU_Triggering: pdu=USDT_Req_From_TT4_To_EBCM_ETH_Eth2_On_InVehicleIP_connector, to EBCM_ETH
        pdu triggering USDT_Req_From_TT5_To_AllNodes_AllNetworks_On_InVehicleIP_connector_PDU_Triggering: pdu=USDT_Req_From_TT5_To_AllNodes_AllNetworks_On_InVehicleIP_connector, to EBCM_ETH
        pdu triggering USDT_Req_From_TT5_To_EBCM_ETH_Eth1_On_InVehicleIP_connector_PDU_Triggering: pdu=USDT_Req_From_TT5_To_EBCM_ETH_Eth1_On_InVehicleIP_connector, to EBCM_ETH
        pdu triggering USDT_Req_From_TT8_To_AllNodes_AllNetworks_On_InVehicleIP_connector_PDU_Triggering: pdu=USDT_Req_From_TT8_To_AllNodes_AllNetworks_On_InVehicleIP_connector, to EBCM_ETH
        pdu triggering USDT_Req_From_TT8_To_EBCM_ETH_Eth2_On_InVehicleIP_connector_PDU_Triggering: pdu=USDT_Req_From_TT8_To_EBCM_ETH_Eth2_On_InVehicleIP_connector, to EBCM_ETH
        pdu triggering USDT_Rsp_From_EBCM_ETH_Eth1_InVehicleIP_To_TT5_On_InVehicleIP_connector_PDU_Triggering: pdu=USDT_Rsp_From_EBCM_ETH_Eth1_InVehicleIP_To_TT5_On_InVehicleIP_connector, from EBCM_ETH
        pdu triggering USDT_Rsp_From_EBCM_ETH_Eth2_InVehicleIP_To_TT1_On_InVehicleIP_connector_PDU_Triggering: pdu=USDT_Rsp_From_EBCM_ETH_Eth2_InVehicleIP_To_TT1_On_InVehicleIP_connector, from EBCM_ETH
        pdu triggering USDT_Rsp_From_EBCM_ETH_Eth2_InVehicleIP_To_TT3_On_InVehicleIP_connector_PDU_Triggering: pdu=USDT_Rsp_From_EBCM_ETH_Eth2_InVehicleIP_To_TT3_On_InVehicleIP_connector, from EBCM_ETH
        pdu triggering USDT_Rsp_From_EBCM_ETH_Eth2_InVehicleIP_To_TT4_On_InVehicleIP_connector_PDU_Triggering: pdu=USDT_Rsp_From_EBCM_ETH_Eth2_InVehicleIP_To_TT4_On_InVehicleIP_connector, from EBCM_ETH
        pdu triggering USDT_Rsp_From_EBCM_ETH_Eth2_InVehicleIP_To_TT8_On_InVehicleIP_connector_PDU_Triggering: pdu=USDT_Rsp_From_EBCM_ETH_Eth2_InVehicleIP_To_TT8_On_InVehicleIP_connector, from EBCM_ETH
        pdu triggering UUDT_Rsp_From_EBCM_ETH_Eth1_InVehicleIP_To_TT5_On_InVehicleIP_connector_PDU_Triggering: pdu=UUDT_Rsp_From_EBCM_ETH_Eth1_InVehicleIP_To_TT5_On_InVehicleIP_connector, from EBCM_ETH
        pdu triggering UUDT_Rsp_From_EBCM_ETH_Eth2_InVehicleIP_To_TT1_On_InVehicleIP_connector_PDU_Triggering: pdu=UUDT_Rsp_From_EBCM_ETH_Eth2_InVehicleIP_To_TT1_On_InVehicleIP_connector, from EBCM_ETH
        pdu triggering UUDT_Rsp_From_EBCM_ETH_Eth2_InVehicleIP_To_TT3_On_InVehicleIP_connector_PDU_Triggering: pdu=UUDT_Rsp_From_EBCM_ETH_Eth2_InVehicleIP_To_TT3_On_InVehicleIP_connector, from EBCM_ETH
        pdu triggering UUDT_Rsp_From_EBCM_ETH_Eth2_InVehicleIP_To_TT4_On_InVehicleIP_connector_PDU_Triggering: pdu=UUDT_Rsp_From_EBCM_ETH_Eth2_InVehicleIP_To_TT4_On_InVehicleIP_connector, from EBCM_ETH
        pdu triggering UUDT_Rsp_From_EBCM_ETH_Eth2_InVehicleIP_To_TT8_On_InVehicleIP_connector_PDU_Triggering: pdu=UUDT_Rsp_From_EBCM_ETH_Eth2_InVehicleIP_To_TT8_On_InVehicleIP_connector, from EBCM_ETH
        6 x network endpoint:
          EBCM_ETH_Eth2_Eth_v52_NEP: network-endpoint-addresses=ipv-4-configuration={ipv-4-address=10.52.6.2, ipv-4-address-source=FIXED, network-mask=255.255.0.0, ttl=12}
          GTWY_Eth_v52_NEP: network-endpoint-addresses=ipv-4-configuration={ipv-4-address=10.52.1.119, ipv-4-address-source=FIXED, network-mask=255.255.0.0, ttl=12}
          GTWY_Eth1_Eth_v52_NEP: network-endpoint-addresses=ipv-4-configuration={ip-address-keep-behavior=STORE-PERSISTENTLY, ipv-4-address=10.52.1.119, ipv-4-address-source=FIXED, network-mask=255.255.0.0, ttl=30}
          EBCM_ETH_Eth1_Eth_v52_ANY_NEP: network-endpoint-addresses=ipv-4-configuration={ip-address-keep-behavior=FORGET, ipv-4-address=ANY, ipv-4-address-source=FIXED, network-mask=0.0.0.0, ttl=12}
          EBCM_ETH_Eth1_Eth_v52_ARPMulticast_NEP
            network-endpoint-addresses:
              ipv-4-configuration={ip-address-keep-behavior=FORGET, ipv-4-address=239.195.255.253, ipv-4-address-source=FIXED, network-mask=255.255.255.0, ttl=12}
              mac-multicast-configuration=EBCM_ETH_Eth1_Eth_v52_ARP_MacMulticastGroup
          EBCM_ETH_Eth1_Eth_v52_NEP: network-endpoint-addresses=ipv-4-configuration={ip-address-keep-behavior=STORE-PERSISTENTLY, ipv-4-address=10.52.6.33, ipv-4-address-source=FIXED, network-mask=255.255.0.0, ttl=30}
        so-ad-config:
          10 x socket address:
            EBCM_ETH_Eth1_Eth_v52_54000_SA: connector=EBCM_ETH_Eth_v52_1
              application endpoint EBCM_ETH_Eth1_Eth_v52_54000_AEP: network-endpoint=EBCM_ETH_Eth1_Eth_v52_NEP, tp-configuration=tcp-tp={keep-alive-interval=1.0, keep-alive-probes-max=3, keep-alive-time=5.0, keep-alives=true, nagles-algorithm=false, receive-window-min=65535, tcp-tp-port=port-number=54000}
              static socket connection GTWY_EBCM_ETH_Eth1_DoSoAD_Eth_v52_SockCon_Clnt: remote-addresss=GTWY_Eth_v52_49210_SA, tcp-role=LISTEN
                i-pdu-identifiers:
                  USDT_Req_From_TT5_To_AllNodes_AllNetworks_To_EBCM_ETH_Eth1_On_InVehicleIP_connector_SoAD_ID
                  USDT_Req_From_TT5_To_EBCM_ETH_Eth1_On_InVehicleIP_connector_SoAD_ID
                  USDT_Rsp_From_EBCM_ETH_Eth1_InVehicleIP_To_TT5_On_InVehicleIP_connector_SoAD_ID
                  UUDT_Rsp_From_EBCM_ETH_Eth1_InVehicleIP_To_TT5_On_InVehicleIP_connector_SoAD_ID
            EBCM_ETH_Eth2_Eth_v52_54000_SA: connector=EBCM_ETH_Eth_v52_2
              application endpoint EBCM_ETH_Eth2_Eth_v52_54000_AEP: network-endpoint=EBCM_ETH_Eth2_Eth_v52_NEP, tp-configuration=tcp-tp={keep-alive-interval=1.0, keep-alive-probes-max=3, keep-alive-time=5.0, keep-alives=true, nagles-algorithm=false, receive-window-min=65535, tcp-tp-port=port-number=54000}
              static socket connection GTWY_EBCM_ETH_Eth2_DoSoAD_Eth_v52_SockCon_Clnt: remote-addresss=GTWY_Eth_v52_49294_SA, tcp-role=LISTEN
                i-pdu-identifiers:
                  OBD_Req_From_TT8_ZEV_To_AllOBDNodes_AllNetworks_To_EBCM_ETH_Eth2_On_InVehicleIP_connector_SoAD_ID
                  OBD_Req_From_TT8_ZEV_To_EBCM_ETH_Eth2_On_InVehicleIP_connector_SoAD_ID
                  OBD_Rsp_From_EBCM_ETH_Eth2_InVehicleIP_To_TT8_ZEV_On_InVehicleIP_connector_SoAD_ID
                  USDT_Req_From_TT1_To_AllNodes_AllNetworks_To_EBCM_ETH_Eth2_On_InVehicleIP_connector_SoAD_ID
                  USDT_Req_From_TT1_To_EBCM_ETH_Eth2_On_InVehicleIP_connector_SoAD_ID
                  USDT_Req_From_TT3_To_AllNodes_AllNetworks_To_EBCM_ETH_Eth2_On_InVehicleIP_connector_SoAD_ID
                  USDT_Req_From_TT3_To_EBCM_ETH_Eth2_On_InVehicleIP_connector_SoAD_ID
                  USDT_Req_From_TT4_To_AllNodes_AllNetworks_To_EBCM_ETH_Eth2_On_InVehicleIP_connector_SoAD_ID
                  USDT_Req_From_TT4_To_EBCM_ETH_Eth2_On_InVehicleIP_connector_SoAD_ID
                  USDT_Req_From_TT8_To_AllNodes_AllNetworks_To_EBCM_ETH_Eth2_On_InVehicleIP_connector_SoAD_ID
                  USDT_Req_From_TT8_To_EBCM_ETH_Eth2_On_InVehicleIP_connector_SoAD_ID
                  USDT_Rsp_From_EBCM_ETH_Eth2_InVehicleIP_To_TT1_On_InVehicleIP_connector_SoAD_ID
                  USDT_Rsp_From_EBCM_ETH_Eth2_InVehicleIP_To_TT3_On_InVehicleIP_connector_SoAD_ID
                  USDT_Rsp_From_EBCM_ETH_Eth2_InVehicleIP_To_TT4_On_InVehicleIP_connector_SoAD_ID
                  USDT_Rsp_From_EBCM_ETH_Eth2_InVehicleIP_To_TT8_On_InVehicleIP_connector_SoAD_ID
                  UUDT_Rsp_From_EBCM_ETH_Eth2_InVehicleIP_To_TT1_On_InVehicleIP_connector_SoAD_ID
                  UUDT_Rsp_From_EBCM_ETH_Eth2_InVehicleIP_To_TT3_On_InVehicleIP_connector_SoAD_ID
                  UUDT_Rsp_From_EBCM_ETH_Eth2_InVehicleIP_To_TT4_On_InVehicleIP_connector_SoAD_ID
                  UUDT_Rsp_From_EBCM_ETH_Eth2_InVehicleIP_To_TT8_On_InVehicleIP_connector_SoAD_ID
            GTWY_Eth_v52_49210_SA
              application endpoint GTWY_Eth_v52_49210_AEP: network-endpoint=GTWY_Eth_v52_NEP, tp-configuration=tcp-tp={keep-alive-interval=1.0, keep-alive-probes-max=3, keep-alive-time=5.0, keep-alives=true, nagles-algorithm=false, receive-window-min=65535, tcp-tp-port=port-number=49210}
            GTWY_Eth_v52_49294_SA
              application endpoint GTWY_Eth_v52_49294_AEP: network-endpoint=GTWY_Eth_v52_NEP, tp-configuration=tcp-tp={keep-alive-interval=1.0, keep-alive-probes-max=3, keep-alive-time=5.0, keep-alives=true, nagles-algorithm=false, receive-window-min=65535, tcp-tp-port=port-number=49294}
            GTWY_Eth1_Eth_v52_TT3_SA: allowed-tcp-options=TcpOptionFilterList, udp-checksum-handling=UDP-CHECKSUM-ENABLED
              application endpoint GTWY_Eth1_Eth_v52_TT3_AEP: max-number-of-connections=1, network-endpoint=GTWY_Eth1_Eth_v52_NEP, priority=1, tp-configuration=udp-tp=udp-tp-port=port-number=49401
            EBCM_ETH_Eth1_Eth_v52_TT3_SA: allowed-tcp-options=TcpOptionFilterList, connector=EBCM_ETH_Eth_v52_1, udp-checksum-handling=UDP-CHECKSUM-ENABLED
              application endpoint EBCM_ETH_Eth1_Eth_v52_TT3_AEP: max-number-of-connections=1, network-endpoint=EBCM_ETH_Eth1_Eth_v52_NEP, priority=1, tp-configuration=udp-tp=udp-tp-port=port-number=49523
              static socket connection EBCM_ETH_Eth1_Eth_v52_TT3_SocketConn: remote-addresss=GTWY_Eth1_Eth_v52_TT3_SA
                i-pdu-identifiers:
                  EBCM_ETH_Eth1_Eth_v52_XCP_Request_From_TT3_To_EBCM_ETH_InVehicle_Identifier
                  EBCM_ETH_Eth1_Eth_v52_XCP_Response_From_EBCM_ETH_To_TT3_InVehicle_Identifier
            GTWY_Eth1_Eth_v52_TT8_SA: allowed-tcp-options=TcpOptionFilterList, udp-checksum-handling=UDP-CHECKSUM-ENABLED
              application endpoint GTWY_Eth1_Eth_v52_TT8_AEP: max-number-of-connections=1, network-endpoint=GTWY_Eth1_Eth_v52_NEP, priority=1, tp-configuration=udp-tp=udp-tp-port=port-number=49400
            EBCM_ETH_Eth1_Eth_v52_TT8_SA: allowed-tcp-options=TcpOptionFilterList, connector=EBCM_ETH_Eth_v52_1, udp-checksum-handling=UDP-CHECKSUM-ENABLED
              application endpoint EBCM_ETH_Eth1_Eth_v52_TT8_AEP: max-number-of-connections=1, network-endpoint=EBCM_ETH_Eth1_Eth_v52_NEP, priority=1, tp-configuration=udp-tp=udp-tp-port=port-number=49522
              static socket connection EBCM_ETH_Eth1_Eth_v52_TT8_SocketConn: remote-addresss=GTWY_Eth1_Eth_v52_TT8_SA
                i-pdu-identifiers:
                  EBCM_ETH_Eth1_Eth_v52_XCP_Request_From_TT8_To_EBCM_ETH_InVehicle_Identifier
                  EBCM_ETH_Eth1_Eth_v52_XCP_Response_From_EBCM_ETH_To_TT8_InVehicle_Identifier
            EBCM_ETH_Eth1_Eth_v52_ARP_Dynamic_SA: allowed-tcp-options=TcpOptionFilterList, udp-checksum-handling=UDP-CHECKSUM-ENABLED
              application endpoint EBCM_ETH_Eth1_Eth_v52_ARP_Dynamic_AEP: max-number-of-connections=1, network-endpoint=EBCM_ETH_Eth1_Eth_v52_ANY_NEP, priority=1, tp-configuration=udp-tp=udp-tp-port={dynamically-assigned=false, port-number=49600}
            EBCM_ETH_Eth1_Eth_v52_ARPMulticast_SA: allowed-tcp-options=TcpOptionFilterList, multicast-connector=EBCM_ETH_Eth_v52_1, udp-checksum-handling=UDP-CHECKSUM-ENABLED
              application endpoint EBCM_ETH_Eth1_Eth_v52_ARPMulticast_AEP: max-number-of-connections=1, network-endpoint=EBCM_ETH_Eth1_Eth_v52_ARPMulticast_NEP, priority=1, tp-configuration=udp-tp=udp-tp-port=port-number=49650
              static socket connection v52_PDU_SYS_ARPLearning_SocketConn: i-pdu-identifiers=EBCM_ETH_Eth1_Eth_v52_PDU_SYS_ARPLearning_Identifier, remote-addresss=EBCM_ETH_Eth1_Eth_v52_ARP_Dynamic_SA
        vlan v52: vlan-identifier=52  # InVehicleT1S
    7 x mac multicast group:
      EBCM_ETH_Eth2_Eth_v23_SPM_MacMulticastGroup: mac-multicast-address=01:00:5e:43:ff:fe
      EBCM_ETH_Eth2_Eth_v23_SD_MacMulticastGroup: mac-multicast-address=01:00:5e:43:ff:ff
      EBCM_ETH_Eth2_Eth_v111_SPM_MacMulticastGroup: mac-multicast-address=01:00:5e:43:ff:fe
      EBCM_ETH_Eth1_Eth_v22_SPM_MacMulticastGroup: mac-multicast-address=01:00:5e:43:ff:fe
      EBCM_ETH_Eth1_Eth_v22_SD_MacMulticastGroup: mac-multicast-address=01:00:5e:43:ff:ff
      EBCM_ETH_Eth1_Eth_v111_SPM_MacMulticastGroup: mac-multicast-address=01:00:5e:43:ff:fe
      EBCM_ETH_Eth1_Eth_v52_ARP_MacMulticastGroup: mac-multicast-address=01:00:5e:43:ff:fd
  tcp option filter set TcpOptionFilterSet
    tcp option filter list TcpOptionFilterList: allowed-tcp-options=[0, 1, 2, 3, 4, 5]
package /Topologies/SDV/BCAN
  7 x i signal group, all with com-based-signal-group-transformations=ComBasedSafetyDataTransformation_PROFILE_11A:
    SrlDat636:  # Serial Data 636
      i-signal=[BrkSysPriBrkModToSecBrkModRtnRq, HydrlcBrkFncStatAchvd, LtElecPrkBrkActrAppStat, MnAutoCtlrBrkOprtlModeReq, MstrCylPistnTrvlCalcd, MstrCylPistnTrvlCalcdSts, PriBrkModFncTstTypActv, RtElecPrkBrkActrAppStat, SrlDat636_ARC, SrlDat636_CRC]
      system-signal-group=SrlDat636_SdvSystemSignalGroup
      end-to-end-transformation-i-signal-props{transformer=E2E_Transformer_PROFILE_11A, data-ids=5251, data-length=56}
    SrlDat637: i-signal=[BrkSysPriBrkModRtnCrdntn, SrlDat637_ARC, SrlDat637_CRC], system-signal-group=SrlDat637_SdvSystemSignalGroup, end-to-end-transformation-i-signal-props{transformer=E2E_Transformer_PROFILE_11A, data-ids=5001, data-length=56}  # Serial Data 637
    SrlDat638:  # Serial Data 638
      i-signal=[BrkSysSecBrkModRtnAvalFlg1, BrkSysSecBrkModRtnAvalFlg2, BrkSysSecBrkModRtnAvalFlg3, BrkSysSecBrkModRtnAvalFlg4, BrkSysSecBrkModRtnAvalFlg5, BrkSysSecBrkModRtnAvalFlg6, BrkSysSecBrkModRtnAvalFlg7, SecElecPrkBrkCmd, SrlDat638_ARC, SrlDat638_CRC]
      system-signal-group=SrlDat638_SdvSystemSignalGroup
      end-to-end-transformation-i-signal-props{transformer=E2E_Transformer_PROFILE_11A, data-ids=1291, data-length=32}
    SrlDat639: i-signal=[BrkSysSecBrkModRtnCrdntn, SrlDat639_ARC, SrlDat639_CRC], system-signal-group=SrlDat639_SdvSystemSignalGroup, end-to-end-transformation-i-signal-props{transformer=E2E_Transformer_PROFILE_11A, data-ids=8006, data-length=56}  # Serial Data 639
    SrlDat673:  # Serial Data 673
      i-signal=[HSV1DiagActFltd, HSV2DiagActFltd, PmpMtrDiagActFltd, RedntElecPrkBrkCmd, RedntWhlAnglrVelLF, RedntWhlAnglrVelRF, RedntWhlSpdSnsr_InvLF, RedntWhlSpdSnsr_InvRF, RmtActModeActv, SBMRmtActFltd, SBMSlfTstInfo, SrlDat673_ARC, SrlDat673_CRC, USV1DiagActFltd, USV2DiagActFltd]
      system-signal-group=SrlDat673_SdvSystemSignalGroup
      end-to-end-transformation-i-signal-props{transformer=E2E_Transformer_PROFILE_11A, data-ids=7498, data-length=64}
    SrlDat674: i-signal=[RedntWhlAnglrVelLR, RedntWhlAnglrVelRR, RedntWhlSpdSnsr_InvLR, RedntWhlSpdSnsr_InvRR, SrlDat674_ARC, SrlDat674_CRC], system-signal-group=SrlDat674_SdvSystemSignalGroup, end-to-end-transformation-i-signal-props{transformer=E2E_Transformer_PROFILE_11A, data-ids=6131, data-length=48}  # Serial Data 674
    SrlDat675: i-signal=[EBCMSlfTstInfo, HSV1DiagActPctg, HSV2DiagActPctg, PmpMtrDiagActSpdCmd, SrlDat675_ARC, SrlDat675_CRC, USV1DiagActPctg, USV2DiagActPctg], system-signal-group=SrlDat675_SdvSystemSignalGroup, end-to-end-transformation-i-signal-props{transformer=E2E_Transformer_PROFILE_11A, data-ids=5953, data-length=64}  # Serial Data 675
package /Topologies/SDV/Ethernet_1
  pdu PDU_SYS_PMMulticastRxPwrMgrMulti_Heartbeat:
    length=18
    transmission-mode-condition{data-filter=data-filter-type=ALWAYS, i-signal-in-i-pdu=PDU_SYS_PMMulticastRxPwrMgrMulti_Heartbeat_EBCM_ETH_Eth_v111_ISigToIPduMap}
    transmission-mode-true-timing=event-controlled-timing=number-of-repetitions=0
    transmission-mode-condition{data-filter=data-filter-type=ALWAYS, i-signal-in-i-pdu=PDU_SYS_PMMulticastRxPwrMgrMulti_Heartbeat_EBCM_ETH_Eth_v111_ISigToIPduMap}
    transmission-mode-true-timing=event-controlled-timing=number-of-repetitions=0
    unused-bit-pattern=0
    signal PwrMgrMulti_PwrMgrHeartbeatRx_Evt_EBCM_ETH_2_v111_ISignal: start 0, 144 bit, opaque, system signal PwrMgrMulti_PwrMgrHeartbeatRx_Evt_SystemSignal, data-transformations=SPM_SOMEIP_Data_Transformation, data-type-policy=TRANSFORMING-I-SIGNAL, i-signal-type=ARRAY, someip-transformation-i-signal-props{cs-error-reaction=AUTONOMOUS, transformer=SPM_SOMEIP_Transformer, message-type=NOTIFICATION, session-handling-sr=SESSION-HANDLING-INACTIVE}, transfer-property=TRIGGERED-ON-CHANGE, to EBCM_ETH(timeout 2.5 s)
  pdu PDU_SYS_PMMulticastRxPwrMgrMulti_Wakeup:
    length=36
    transmission-mode-condition{data-filter=data-filter-type=ALWAYS, i-signal-in-i-pdu=PDU_SYS_PMMulticastRxPwrMgrMulti_Wakeup_EBCM_ETH_Eth_v111_ISigToIPduMap}
    transmission-mode-true-timing=event-controlled-timing=number-of-repetitions=0
    transmission-mode-condition{data-filter=data-filter-type=ALWAYS, i-signal-in-i-pdu=PDU_SYS_PMMulticastRxPwrMgrMulti_Wakeup_EBCM_ETH_Eth_v111_ISigToIPduMap}
    transmission-mode-true-timing=event-controlled-timing=number-of-repetitions=0
    unused-bit-pattern=0
    signal PwrMgrMulti_PwrMgrWakeupRx_Evt_EBCM_ETH_2_v111_ISignal: start 0, 288 bit, opaque, system signal PwrMgrMulti_PwrMgrWakeupRx_Evt_SystemSignal, data-transformations=SPM_SOMEIP_Data_Transformation, data-type-policy=TRANSFORMING-I-SIGNAL, i-signal-type=ARRAY, someip-transformation-i-signal-props{cs-error-reaction=AUTONOMOUS, transformer=SPM_SOMEIP_Transformer, message-type=NOTIFICATION, session-handling-sr=SESSION-HANDLING-INACTIVE}, transfer-property=TRIGGERED-ON-CHANGE, to EBCM_ETH(timeout 2.5 s)
  pdu PDU_SYS_PMMulticastTxMechatronicsT1S_Eth2_Heartbeat: length=18, transmission-mode-condition{data-filter=data-filter-type=ALWAYS, i-signal-in-i-pdu=PDU_SYS_PMMulticastTxMechatronicsT1S_Eth2_Heartbeat_EBCM_ETH_Eth_v23_ISigToIPduMap}, transmission-mode-true-timing=event-controlled-timing=number-of-repetitions=0, unused-bit-pattern=0
    signal MechatronicsT1S_Eth2_PwrMgrHeartbeatTx_Evt_EBCM_ETH_2_v23_ISignal: start 0, 144 bit, opaque, system signal MechatronicsT1S_Eth2_PwrMgrHeartbeatTx_Evt_SystemSignal, data-transformations=SPM_SOMEIP_Data_Transformation, data-type-policy=TRANSFORMING-I-SIGNAL, i-signal-type=ARRAY, someip-transformation-i-signal-props{cs-error-reaction=AUTONOMOUS, transformer=SPM_SOMEIP_Transformer, message-type=NOTIFICATION, session-handling-sr=SESSION-HANDLING-INACTIVE}, transfer-property=TRIGGERED-ON-CHANGE
  pdu PDU_SYS_PMMulticastTxMechatronicsT1S_Heartbeat: length=18, transmission-mode-condition{data-filter=data-filter-type=ALWAYS, i-signal-in-i-pdu=PDU_SYS_PMMulticastTxMechatronicsT1S_Heartbeat_EBCM_ETH_Eth_v22_ISigToIPduMap}, transmission-mode-true-timing=event-controlled-timing=number-of-repetitions=0, unused-bit-pattern=0
    signal MechatronicsT1S_PwrMgrHeartbeatTx_Evt_EBCM_ETH_1_v22_ISignal: start 0, 144 bit, opaque, system signal MechatronicsT1S_PwrMgrHeartbeatTx_Evt_SystemSignal, data-transformations=SPM_SOMEIP_Data_Transformation, data-type-policy=TRANSFORMING-I-SIGNAL, i-signal-type=ARRAY, someip-transformation-i-signal-props{cs-error-reaction=AUTONOMOUS, transformer=SPM_SOMEIP_Transformer, message-type=NOTIFICATION, session-handling-sr=SESSION-HANDLING-INACTIVE}, transfer-property=TRIGGERED-ON-CHANGE
  5 x socket connection ipdu identifier set:
    Eth_v111
      4 x so con i pdu identifier, all with pdu-collection-trigger=ALWAYS:
        EBCM_ETH_Eth2_Eth_v111_PDU_SYS_PMMulticastRxPwrMgrMulti_Heartbeat_Identifier: header-id=4294873086, pdu-triggering=SPDU_SYS_PMMulticastRxPwrMgrMulti_Heartbeat
        EBCM_ETH_Eth2_Eth_v111_PDU_SYS_PMMulticastRxPwrMgrMulti_Wakeup_Identifier: header-id=4294873085, pdu-triggering=PDU_SYS_PMMulticastRxPwrMgrMulti_Wakeup
        EBCM_ETH_Eth1_Eth_v111_PDU_SYS_PMMulticastRxPwrMgrMulti_Heartbeat_Identifier: header-id=4294873086, pdu-triggering=SPDU_SYS_PMMulticastRxPwrMgrMulti_Heartbeat
        EBCM_ETH_Eth1_Eth_v111_PDU_SYS_PMMulticastRxPwrMgrMulti_Wakeup_Identifier: header-id=4294873085, pdu-triggering=PDU_SYS_PMMulticastRxPwrMgrMulti_Wakeup
    Eth_v21
      so con i pdu identifier EBCM_ETH_Eth1_Eth_v21_PDU_SYS_SMUnicastRxMechatronics_Eth2_Info_Identifier: header-id=4294807551, pdu-collection-trigger=ALWAYS, pdu-triggering=SPDU_SYS_SMUnicastRxMechatronics_Eth2_Info
      so con i pdu identifier EBCM_ETH_Eth1_Eth_v21_PDU_SYS_SMUnicastTxMechatronics_Eth2_Info_Identifier: header-id=4294807551, pdu-collection-trigger=ALWAYS, pdu-triggering=SPDU_SYS_SMUnicastTxMechatronics_Eth2_Info
    Eth_v22
      10 x so con i pdu identifier:
        EBCM_ETH_Eth1_Eth_v22_SDUnicastRx_Identifier: header-id=4294934784, pdu-collection-trigger=ALWAYS, pdu-triggering=Secured_EBCM_ETH_Eth1_Eth_v22_SDUnicastRx
        EBCM_ETH_Eth1_Eth_v22_PDU_SYS_SMUnicastRxMechatronicsT1S_Info_Identifier: header-id=4294807551, pdu-collection-trigger=ALWAYS, pdu-triggering=SPDU_SYS_SMUnicastRxMechatronicsT1S_Info
        HC_0CD68001_MechatronicsT1S_EBCM_ETH_Identifier: header-id=215384065, pdu-collection-semantics=QUEUED, pdu-collection-trigger=ALWAYS, pdu-triggering=SPDU_HC_0CD68001_Rx
        EBCM_ETH_Eth1_Eth_v22_SDUnicastTx_Identifier: header-id=4294934784, pdu-collection-trigger=ALWAYS, pdu-triggering=Secured_EBCM_ETH_Eth1_Eth_v22_SDUnicastTx
        EBCM_ETH_Eth1_Eth_v22_PDU_SYS_PMUnicastTxMechatronicsT1S_Wakeup_Identifier: header-id=4294873085, pdu-collection-trigger=ALWAYS, pdu-triggering=PDU_SYS_PMUnicastTxMechatronicsT1S_Wakeup
        EBCM_ETH_Eth1_Eth_v22_PDU_SYS_SMUnicastTxMechatronicsT1S_Info_Identifier: header-id=4294807551, pdu-collection-trigger=ALWAYS, pdu-triggering=SPDU_SYS_SMUnicastTxMechatronicsT1S_Info
        EBCM_ETH_Eth1_Eth_v22_PDU_SYS_PMMulticastTxMechatronicsT1S_Heartbeat_Identifier: header-id=4294873086, pdu-collection-trigger=ALWAYS, pdu-triggering=SPDU_SYS_PMMulticastTxMechatronicsT1S_Heartbeat
        H_0C5B8001_MechatronicsT1S_EBCM_ETH_Identifier: header-id=207323137, pdu-collection-semantics=QUEUED, pdu-collection-trigger=ALWAYS, pdu-triggering=SPDU_H_0C5B8001_Tx
        EBCM_ETH_Eth1_Eth_v22_SDMulticastRx_Identifier: header-id=4294934784, pdu-collection-trigger=ALWAYS, pdu-triggering=Secured_EBCM_ETH_Eth1_Eth_v22_SDMulticastRx
        DummyService_DO_NOT_ENABLE_Eth_v22_50000_Identifier: header-id=4293951489, pdu-collection-semantics=QUEUED, pdu-collection-trigger=NEVER, pdu-triggering=Eth_v22/DummyTriggering_DO_NOT_ENABLE_Port_50000
    Eth_v23
      10 x so con i pdu identifier:
        EBCM_ETH_Eth2_Eth_v23_SDUnicastRx_Identifier: header-id=4294934784, pdu-collection-trigger=ALWAYS, pdu-triggering=Secured_EBCM_ETH_Eth2_Eth_v23_SDUnicastRx
        EBCM_ETH_Eth2_Eth_v23_PDU_SYS_SMUnicastRxMechatronicsT1S_Eth2_Info_Identifier: header-id=4294807551, pdu-collection-trigger=ALWAYS, pdu-triggering=SPDU_SYS_SMUnicastRxMechatronicsT1S_Eth2_Info
        HC_0D8B8001_MechatronicsT1S_Eth2_EBCM_ETH_Identifier: header-id=227246081, pdu-collection-semantics=QUEUED, pdu-collection-trigger=ALWAYS, pdu-triggering=SPDU_HC_0D8B8001_Rx
        EBCM_ETH_Eth2_Eth_v23_SDUnicastTx_Identifier: header-id=4294934784, pdu-collection-trigger=ALWAYS, pdu-triggering=Secured_EBCM_ETH_Eth2_Eth_v23_SDUnicastTx
        EBCM_ETH_Eth2_Eth_v23_PDU_SYS_PMMulticastTxMechatronicsT1S_Eth2_Heartbeat_Identifier: header-id=4294873086, pdu-collection-trigger=ALWAYS, pdu-triggering=SPDU_SYS_PMMulticastTxMechatronicsT1S_Eth2_Heartbeat
        EBCM_ETH_Eth2_Eth_v23_PDU_SYS_PMUnicastTxMechatronicsT1S_Eth2_Wakeup_Identifier: header-id=4294873085, pdu-collection-trigger=ALWAYS, pdu-triggering=PDU_SYS_PMUnicastTxMechatronicsT1S_Eth2_Wakeup
        EBCM_ETH_Eth2_Eth_v23_PDU_SYS_SMUnicastTxMechatronicsT1S_Eth2_Info_Identifier: header-id=4294807551, pdu-collection-trigger=ALWAYS, pdu-triggering=SPDU_SYS_SMUnicastTxMechatronicsT1S_Eth2_Info
        H_0C5C8001_MechatronicsT1S_Eth2_EBCM_ETH_Identifier: header-id=207388673, pdu-collection-semantics=QUEUED, pdu-collection-trigger=ALWAYS, pdu-triggering=SPDU_H_0C5C8001_Tx
        EBCM_ETH_Eth2_Eth_v23_SDMulticastRx_Identifier: header-id=4294934784, pdu-collection-trigger=ALWAYS, pdu-triggering=Secured_EBCM_ETH_Eth2_Eth_v23_SDMulticastRx
        DummyService_DO_NOT_ENABLE_Eth_v23_50000_Identifier: header-id=4293951489, pdu-collection-semantics=QUEUED, pdu-collection-trigger=NEVER, pdu-triggering=Eth_v23/DummyTriggering_DO_NOT_ENABLE_Port_50000
    Eth_v52
      5 x so con i pdu identifier, all with pdu-collection-trigger=ALWAYS:
        EBCM_ETH_Eth1_Eth_v52_XCP_Request_From_TT3_To_EBCM_ETH_InVehicle_Identifier: pdu-triggering=EBCM_ETH_Eth1_Eth_v52_XCP_Request_From_TT3_To_EBCM_ETH_InVehicle
        EBCM_ETH_Eth1_Eth_v52_XCP_Request_From_TT8_To_EBCM_ETH_InVehicle_Identifier: pdu-triggering=EBCM_ETH_Eth1_Eth_v52_XCP_Request_From_TT8_To_EBCM_ETH_InVehicle
        EBCM_ETH_Eth1_Eth_v52_XCP_Response_From_EBCM_ETH_To_TT3_InVehicle_Identifier: pdu-triggering=EBCM_ETH_Eth1_Eth_v52_XCP_Response_From_EBCM_ETH_To_TT3_InVehicle
        EBCM_ETH_Eth1_Eth_v52_XCP_Response_From_EBCM_ETH_To_TT8_InVehicle_Identifier: pdu-triggering=EBCM_ETH_Eth1_Eth_v52_XCP_Response_From_EBCM_ETH_To_TT8_InVehicle
        EBCM_ETH_Eth1_Eth_v52_PDU_SYS_ARPLearning_Identifier: header-id=4294737921, pdu-collection-semantics=QUEUED, pdu-triggering=SPDU_SYS_ARPLearning
  4 x someip sd client event group timing config, all with request-response-delay={max-value=0.0, min-value=0.0}, subscribe-eventgroup-retry-delay=0.05, time-to-live=3:
    SDClientEvtGrpTimCfg_DummyService_DO_NOT_ENABLE_Eth_v22_50000
    SDClientEvtGrpTimCfg_DummyService_DO_NOT_ENABLE_Eth_v23_50000
    SDClientEvtGrpTimCfg_hcSVC_CnsldtnEBST_evt_8001
    SDClientEvtGrpTimCfg_hcSVC_CnsldtnSecEBST_evt_8001
  7 x someip sd client service instance config, all with initial-find-behavior={initial-delay-max-value=0.01, initial-delay-min-value=0.01, initial-repetitions-base-delay=0.03, initial-repetitions-max=3}, service-find-time-to-live=3:
    SDClientSvcInstCfg_Act_amSVC_ActvnMngrBrakes_itsEBCM_ETH_Eth_v23_0E8F
    SDClientSvcInstCfg_Act_amSVC_ActvnMngrVehStBkup_itsEBCM_ETH_Eth_v23_0E9C
    SDClientSvcInstCfg_Act_amSVC_ActvnMngrVehSt_itsEBCM_ETH_Eth_v23_0E9B
    SDClientSvcInstCfg_DummyService_DO_NOT_ENABLE_Eth_v22_50000
    SDClientSvcInstCfg_DummyService_DO_NOT_ENABLE_Eth_v23_50000
    SDClientSvcInstCfg_hcSVC_CnsldtnEBST_0CD6_EBCM_ETH_Eth_v22
    SDClientSvcInstCfg_hcSVC_CnsldtnSecEBST_0D8B_EBCM_ETH_Eth_v23
  someip sd server event group timing config SDServerEvtGrpTimCfg_hSVC_eBstActrPri_evt_8001: request-response-delay={max-value=0.0, min-value=0.0}
  someip sd server event group timing config SDServerEvtGrpTimCfg_hSVC_eBstActrSec_evt_8001: request-response-delay={max-value=0.0, min-value=0.0}
  6 x someip sd server service instance config, all with initial-offer-behavior={initial-delay-max-value=0.03, initial-delay-min-value=0.02, initial-repetitions-base-delay=0.03, initial-repetitions-max=3}, offer-cyclic-delay=1.0, request-response-delay={max-value=0.0, min-value=0.0}, service-offer-time-to-live=3:
    SDServerSvcInstCfg_Act_hSVC_GEN_INF_EBCM_EBCM_ETH_Eth_v22_1058
    SDServerSvcInstCfg_Act_hSVC_GEN_INF_EBCM_EBCM_ETH_Eth_v23_1058
    SDServerSvcInstCfg_Act_hSVC_eBstActrPri_EBCM_ETH_Eth_v23_0C5B
    SDServerSvcInstCfg_Act_hSVC_eBstActrSec_EBCM_ETH_Eth_v22_0C5C
    SDServerSvcInstCfg_hSVC_eBstActrPri_0C5B_MechatronicsT1S_EBCM_ETH_Eth_v22
    SDServerSvcInstCfg_hSVC_eBstActrSec_0C5C_MechatronicsT1S_Eth2_EBCM_ETH_Eth_v23
package /Topologies/SDV/Ethernet_1/v1111
  i signal i pdu group PwrMgrMulti_PwrMgrHeartbeatRx_FFFE_EBCM_ETH_IN: communication-direction=IN, i-signal-i-pdus=PDU_SYS_PMMulticastRxPwrMgrMulti_Heartbeat
  i signal i pdu group PwrMgrMulti_PwrMgrWakeupRx_FFFE_EBCM_ETH_IN: communication-direction=IN, i-signal-i-pdus=PDU_SYS_PMMulticastRxPwrMgrMulti_Wakeup
package /Topologies/SDV/Ethernet_1/v121
  pdu PDU_SYS_SMUnicastRxMechatronics_Eth2_Info: length=1398, transmission-mode-condition{data-filter=data-filter-type=ALWAYS, i-signal-in-i-pdu=PDU_SYS_SMUnicastRxMechatronics_Eth2_Info_EBCM_ETH_Eth_v21_ISigToIPduMap}, transmission-mode-true-timing=event-controlled-timing=number-of-repetitions=0, unused-bit-pattern=0
    signal Mechatronics_Eth2_SwMgrInfoRx_Evt_EBCM_ETH_1_v21_ISignal: start 0, 11184 bit, opaque, system signal Mechatronics_Eth2_SwMgrInfoRx_Evt_SystemSignal, data-transformations=SPM_SOMEIP_Data_Transformation, data-type-policy=TRANSFORMING-I-SIGNAL, i-signal-type=ARRAY, someip-transformation-i-signal-props{cs-error-reaction=AUTONOMOUS, transformer=SPM_SOMEIP_Transformer, message-type=NOTIFICATION, session-handling-sr=SESSION-HANDLING-INACTIVE}, dynamic-length=true, transfer-property=TRIGGERED-ON-CHANGE, to EBCM_ETH(timeout 2.5 s)
  pdu PDU_SYS_SMUnicastTxMechatronics_Eth2_Info: length=1398, transmission-mode-condition{data-filter=data-filter-type=ALWAYS, i-signal-in-i-pdu=PDU_SYS_SMUnicastTxMechatronics_Eth2_Info_EBCM_ETH_Eth_v21_ISigToIPduMap}, transmission-mode-true-timing=event-controlled-timing=number-of-repetitions=0, unused-bit-pattern=0
    signal Mechatronics_Eth2_SwMgrInfoTx_Evt_EBCM_ETH_1_v21_ISignal: start 0, 11184 bit, opaque, system signal Mechatronics_Eth2_SwMgrInfoTx_Evt_SystemSignal, data-transformations=SPM_SOMEIP_Data_Transformation, data-type-policy=TRANSFORMING-I-SIGNAL, i-signal-type=ARRAY, someip-transformation-i-signal-props{cs-error-reaction=AUTONOMOUS, transformer=SPM_SOMEIP_Transformer, message-type=NOTIFICATION, session-handling-sr=SESSION-HANDLING-INACTIVE}, dynamic-length=true, transfer-property=TRIGGERED-ON-CHANGE
  i signal i pdu group Mechatronics_Eth2_SwMgrInfoRx_FFFD_EBCM_ETH_IN: communication-direction=IN, i-signal-i-pdus=PDU_SYS_SMUnicastRxMechatronics_Eth2_Info
  i signal i pdu group Mechatronics_Eth2_SwMgrInfoTx_FFFD_EBCM_ETH_OUT: communication-direction=OUT, i-signal-i-pdus=PDU_SYS_SMUnicastTxMechatronics_Eth2_Info
  secured i pdu SPDU_SYS_SMUnicastRxMechatronics_Eth2_Info: length=1424, authentication-props=AuthenticationConfiguration_GMSecOCProfile1, freshness-props=FreshnessConfiguration_GMSecOCProfile1, payload=PDU_SYS_SMUnicastRxMechatronics_Eth2_Info, secure-communication-props={authentication-build-attempts=2, authentication-retries=1, data-id=60874, freshness-value-id=0}, use-as-cryptographic-i-pdu=false, use-secured-pdu-header=NO-HEADER
  secured i pdu SPDU_SYS_SMUnicastTxMechatronics_Eth2_Info: length=1424, authentication-props=AuthenticationConfiguration_GMSecOCProfile1, freshness-props=FreshnessConfiguration_GMSecOCProfile1, payload=PDU_SYS_SMUnicastTxMechatronics_Eth2_Info, secure-communication-props={authentication-build-attempts=2, authentication-retries=1, data-id=78819, freshness-value-id=0}, use-as-cryptographic-i-pdu=false, use-secured-pdu-header=NO-HEADER
package /Topologies/SDV/Ethernet_1/v122
  pdu PDU_HC_0CD68001: length=505, transmission-mode-condition{data-filter=data-filter-type=ALWAYS, i-signal-in-i-pdu=PDU_HC_0CD68001_EBCM_ETH_Eth_v22_ISigToIPduMap}, transmission-mode-true-timing=cyclic-timing=time-period=0.005, unused-bit-pattern=0
    signal hcSVC_CnsldtnEBST_evt_EBCM_ETH_1_v22_ISignal: start 0, 4040 bit, opaque, system signal hcSVC_CnsldtnEBST_evt_SystemSignal, data-transformations=SOMEIP_Data_Transform_wE2E_PROFILE_GM_05, data-type-policy=TRANSFORMING-I-SIGNAL, i-signal-type=ARRAY, transfer-property=PENDING, to EBCM_ETH(timeout 0.015 s)
  pdu PDU_H_0C5B8001: length=409, transmission-mode-condition{data-filter=data-filter-type=ALWAYS, i-signal-in-i-pdu=PDU_H_0C5B8001_EBCM_ETH_Eth_v22_ISigToIPduMap}, transmission-mode-true-timing=cyclic-timing=time-period=0.0025, unused-bit-pattern=0
    signal hSVC_eBstActrPri_evt_EBCM_ETH_1_v22_ISignal: start 0, 3272 bit, opaque, system signal hSVC_eBstActrPri_evt_SystemSignal, data-transformations=SOMEIP_Data_Transform_wE2E_PROFILE_GM_05, data-type-policy=TRANSFORMING-I-SIGNAL, i-signal-type=ARRAY, transfer-property=PENDING
  pdu PDU_SYS_PMUnicastTxMechatronicsT1S_Wakeup: length=36, transmission-mode-condition{data-filter=data-filter-type=ALWAYS, i-signal-in-i-pdu=PDU_SYS_PMUnicastTxMechatronicsT1S_Wakeup_EBCM_ETH_Eth_v22_ISigToIPduMap}, transmission-mode-true-timing=event-controlled-timing=number-of-repetitions=0, unused-bit-pattern=0
    signal MechatronicsT1S_PwrMgrWakeupTx_Evt_EBCM_ETH_1_v22_ISignal: start 0, 288 bit, opaque, system signal MechatronicsT1S_PwrMgrWakeupTx_Evt_SystemSignal, data-transformations=SPM_SOMEIP_Data_Transformation, data-type-policy=TRANSFORMING-I-SIGNAL, i-signal-type=ARRAY, someip-transformation-i-signal-props{cs-error-reaction=AUTONOMOUS, transformer=SPM_SOMEIP_Transformer, message-type=NOTIFICATION, session-handling-sr=SESSION-HANDLING-INACTIVE}, transfer-property=TRIGGERED-ON-CHANGE
  pdu PDU_SYS_SMUnicastRxMechatronicsT1S_Info: length=1398, transmission-mode-condition{data-filter=data-filter-type=ALWAYS, i-signal-in-i-pdu=PDU_SYS_SMUnicastRxMechatronicsT1S_Info_EBCM_ETH_Eth_v22_ISigToIPduMap}, transmission-mode-true-timing=event-controlled-timing=number-of-repetitions=0, unused-bit-pattern=0
    signal MechatronicsT1S_SwMgrInfoRx_Evt_EBCM_ETH_1_v22_ISignal: start 0, 11184 bit, opaque, system signal MechatronicsT1S_SwMgrInfoRx_Evt_SystemSignal, data-transformations=SPM_SOMEIP_Data_Transformation, data-type-policy=TRANSFORMING-I-SIGNAL, i-signal-type=ARRAY, someip-transformation-i-signal-props{cs-error-reaction=AUTONOMOUS, transformer=SPM_SOMEIP_Transformer, message-type=NOTIFICATION, session-handling-sr=SESSION-HANDLING-INACTIVE}, dynamic-length=true, transfer-property=TRIGGERED-ON-CHANGE, to EBCM_ETH(timeout 2.5 s)
  pdu PDU_SYS_SMUnicastTxMechatronicsT1S_Info: length=1398, transmission-mode-condition{data-filter=data-filter-type=ALWAYS, i-signal-in-i-pdu=PDU_SYS_SMUnicastTxMechatronicsT1S_Info_EBCM_ETH_Eth_v22_ISigToIPduMap}, transmission-mode-true-timing=event-controlled-timing=number-of-repetitions=0, unused-bit-pattern=0
    signal MechatronicsT1S_SwMgrInfoTx_Evt_EBCM_ETH_1_v22_ISignal: start 0, 11184 bit, opaque, system signal MechatronicsT1S_SwMgrInfoTx_Evt_SystemSignal, data-transformations=SPM_SOMEIP_Data_Transformation, data-type-policy=TRANSFORMING-I-SIGNAL, i-signal-type=ARRAY, someip-transformation-i-signal-props{cs-error-reaction=AUTONOMOUS, transformer=SPM_SOMEIP_Transformer, message-type=NOTIFICATION, session-handling-sr=SESSION-HANDLING-INACTIVE}, dynamic-length=true, transfer-property=TRIGGERED-ON-CHANGE
  6 x i signal i pdu group:
    MechatronicsT1S_PwrMgrHeartbeatTx_FFFE_EBCM_ETH_OUT: communication-direction=OUT, i-signal-i-pdus=PDU_SYS_PMMulticastTxMechatronicsT1S_Heartbeat
    MechatronicsT1S_PwrMgrWakeupTx_FFFE_EBCM_ETH_OUT: communication-direction=OUT, i-signal-i-pdus=PDU_SYS_PMUnicastTxMechatronicsT1S_Wakeup
    MechatronicsT1S_SwMgrInfoRx_FFFD_EBCM_ETH_IN: communication-direction=IN, i-signal-i-pdus=PDU_SYS_SMUnicastRxMechatronicsT1S_Info
    MechatronicsT1S_SwMgrInfoTx_FFFD_EBCM_ETH_OUT: communication-direction=OUT, i-signal-i-pdus=PDU_SYS_SMUnicastTxMechatronicsT1S_Info
    hSVC_eBstActrPri_0C5B_EBCM_ETH_OUT: communication-direction=OUT, i-signal-i-pdus=PDU_H_0C5B8001
    hcSVC_CnsldtnEBST_0CD6_EBCM_ETH_IN: communication-direction=IN, i-signal-i-pdus=PDU_HC_0CD68001
  secured i pdu SPDU_HC_0CD68001: length=531, authentication-props=AuthenticationConfiguration_GMSecOCProfile1, freshness-props=FreshnessConfiguration_GMSecOCProfile1, payload=PDU_HC_0CD68001_Rx, secure-communication-props={authentication-build-attempts=2, authentication-retries=1, data-id=25257, freshness-value-id=0}, use-as-cryptographic-i-pdu=false, use-secured-pdu-header=NO-HEADER
  secured i pdu SPDU_H_0C5B8001: length=435, authentication-props=AuthenticationConfiguration_GMSecOCProfile1, freshness-props=FreshnessConfiguration_GMSecOCProfile1, payload=PDU_H_0C5B8001_Tx, secure-communication-props={authentication-build-attempts=2, authentication-retries=1, data-id=29269, freshness-value-id=0}, use-as-cryptographic-i-pdu=false, use-secured-pdu-header=NO-HEADER
  secured i pdu SPDU_SYS_PMMulticastTxMechatronicsT1S_Heartbeat: length=44, authentication-props=AuthenticationConfiguration_GMSecOCProfile1, freshness-props=FreshnessConfiguration_GMSecOCProfile1, payload=PDU_SYS_PMMulticastTxMechatronicsT1S_Heartbeat, secure-communication-props={authentication-build-attempts=2, authentication-retries=1, data-id=56977, freshness-value-id=0}, use-as-cryptographic-i-pdu=false, use-secured-pdu-header=NO-HEADER
  secured i pdu SPDU_SYS_SMUnicastRxMechatronicsT1S_Info: length=1424, authentication-props=AuthenticationConfiguration_GMSecOCProfile1, freshness-props=FreshnessConfiguration_GMSecOCProfile1, payload=PDU_SYS_SMUnicastRxMechatronicsT1S_Info, secure-communication-props={authentication-build-attempts=2, authentication-retries=1, data-id=35925, freshness-value-id=0}, use-as-cryptographic-i-pdu=false, use-secured-pdu-header=NO-HEADER
  secured i pdu SPDU_SYS_SMUnicastTxMechatronicsT1S_Info: length=1424, authentication-props=AuthenticationConfiguration_GMSecOCProfile1, freshness-props=FreshnessConfiguration_GMSecOCProfile1, payload=PDU_SYS_SMUnicastTxMechatronicsT1S_Info, secure-communication-props={authentication-build-attempts=2, authentication-retries=1, data-id=17990, freshness-value-id=0}, use-as-cryptographic-i-pdu=false, use-secured-pdu-header=NO-HEADER
package /Topologies/SDV/Ethernet_1/v152
  pdu PDU_SYS_ARPLearning: length=10, transmission-mode-condition{data-filter=data-filter-type=ALWAYS, i-signal-in-i-pdu=PDU_SYS_ARPLearning_EBCM_ETH_Eth_v52_ISigToIPduMap}, transmission-mode-true-timing=cyclic-timing=time-period=0.5, unused-bit-pattern=0
    signal ARPLearning_Evt_EBCM_ETH_1_v52_ISignal: start 0, 80 bit, opaque, system signal ARPLearning_Evt_SystemSignal, data-transformations=SOMEIP_Data_Transform_wE2E_PROFILE_GM_01, data-type-policy=TRANSFORMING-I-SIGNAL, i-signal-type=ARRAY, transfer-property=PENDING, to EBCM_ETH(timeout 1.25 s)
  i signal i pdu group ARPLearning_FFFC_EBCM_ETH_IN: communication-direction=IN, i-signal-i-pdus=PDU_SYS_ARPLearning
  secured i pdu SPDU_SYS_ARPLearning: length=34, authentication-props=AuthenticationConfiguration_GMSecOCProfile1, freshness-props=FreshnessConfiguration_GMSecOCProfile1, payload=PDU_SYS_ARPLearning, secure-communication-props={authentication-build-attempts=2, authentication-retries=1, data-id=66864, freshness-value-id=0}, use-as-cryptographic-i-pdu=false, use-secured-pdu-header=NO-HEADER
package /Topologies/SDV/Ethernet_1/v2111
  secured i pdu SPDU_SYS_PMMulticastRxPwrMgrMulti_Heartbeat: length=44, authentication-props=AuthenticationConfiguration_GMSecOCProfile1, freshness-props=FreshnessConfiguration_GMSecOCProfile1, payload=PDU_SYS_PMMulticastRxPwrMgrMulti_Heartbeat, secure-communication-props={authentication-build-attempts=2, authentication-retries=1, data-id=44785, freshness-value-id=0}, use-as-cryptographic-i-pdu=false, use-secured-pdu-header=NO-HEADER
package /Topologies/SDV/Ethernet_1/v22
  general purpose pdu GPDU_EBCM_ETH_Eth1_Eth_v22_SDMulticastRx: category=SD, has-dynamic-length=true, length=1414
  general purpose pdu GPDU_EBCM_ETH_Eth1_Eth_v22_SDUnicastRx: category=SD, has-dynamic-length=true, length=1414
  general purpose pdu GPDU_EBCM_ETH_Eth1_Eth_v22_SDUnicastTx: category=SD, has-dynamic-length=true, length=1414
  pdu DummyPDU_DO_NOT_ENABLE_Eth_v22_50000: length=12, transmission-mode-condition{data-filter=data-filter-type=ALWAYS, i-signal-in-i-pdu=DummyPDU_DO_NOT_ENABLE_Eth_v22_ISigToIPduMap}, transmission-mode-true-timing=event-controlled-timing={number-of-repetitions=0, repetition-period=0.0}, unused-bit-pattern=0
    signal DummyService_DO_NOT_ENABLE_EBCM_ETH_1_Eth_v22_ISignal_50000: start 0, 8 bit, opaque, system signal DummyEvent_DO_NOT_ENABLE_Eth_v22_50000_SystemSignal, data-transformations=SOMEIP_Data_Transform_wE2E_PROFILE_GM_01, data-type-policy=TRANSFORMING-I-SIGNAL, i-signal-type=PRIMITIVE, transfer-property=PENDING, to EBCM_ETH
  pdur i pdu group Ethernet_1_itsEBCM_ETH_Ethernet_1_connector1_v22_PdurIPduGroup_SD: communication-mode=SDControl
    i-pdus:
      EBCM_ETH_Eth1_Eth_v22_SDUnicastRx
      EBCM_ETH_Eth1_Eth_v22_SDUnicastTx
      EBCM_ETH_Eth1_Eth_v22_SDMulticastRx
  secured i pdu SPDU_EBCM_ETH_Eth1_Eth_v22_SDMulticastRx: category=SD, has-dynamic-length=true, length=1440, authentication-props=AuthenticationConfiguration_GMSecOCProfile1, freshness-props=FreshnessConfiguration_GMSecOCProfile1, payload=EBCM_ETH_Eth1_Eth_v22_SDMulticastRx, secure-communication-props={authentication-build-attempts=2, authentication-retries=1, data-id=4294967169, freshness-value-id=0}, use-as-cryptographic-i-pdu=false, use-secured-pdu-header=NO-HEADER
  secured i pdu SPDU_EBCM_ETH_Eth1_Eth_v22_SDUnicastRx: category=SD, has-dynamic-length=true, length=1440, authentication-props=AuthenticationConfiguration_GMSecOCProfile1, freshness-props=FreshnessConfiguration_GMSecOCProfile1, payload=EBCM_ETH_Eth1_Eth_v22_SDUnicastRx, secure-communication-props={authentication-build-attempts=2, authentication-retries=1, data-id=4294967169, freshness-value-id=0}, use-as-cryptographic-i-pdu=false, use-secured-pdu-header=NO-HEADER
  secured i pdu SPDU_EBCM_ETH_Eth1_Eth_v22_SDUnicastTx: category=SD, has-dynamic-length=true, length=1440, authentication-props=AuthenticationConfiguration_GMSecOCProfile1, freshness-props=FreshnessConfiguration_GMSecOCProfile1, payload=EBCM_ETH_Eth1_Eth_v22_SDUnicastTx, secure-communication-props={authentication-build-attempts=2, authentication-retries=1, data-id=4294967169, freshness-value-id=0}, use-as-cryptographic-i-pdu=false, use-secured-pdu-header=NO-HEADER
  service instance collection set EBCM_ETH_Ethernet_1_connector1_Eth_v22_SvcInstanceCollectionSet
    consumed service instance hcSVC_CnsldtnEBST_0CD6_EBCM_ETH_Eth_v22_CSI: major-version=1, instance-identifier=1, local-unicast-addresss=EBCM_ETH_Eth1_Eth_v22_50003_AEP, minor-version=4294967295, sd-client-timer-configs=SDClientSvcInstCfg_hcSVC_CnsldtnEBST_0CD6_EBCM_ETH_Eth_v22, service-identifier=3286, version-driven-find-behavior=EXACT-OR-ANY-MINOR-VERSION
      consumed event group CEG_EvntGrp_hcSVC_CnsldtnEBST_evt_8001: auto-require=true, event-group-identifier=32769, priority=0, sd-client-timer-configs=SDClientEvtGrpTimCfg_hcSVC_CnsldtnEBST_evt_8001
        pdu activation routing group SoAdARg_EvntGrp_hcSVC_CnsldtnEBST_evt_8001: event-group-control-type=ACTIVATION-UNICAST, i-pdu-identifier-udp=HC_0CD68001_MechatronicsT1S_EBCM_ETH_Identifier
    consumed service instance DummyService_DO_NOT_ENABLE_Eth_v22_50000_C: major-version=1, instance-identifier=1, local-unicast-addresss=EBCM_ETH_Eth1_Eth_v22_50000_AEP, minor-version=4294967295, sd-client-timer-configs=SDClientSvcInstCfg_DummyService_DO_NOT_ENABLE_Eth_v22_50000, service-identifier=65520, version-driven-find-behavior=EXACT-OR-ANY-MINOR-VERSION
      consumed event group CEG_EvntGrp_DummyService_DO_NOT_ENABLE_Eth_v22_50000: auto-require=false, event-group-identifier=1, priority=0, sd-client-timer-configs=SDClientEvtGrpTimCfg_DummyService_DO_NOT_ENABLE_Eth_v22_50000
        pdu activation routing group SoAdARg_EvntGrp_DummyService_DO_NOT_ENABLE_Eth_v22_50000: event-group-control-type=ACTIVATION-UNICAST, i-pdu-identifier-udp=DummyService_DO_NOT_ENABLE_Eth_v22_50000_Identifier
    provided service instance hSVC_eBstActrPri_0C5B_MechatronicsT1S_EBCM_ETH_Eth_v22_PSI: major-version=1, instance-identifier=1, local-unicast-addresss=EBCM_ETH_Eth1_Eth_v22_50003_AEP, minor-version=0, sd-server-timer-configs=SDServerSvcInstCfg_hSVC_eBstActrPri_0C5B_MechatronicsT1S_EBCM_ETH_Eth_v22, service-identifier=3163
      event handler EH_EvntGrp_hSVC_eBstActrPri_evt_8001: event-group-identifier=32769, sd-server-eg-timing-configs=SDServerEvtGrpTimCfg_hSVC_eBstActrPri_evt_8001
        pdu activation routing group SoAdARg_EvntGrp_hSVC_eBstActrPri_evt_8001: event-group-control-type=ACTIVATION-UNICAST, i-pdu-identifier-udp=H_0C5B8001_MechatronicsT1S_EBCM_ETH_Identifier
    provided service instance Act_hSVC_GEN_INF_EBCM_EBCM_ETH_Eth_v22_1058_P: major-version=1, instance-identifier=1, local-unicast-addresss=EBCM_ETH_Eth1_Eth_v22_50000_AEP, minor-version=0, sd-server-timer-configs=SDServerSvcInstCfg_Act_hSVC_GEN_INF_EBCM_EBCM_ETH_Eth_v22_1058, service-identifier=4184
    provided service instance Act_hSVC_eBstActrSec_EBCM_ETH_Eth_v22_0C5C_P: major-version=1, instance-identifier=1, local-unicast-addresss=EBCM_ETH_Eth1_Eth_v22_50003_AEP, minor-version=0, sd-server-timer-configs=SDServerSvcInstCfg_Act_hSVC_eBstActrSec_EBCM_ETH_Eth_v22_0C5C, service-identifier=3164
package /Topologies/SDV/Ethernet_1/v223
  pdu PDU_HC_0D8B8001: length=505, transmission-mode-condition{data-filter=data-filter-type=ALWAYS, i-signal-in-i-pdu=PDU_HC_0D8B8001_EBCM_ETH_Eth_v23_ISigToIPduMap}, transmission-mode-true-timing=cyclic-timing=time-period=0.005, unused-bit-pattern=0
    signal hcSVC_CnsldtnSecEBST_evt_EBCM_ETH_2_v23_ISignal: start 0, 4040 bit, opaque, system signal hcSVC_CnsldtnSecEBST_evt_SystemSignal, data-transformations=SOMEIP_Data_Transform_wE2E_PROFILE_GM_05, data-type-policy=TRANSFORMING-I-SIGNAL, i-signal-type=ARRAY, transfer-property=PENDING, to EBCM_ETH(timeout 0.015 s)
  pdu PDU_H_0C5C8001: length=409, transmission-mode-condition{data-filter=data-filter-type=ALWAYS, i-signal-in-i-pdu=PDU_H_0C5C8001_EBCM_ETH_Eth_v23_ISigToIPduMap}, transmission-mode-true-timing=cyclic-timing=time-period=0.0025, unused-bit-pattern=0
    signal hSVC_eBstActrSec_evt_EBCM_ETH_2_v23_ISignal: start 0, 3272 bit, opaque, system signal hSVC_eBstActrSec_evt_SystemSignal, data-transformations=SOMEIP_Data_Transform_wE2E_PROFILE_GM_05, data-type-policy=TRANSFORMING-I-SIGNAL, i-signal-type=ARRAY, transfer-property=PENDING
  pdu PDU_SYS_PMUnicastTxMechatronicsT1S_Eth2_Wakeup: length=36, transmission-mode-condition{data-filter=data-filter-type=ALWAYS, i-signal-in-i-pdu=PDU_SYS_PMUnicastTxMechatronicsT1S_Eth2_Wakeup_EBCM_ETH_Eth_v23_ISigToIPduMap}, transmission-mode-true-timing=event-controlled-timing=number-of-repetitions=0, unused-bit-pattern=0
    signal MechatronicsT1S_Eth2_PwrMgrWakeupTx_Evt_EBCM_ETH_2_v23_ISignal: start 0, 288 bit, opaque, system signal MechatronicsT1S_Eth2_PwrMgrWakeupTx_Evt_SystemSignal, data-transformations=SPM_SOMEIP_Data_Transformation, data-type-policy=TRANSFORMING-I-SIGNAL, i-signal-type=ARRAY, someip-transformation-i-signal-props{cs-error-reaction=AUTONOMOUS, transformer=SPM_SOMEIP_Transformer, message-type=NOTIFICATION, session-handling-sr=SESSION-HANDLING-INACTIVE}, transfer-property=TRIGGERED-ON-CHANGE
  pdu PDU_SYS_SMUnicastRxMechatronicsT1S_Eth2_Info: length=1398, transmission-mode-condition{data-filter=data-filter-type=ALWAYS, i-signal-in-i-pdu=PDU_SYS_SMUnicastRxMechatronicsT1S_Eth2_Info_EBCM_ETH_Eth_v23_ISigToIPduMap}, transmission-mode-true-timing=event-controlled-timing=number-of-repetitions=0, unused-bit-pattern=0
    signal MechatronicsT1S_Eth2_SwMgrInfoRx_Evt_EBCM_ETH_2_v23_ISignal: start 0, 11184 bit, opaque, system signal MechatronicsT1S_Eth2_SwMgrInfoRx_Evt_SystemSignal, data-transformations=SPM_SOMEIP_Data_Transformation, data-type-policy=TRANSFORMING-I-SIGNAL, i-signal-type=ARRAY, someip-transformation-i-signal-props{cs-error-reaction=AUTONOMOUS, transformer=SPM_SOMEIP_Transformer, message-type=NOTIFICATION, session-handling-sr=SESSION-HANDLING-INACTIVE}, dynamic-length=true, transfer-property=TRIGGERED-ON-CHANGE, to EBCM_ETH(timeout 2.5 s)
  pdu PDU_SYS_SMUnicastTxMechatronicsT1S_Eth2_Info: length=1398, transmission-mode-condition{data-filter=data-filter-type=ALWAYS, i-signal-in-i-pdu=PDU_SYS_SMUnicastTxMechatronicsT1S_Eth2_Info_EBCM_ETH_Eth_v23_ISigToIPduMap}, transmission-mode-true-timing=event-controlled-timing=number-of-repetitions=0, unused-bit-pattern=0
    signal MechatronicsT1S_Eth2_SwMgrInfoTx_Evt_EBCM_ETH_2_v23_ISignal: start 0, 11184 bit, opaque, system signal MechatronicsT1S_Eth2_SwMgrInfoTx_Evt_SystemSignal, data-transformations=SPM_SOMEIP_Data_Transformation, data-type-policy=TRANSFORMING-I-SIGNAL, i-signal-type=ARRAY, someip-transformation-i-signal-props{cs-error-reaction=AUTONOMOUS, transformer=SPM_SOMEIP_Transformer, message-type=NOTIFICATION, session-handling-sr=SESSION-HANDLING-INACTIVE}, dynamic-length=true, transfer-property=TRIGGERED-ON-CHANGE
  6 x i signal i pdu group:
    MechatronicsT1S_Eth2_PwrMgrHeartbeatTx_FFFE_EBCM_ETH_OUT: communication-direction=OUT, i-signal-i-pdus=PDU_SYS_PMMulticastTxMechatronicsT1S_Eth2_Heartbeat
    MechatronicsT1S_Eth2_PwrMgrWakeupTx_FFFE_EBCM_ETH_OUT: communication-direction=OUT, i-signal-i-pdus=PDU_SYS_PMUnicastTxMechatronicsT1S_Eth2_Wakeup
    MechatronicsT1S_Eth2_SwMgrInfoRx_FFFD_EBCM_ETH_IN: communication-direction=IN, i-signal-i-pdus=PDU_SYS_SMUnicastRxMechatronicsT1S_Eth2_Info
    MechatronicsT1S_Eth2_SwMgrInfoTx_FFFD_EBCM_ETH_OUT: communication-direction=OUT, i-signal-i-pdus=PDU_SYS_SMUnicastTxMechatronicsT1S_Eth2_Info
    hSVC_eBstActrSec_0C5C_EBCM_ETH_OUT: communication-direction=OUT, i-signal-i-pdus=PDU_H_0C5C8001
    hcSVC_CnsldtnSecEBST_0D8B_EBCM_ETH_IN: communication-direction=IN, i-signal-i-pdus=PDU_HC_0D8B8001
  secured i pdu SPDU_HC_0D8B8001: length=531, authentication-props=AuthenticationConfiguration_GMSecOCProfile1, freshness-props=FreshnessConfiguration_GMSecOCProfile1, payload=PDU_HC_0D8B8001_Rx, secure-communication-props={authentication-build-attempts=2, authentication-retries=1, data-id=68606, freshness-value-id=0}, use-as-cryptographic-i-pdu=false, use-secured-pdu-header=NO-HEADER
  secured i pdu SPDU_H_0C5C8001: length=435, authentication-props=AuthenticationConfiguration_GMSecOCProfile1, freshness-props=FreshnessConfiguration_GMSecOCProfile1, payload=PDU_H_0C5C8001_Tx, secure-communication-props={authentication-build-attempts=2, authentication-retries=1, data-id=22683, freshness-value-id=0}, use-as-cryptographic-i-pdu=false, use-secured-pdu-header=NO-HEADER
  secured i pdu SPDU_SYS_PMMulticastTxMechatronicsT1S_Eth2_Heartbeat: length=44, authentication-props=AuthenticationConfiguration_GMSecOCProfile1, freshness-props=FreshnessConfiguration_GMSecOCProfile1, payload=PDU_SYS_PMMulticastTxMechatronicsT1S_Eth2_Heartbeat, secure-communication-props={authentication-build-attempts=2, authentication-retries=1, data-id=5176, freshness-value-id=0}, use-as-cryptographic-i-pdu=false, use-secured-pdu-header=NO-HEADER
  secured i pdu SPDU_SYS_SMUnicastRxMechatronicsT1S_Eth2_Info: length=1424, authentication-props=AuthenticationConfiguration_GMSecOCProfile1, freshness-props=FreshnessConfiguration_GMSecOCProfile1, payload=PDU_SYS_SMUnicastRxMechatronicsT1S_Eth2_Info, secure-communication-props={authentication-build-attempts=2, authentication-retries=1, data-id=86254, freshness-value-id=0}, use-as-cryptographic-i-pdu=false, use-secured-pdu-header=NO-HEADER
  secured i pdu SPDU_SYS_SMUnicastTxMechatronicsT1S_Eth2_Info: length=1424, authentication-props=AuthenticationConfiguration_GMSecOCProfile1, freshness-props=FreshnessConfiguration_GMSecOCProfile1, payload=PDU_SYS_SMUnicastTxMechatronicsT1S_Eth2_Info, secure-communication-props={authentication-build-attempts=2, authentication-retries=1, data-id=40927, freshness-value-id=0}, use-as-cryptographic-i-pdu=false, use-secured-pdu-header=NO-HEADER
package /Topologies/SDV/Ethernet_1/v23
  general purpose pdu GPDU_EBCM_ETH_Eth2_Eth_v23_SDMulticastRx: category=SD, has-dynamic-length=true, length=1414
  general purpose pdu GPDU_EBCM_ETH_Eth2_Eth_v23_SDUnicastRx: category=SD, has-dynamic-length=true, length=1414
  general purpose pdu GPDU_EBCM_ETH_Eth2_Eth_v23_SDUnicastTx: category=SD, has-dynamic-length=true, length=1414
  pdu DummyPDU_DO_NOT_ENABLE_Eth_v23_50000: length=12, transmission-mode-condition{data-filter=data-filter-type=ALWAYS, i-signal-in-i-pdu=DummyPDU_DO_NOT_ENABLE_Eth_v23_ISigToIPduMap}, transmission-mode-true-timing=event-controlled-timing={number-of-repetitions=0, repetition-period=0.0}, unused-bit-pattern=0
    signal DummyService_DO_NOT_ENABLE_EBCM_ETH_2_Eth_v23_ISignal_50000: start 0, 8 bit, opaque, system signal DummyEvent_DO_NOT_ENABLE_Eth_v23_50000_SystemSignal, data-transformations=SOMEIP_Data_Transform_wE2E_PROFILE_GM_01, data-type-policy=TRANSFORMING-I-SIGNAL, i-signal-type=PRIMITIVE, transfer-property=PENDING, to EBCM_ETH
  pdur i pdu group Ethernet_1_itsEBCM_ETH_Ethernet_1_connector2_v23_PdurIPduGroup_SD: communication-mode=SDControl
    i-pdus:
      EBCM_ETH_Eth2_Eth_v23_SDUnicastRx
      EBCM_ETH_Eth2_Eth_v23_SDUnicastTx
      EBCM_ETH_Eth2_Eth_v23_SDMulticastRx
  secured i pdu SPDU_EBCM_ETH_Eth2_Eth_v23_SDMulticastRx: category=SD, has-dynamic-length=true, length=1440, authentication-props=AuthenticationConfiguration_GMSecOCProfile1, freshness-props=FreshnessConfiguration_GMSecOCProfile1, payload=EBCM_ETH_Eth2_Eth_v23_SDMulticastRx, secure-communication-props={authentication-build-attempts=2, authentication-retries=1, data-id=4294967169, freshness-value-id=0}, use-as-cryptographic-i-pdu=false, use-secured-pdu-header=NO-HEADER
  secured i pdu SPDU_EBCM_ETH_Eth2_Eth_v23_SDUnicastRx: category=SD, has-dynamic-length=true, length=1440, authentication-props=AuthenticationConfiguration_GMSecOCProfile1, freshness-props=FreshnessConfiguration_GMSecOCProfile1, payload=EBCM_ETH_Eth2_Eth_v23_SDUnicastRx, secure-communication-props={authentication-build-attempts=2, authentication-retries=1, data-id=4294967169, freshness-value-id=0}, use-as-cryptographic-i-pdu=false, use-secured-pdu-header=NO-HEADER
  secured i pdu SPDU_EBCM_ETH_Eth2_Eth_v23_SDUnicastTx: category=SD, has-dynamic-length=true, length=1440, authentication-props=AuthenticationConfiguration_GMSecOCProfile1, freshness-props=FreshnessConfiguration_GMSecOCProfile1, payload=EBCM_ETH_Eth2_Eth_v23_SDUnicastTx, secure-communication-props={authentication-build-attempts=2, authentication-retries=1, data-id=4294967169, freshness-value-id=0}, use-as-cryptographic-i-pdu=false, use-secured-pdu-header=NO-HEADER
  service instance collection set EBCM_ETH_Ethernet_1_connector2_Eth_v23_SvcInstanceCollectionSet
    5 x consumed service instance, all with major-version=1, instance-identifier=1, minor-version=4294967295, version-driven-find-behavior=EXACT-OR-ANY-MINOR-VERSION:
      hcSVC_CnsldtnSecEBST_0D8B_EBCM_ETH_Eth_v23_CSI: local-unicast-addresss=EBCM_ETH_Eth2_Eth_v23_50003_AEP, sd-client-timer-configs=SDClientSvcInstCfg_hcSVC_CnsldtnSecEBST_0D8B_EBCM_ETH_Eth_v23, service-identifier=3467
        consumed event group CEG_EvntGrp_hcSVC_CnsldtnSecEBST_evt_8001: auto-require=true, event-group-identifier=32769, priority=0, sd-client-timer-configs=SDClientEvtGrpTimCfg_hcSVC_CnsldtnSecEBST_evt_8001
          pdu activation routing group SoAdARg_EvntGrp_hcSVC_CnsldtnSecEBST_evt_8001: event-group-control-type=ACTIVATION-UNICAST, i-pdu-identifier-udp=HC_0D8B8001_MechatronicsT1S_Eth2_EBCM_ETH_Identifier
      Act_amSVC_ActvnMngrVehStBkup_itsEBCM_ETH_Eth_v23_0E9C_C: local-unicast-addresss=EBCM_ETH_Eth2_Eth_v23_50000_AEP, sd-client-timer-configs=SDClientSvcInstCfg_Act_amSVC_ActvnMngrVehStBkup_itsEBCM_ETH_Eth_v23_0E9C, service-identifier=3740
      Act_amSVC_ActvnMngrVehSt_itsEBCM_ETH_Eth_v23_0E9B_C: local-unicast-addresss=EBCM_ETH_Eth2_Eth_v23_50000_AEP, sd-client-timer-configs=SDClientSvcInstCfg_Act_amSVC_ActvnMngrVehSt_itsEBCM_ETH_Eth_v23_0E9B, service-identifier=3739
      Act_amSVC_ActvnMngrBrakes_itsEBCM_ETH_Eth_v23_0E8F_C: local-unicast-addresss=EBCM_ETH_Eth2_Eth_v23_50000_AEP, sd-client-timer-configs=SDClientSvcInstCfg_Act_amSVC_ActvnMngrBrakes_itsEBCM_ETH_Eth_v23_0E8F, service-identifier=3727
      DummyService_DO_NOT_ENABLE_Eth_v23_50000_C: local-unicast-addresss=EBCM_ETH_Eth2_Eth_v23_50000_AEP, sd-client-timer-configs=SDClientSvcInstCfg_DummyService_DO_NOT_ENABLE_Eth_v23_50000, service-identifier=65520
        consumed event group CEG_EvntGrp_DummyService_DO_NOT_ENABLE_Eth_v23_50000: auto-require=false, event-group-identifier=1, priority=0, sd-client-timer-configs=SDClientEvtGrpTimCfg_DummyService_DO_NOT_ENABLE_Eth_v23_50000
          pdu activation routing group SoAdARg_EvntGrp_DummyService_DO_NOT_ENABLE_Eth_v23_50000: event-group-control-type=ACTIVATION-UNICAST, i-pdu-identifier-udp=DummyService_DO_NOT_ENABLE_Eth_v23_50000_Identifier
    provided service instance hSVC_eBstActrSec_0C5C_MechatronicsT1S_Eth2_EBCM_ETH_Eth_v23_PSI: major-version=1, instance-identifier=1, local-unicast-addresss=EBCM_ETH_Eth2_Eth_v23_50003_AEP, minor-version=0, sd-server-timer-configs=SDServerSvcInstCfg_hSVC_eBstActrSec_0C5C_MechatronicsT1S_Eth2_EBCM_ETH_Eth_v23, service-identifier=3164
      event handler EH_EvntGrp_hSVC_eBstActrSec_evt_8001: event-group-identifier=32769, sd-server-eg-timing-configs=SDServerEvtGrpTimCfg_hSVC_eBstActrSec_evt_8001
        pdu activation routing group SoAdARg_EvntGrp_hSVC_eBstActrSec_evt_8001: event-group-control-type=ACTIVATION-UNICAST, i-pdu-identifier-udp=H_0C5C8001_MechatronicsT1S_Eth2_EBCM_ETH_Identifier
    provided service instance Act_hSVC_eBstActrPri_EBCM_ETH_Eth_v23_0C5B_P: major-version=1, instance-identifier=1, local-unicast-addresss=EBCM_ETH_Eth2_Eth_v23_50003_AEP, minor-version=0, sd-server-timer-configs=SDServerSvcInstCfg_Act_hSVC_eBstActrPri_EBCM_ETH_Eth_v23_0C5B, service-identifier=3163
    provided service instance Act_hSVC_GEN_INF_EBCM_EBCM_ETH_Eth_v23_1058_P: major-version=1, instance-identifier=1, local-unicast-addresss=EBCM_ETH_Eth2_Eth_v23_50000_AEP, minor-version=0, sd-server-timer-configs=SDServerSvcInstCfg_Act_hSVC_GEN_INF_EBCM_EBCM_ETH_Eth_v23_1058, service-identifier=4184
package /Topologies/SDV/Ethernet_1/v52
  general purpose i pdu GPDU_EBCM_ETH_Eth1_Eth_v52_XCP_Request_From_TT3_To_EBCM_ETH_InVehicle: category=XCP, length=1448
  general purpose i pdu GPDU_EBCM_ETH_Eth1_Eth_v52_XCP_Request_From_TT8_To_EBCM_ETH_InVehicle: category=XCP, length=1448
  general purpose i pdu GPDU_EBCM_ETH_Eth1_Eth_v52_XCP_Response_From_EBCM_ETH_To_TT3_InVehicle: category=XCP, length=1448
  general purpose i pdu GPDU_EBCM_ETH_Eth1_Eth_v52_XCP_Response_From_EBCM_ETH_To_TT8_InVehicle: category=XCP, length=1448
package /Topologies/SDV/ImplementationTypes
  13 x impl type:
    ImpBoolean: category=VALUE, base-type=uint8
    ImpEnum: category=VALUE, base-type=uint8
    ImpSint16: category=VALUE, base-type=sint16
    ImpUint16: category=VALUE, base-type=uint16
    ImpUint64: category=VALUE, base-type=uint64
    ImpUint8: category=VALUE, base-type=uint8
    SrlDat636: category=STRUCTURE
      10 x element, all with category=TYPE_REFERENCE:
        BrkSysPriBrkModToSecBrkModRtnRq: implementation-data-type=ImpEnum
        HydrlcBrkFncStatAchvd: implementation-data-type=ImpEnum
        LtElecPrkBrkActrAppStat: implementation-data-type=ImpEnum
        MnAutoCtlrBrkOprtlModeReq: implementation-data-type=ImpEnum
        MstrCylPistnTrvlCalcd: implementation-data-type=ImpSint16
        MstrCylPistnTrvlCalcdSts: implementation-data-type=ImpEnum
        PriBrkModFncTstTypActv: implementation-data-type=ImpEnum
        RtElecPrkBrkActrAppStat: implementation-data-type=ImpEnum
        SrlDat636_ARC: implementation-data-type=ImplementationTypes/ImpUint8
        SrlDat636_CRC: implementation-data-type=ImplementationTypes/ImpUint8
    SrlDat637: category=STRUCTURE
      element BrkSysPriBrkModRtnCrdntn: implementation-data-type=ImpUint64
      element SrlDat637_ARC: implementation-data-type=ImplementationTypes/ImpUint8
      element SrlDat637_CRC: implementation-data-type=ImplementationTypes/ImpUint8
    SrlDat638: category=STRUCTURE
      10 x element, all with category=TYPE_REFERENCE:
        BrkSysSecBrkModRtnAvalFlg{1..7}: implementation-data-type=ImpBoolean
        SecElecPrkBrkCmd: implementation-data-type=ImpEnum
        SrlDat638_ARC: implementation-data-type=ImplementationTypes/ImpUint8
        SrlDat638_CRC: implementation-data-type=ImplementationTypes/ImpUint8
    SrlDat639: category=STRUCTURE
      element BrkSysSecBrkModRtnCrdntn: implementation-data-type=ImpUint64
      element SrlDat639_ARC: implementation-data-type=ImplementationTypes/ImpUint8
      element SrlDat639_CRC: implementation-data-type=ImplementationTypes/ImpUint8
    SrlDat673: category=STRUCTURE
      15 x element, all with category=TYPE_REFERENCE:
        HSV1DiagActFltd: implementation-data-type=ImpBoolean
        HSV2DiagActFltd: implementation-data-type=ImpBoolean
        PmpMtrDiagActFltd: implementation-data-type=ImpBoolean
        RedntElecPrkBrkCmd: implementation-data-type=ImpEnum
        RedntWhlAnglrVelLF: implementation-data-type=ImplementationTypes/ImpUint16
        RedntWhlAnglrVelRF: implementation-data-type=ImplementationTypes/ImpUint16
        RedntWhlSpdSnsr_InvLF: implementation-data-type=ImpBoolean
        RedntWhlSpdSnsr_InvRF: implementation-data-type=ImpBoolean
        RmtActModeActv: implementation-data-type=ImpBoolean
        SBMRmtActFltd: implementation-data-type=ImpBoolean
        SBMSlfTstInfo: implementation-data-type=ImpEnum
        SrlDat673_ARC: implementation-data-type=ImplementationTypes/ImpUint8
        SrlDat673_CRC: implementation-data-type=ImplementationTypes/ImpUint8
        USV1DiagActFltd: implementation-data-type=ImpBoolean
        USV2DiagActFltd: implementation-data-type=ImpBoolean
    SrlDat674: category=STRUCTURE
      6 x element, all with category=TYPE_REFERENCE:
        RedntWhlAnglrVelLR: implementation-data-type=ImplementationTypes/ImpUint16
        RedntWhlAnglrVelRR: implementation-data-type=ImplementationTypes/ImpUint16
        RedntWhlSpdSnsr_InvLR: implementation-data-type=ImpBoolean
        RedntWhlSpdSnsr_InvRR: implementation-data-type=ImpBoolean
        SrlDat674_ARC: implementation-data-type=ImplementationTypes/ImpUint8
        SrlDat674_CRC: implementation-data-type=ImplementationTypes/ImpUint8
    SrlDat675: category=STRUCTURE
      8 x element, all with category=TYPE_REFERENCE:
        EBCMSlfTstInfo: implementation-data-type=ImpEnum
        HSV1DiagActPctg: implementation-data-type=ImplementationTypes/ImpUint8
        HSV2DiagActPctg: implementation-data-type=ImplementationTypes/ImpUint8
        PmpMtrDiagActSpdCmd: implementation-data-type=ImplementationTypes/ImpUint16
        SrlDat675_ARC: implementation-data-type=ImplementationTypes/ImpUint8
        SrlDat675_CRC: implementation-data-type=ImplementationTypes/ImpUint8
        USV1DiagActPctg: implementation-data-type=ImplementationTypes/ImpUint8
        USV2DiagActPctg: implementation-data-type=ImplementationTypes/ImpUint8
